VERSION ""

NS_ :

BS_:

BU_: TCM HCM IPMA_ADAS PSCM ABS_ESC TCCM TCM_DSL PCM_HEV PCM ECM_HEVDSL ECM_HEV ECM_Diesel ECM SIMA_DLCS BCMD_IPDB VDM CMR_DSMC SOBDMC_HPCM CHCM GWM _delete AWD_DLCM GENERIC TSTR

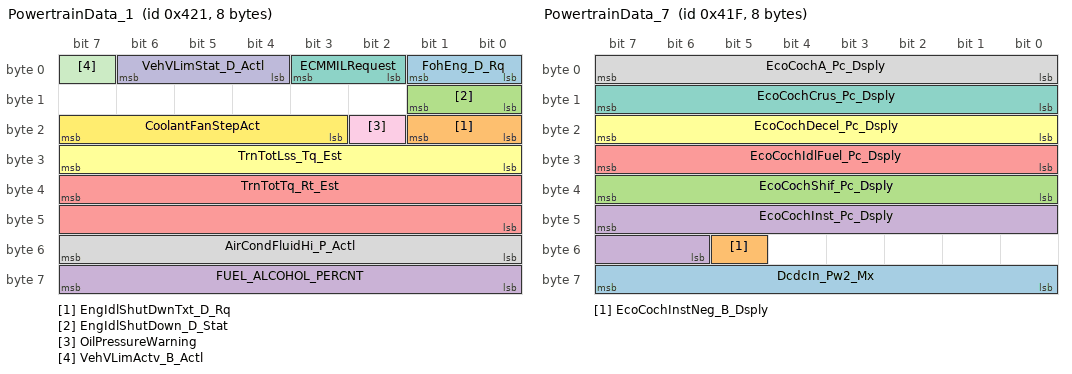
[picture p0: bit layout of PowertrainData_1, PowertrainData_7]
BO_ 1057 PowertrainData_1: 8 PCM_HEV
 SG_ FohEng_D_Rq : 1|2@0+ (1,0) [0|3] "SED"  GWM
 SG_ EngIdlShutDwnTxt_D_Rq : 17|2@0+ (1,0) [0|3] "SED"  GWM
 SG_ EngIdlShutDown_D_Stat : 9|2@0+ (1,0) [0|3] "SED"  GWM
 SG_ FUEL_ALCOHOL_PERCNT : 63|8@0+ (0.393700787,0) [0|99.999899898] "Percent"  GWM
 SG_ TrnTotTq_Rt_Est : 39|16@0+ (0.001,0) [0|65.533] "Unitless"  ABS_ESC,TCM,GWM,TCM_DSL
 SG_ TrnTotLss_Tq_Est : 31|8@0+ (0.5,0) [0|126.5] "Nm"  ABS_ESC,TCM,GWM,TCM_DSL
 SG_ ECMMILRequest : 3|2@0+ (1,0) [0|3] "SED"  GWM
 SG_ AirCondFluidHi_P_Actl : 55|8@0+ (0.125,0) [0|31.625] "bar"  SOBDMC_HPCM,GWM
 SG_ OilPressureWarning : 18|1@0+ (1,0) [0|1] "SED"  GWM
 SG_ VehVLimStat_D_Actl : 6|3@0+ (1,0) [0|7] "SED"  TCM,GWM,TCM_DSL
 SG_ VehVLimActv_B_Actl : 7|1@0+ (1,0) [0|1] "SED"  SOBDMC_HPCM,TCM,GWM,TCM_DSL
 SG_ CoolantFanStepAct : 23|5@0+ (1,0) [0|31] "Steps"  GWM

BO_ 1055 PowertrainData_7: 8 PCM_HEV
 SG_ DcdcIn_Pw2_Mx : 63|8@0+ (20,500) [500|5600] "watts"  GWM
 SG_ EcoCochInstNeg_B_Dsply : 53|1@0+ (1,0) [0|1] "SED"  GWM
 SG_ EcoCochShif_Pc_Dsply : 39|8@0+ (0.392157,0) [0|100.000035] "percent"  GWM
 SG_ EcoCochInst_Pc_Dsply : 47|10@0+ (0.1,0) [0|102.3] "percent"  GWM
 SG_ EcoCochIdlFuel_Pc_Dsply : 31|8@0+ (0.392157,0) [0|100.000035] "percent"  GWM
 SG_ EcoCochDecel_Pc_Dsply : 23|8@0+ (0.392157,0) [0|100.000035] "percent"  GWM
 SG_ EcoCochCrus_Pc_Dsply : 15|8@0+ (0.392157,0) [0|100.000035] "percent"  GWM
 SG_ EcoCochA_Pc_Dsply : 7|8@0+ (0.392157,0) [0|100.000035] "percent"  GWM

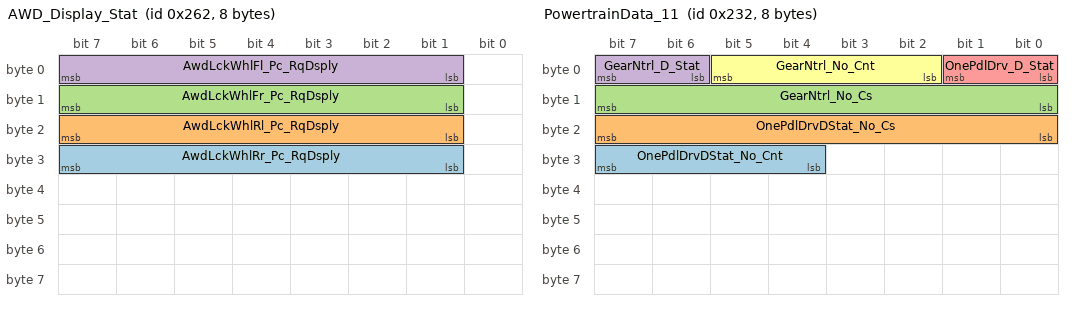
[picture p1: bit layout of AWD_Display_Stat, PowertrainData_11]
BO_ 610 AWD_Display_Stat: 8 AWD_DLCM
 SG_ AwdLckWhlRr_Pc_RqDsply : 31|7@0+ (1,0) [0|127] "percent"  GWM
 SG_ AwdLckWhlRl_Pc_RqDsply : 23|7@0+ (1,0) [0|127] "percent"  GWM
 SG_ AwdLckWhlFr_Pc_RqDsply : 15|7@0+ (1,0) [0|127] "percent"  GWM
 SG_ AwdLckWhlFl_Pc_RqDsply : 7|7@0+ (1,0) [0|127] "percent"  GWM

BO_ 562 PowertrainData_11: 8 ECM
 SG_ OnePdlDrvDStat_No_Cnt : 31|4@0+ (1,0) [0|15] "Unitless"  ABS_ESC,SOBDMC_HPCM
 SG_ OnePdlDrvDStat_No_Cs : 23|8@0+ (1,0) [0|255] "Unitless"  ABS_ESC,SOBDMC_HPCM
 SG_ GearNtrl_No_Cs : 15|8@0+ (1,0) [0|255] "unitless"  ABS_ESC,GWM
 SG_ GearNtrl_D_Stat : 7|2@0+ (1,0) [0|3] "SED"  ABS_ESC,GWM
 SG_ OnePdlDrv_D_Stat : 1|2@0+ (1,0) [0|3] "SED"  ABS_ESC,SOBDMC_HPCM
 SG_ GearNtrl_No_Cnt : 5|4@0+ (1,0) [0|15] "unitless"  ABS_ESC,GWM

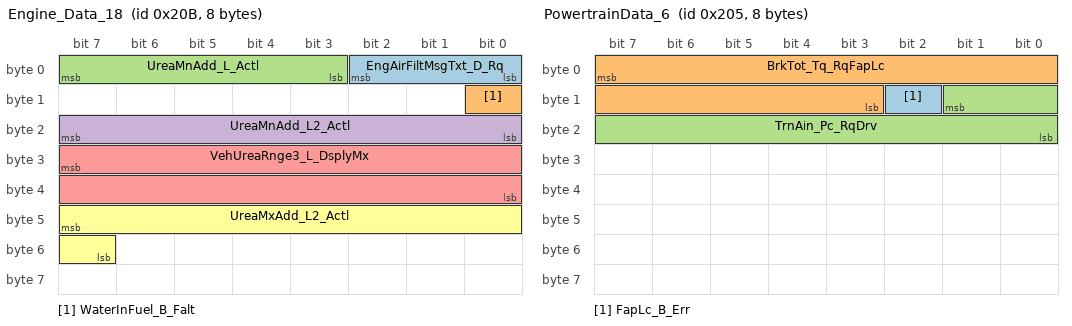
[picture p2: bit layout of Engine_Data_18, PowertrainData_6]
BO_ 523 Engine_Data_18: 8 PCM
 SG_ EngAirFiltMsgTxt_D_Rq : 2|3@0+ (1,0) [0|7] "SED"  GWM
 SG_ WaterInFuel_B_Falt : 8|1@0+ (1,0) [0|1] "SED"  GWM
 SG_ UreaMnAdd_L_Actl : 7|5@0+ (1,0) [0|31] "litre"  GWM
 SG_ UreaMnAdd_L2_Actl : 23|8@0+ (0.1,0) [0|25.4] "litre"  GWM
 SG_ VehUreaRnge3_L_DsplyMx : 31|16@0+ (1,0) [0|65535] "unitless"  GWM
 SG_ UreaMxAdd_L2_Actl : 47|9@0+ (0.1,0) [0|51] "litre"  GWM

BO_ 519 PowertrainData_8: 8 ECM
 SG_ RearDiffLck_Tq_Rq : 7|14@0+ (1,0) [0|16381] "Nm"  GWM

BO_ 517 PowertrainData_6: 8 PCM_HEV
 SG_ FapLc_B_Err : 10|1@0+ (1,0) [0|1] "SED"  IPMA_ADAS,GWM
 SG_ BrkTot_Tq_RqFapLc : 7|13@0+ (4,0) [0|32764] "Nm"  ABS_ESC,GWM
 SG_ TrnAin_Pc_RqDrv : 9|10@0+ (0.1,0) [0|102.3] "percent"  GWM,AWD_DLCM,TCCM

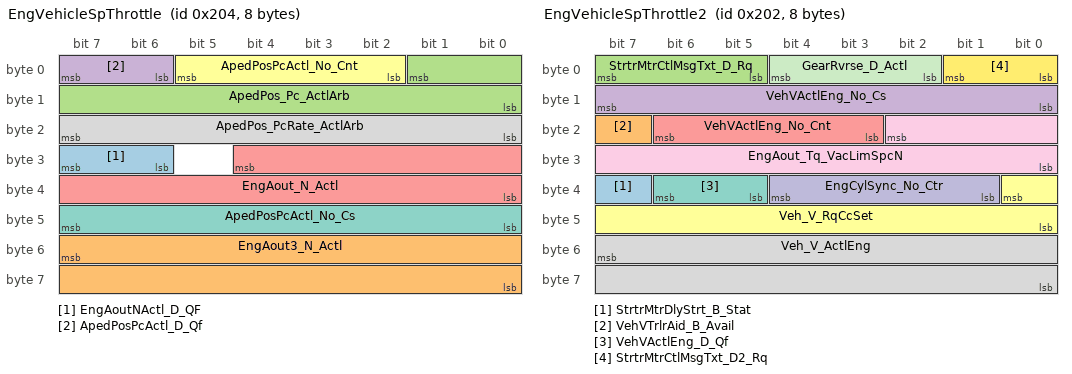
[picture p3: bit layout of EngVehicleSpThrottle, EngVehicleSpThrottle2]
BO_ 516 EngVehicleSpThrottle: 8 PCM_HEV
 SG_ EngAoutNActl_D_QF : 31|2@0+ (1,0) [0|3] "SED"  TCM,TCM_DSL,GWM
 SG_ EngAout3_N_Actl : 55|16@0+ (0.25,0) [0|16383.5] "RPM"  SOBDMC_HPCM,GWM
 SG_ ApedPos_Pc_ActlArb : 1|10@0+ (0.1,0) [0|102.3] "%"  TCM,CMR_DSMC,VDM,SOBDMC_HPCM,HCM,IPMA_ADAS,TCCM,ABS_ESC,PSCM,TCM_DSL,GWM,AWD_DLCM
 SG_ ApedPosPcActl_D_Qf : 7|2@0+ (1,0) [0|3] "SED"  CMR_DSMC,TCM,VDM,SOBDMC_HPCM,HCM,IPMA_ADAS,ABS_ESC,PSCM,TCM_DSL,GWM,AWD_DLCM
 SG_ EngAout_N_Actl : 28|13@0+ (2,0) [0|16382] "rpm"  TCM,VDM,HCM,ABS_ESC,PSCM,TCCM,TCM_DSL,GWM,AWD_DLCM
 SG_ ApedPosPcActl_No_Cnt : 5|4@0+ (1,0) [0|15] "Unitless"  TCM,SOBDMC_HPCM,ABS_ESC,TCM_DSL,GWM
 SG_ ApedPosPcActl_No_Cs : 47|8@0+ (1,0) [0|255] "Unitless"  TCM,SOBDMC_HPCM,ABS_ESC,TCM_DSL,GWM
 SG_ ApedPos_PcRate_ActlArb : 23|8@0+ (0.04,-5) [-5|5.12] "%/ms"  SOBDMC_HPCM,AWD_DLCM,TCM,TCM_DSL,GWM

BO_ 514 EngVehicleSpThrottle2: 8 PCM_HEV
 SG_ StrtrMtrDlyStrt_B_Stat : 39|1@0+ (1,0) [0|1] "SED"  GWM
 SG_ VehVTrlrAid_B_Avail : 23|1@0+ (1,0) [0|1] "SED"  PSCM,GWM
 SG_ StrtrMtrCtlMsgTxt_D_Rq : 7|3@0+ (1,0) [0|7] "SED"  GWM
 SG_ VehVActlEng_No_Cs : 15|8@0+ (1,0) [0|255] "Unitless"  ABS_ESC,PSCM,GWM
 SG_ VehVActlEng_No_Cnt : 22|4@0+ (1,0) [0|15] "Unitless"  ABS_ESC,PSCM,GWM
 SG_ Veh_V_RqCcSet : 32|9@0+ (0.5,0) [0|255.5] "kph"  TCM,IPMA_ADAS,PSCM,ABS_ESC,TCM_DSL,GWM,SOBDMC_HPCM
 SG_ VehVActlEng_D_Qf : 38|2@0+ (1,0) [0|3] "SED"  TCM,HCM,IPMA_ADAS,ABS_ESC,PSCM,TCM_DSL,GWM,VDM,AWD_DLCM
 SG_ Veh_V_ActlEng : 55|16@0+ (0.01,0) [0|655.35] "kph"  TCM,SOBDMC_HPCM,HCM,IPMA_ADAS,ABS_ESC,PSCM,TCM_DSL,VDM,GWM,AWD_DLCM
 SG_ EngAout_Tq_VacLimSpcN : 18|11@0+ (1,-500) [-500|1547] "Nm"  SOBDMC_HPCM,GWM
 SG_ EngCylSync_No_Ctr : 36|4@0+ (1,0) [0|15] "unitless"  SOBDMC_HPCM,GWM
 SG_ GearRvrse_D_Actl : 4|3@0+ (1,0) [0|7] "SED"  AWD_DLCM,IPMA_ADAS,CMR_DSMC,ABS_ESC,PSCM,GWM,VDM,HCM,CHCM
 SG_ StrtrMtrCtlMsgTxt_D2_Rq : 1|2@0+ (1,0) [0|3] "SED"  GWM

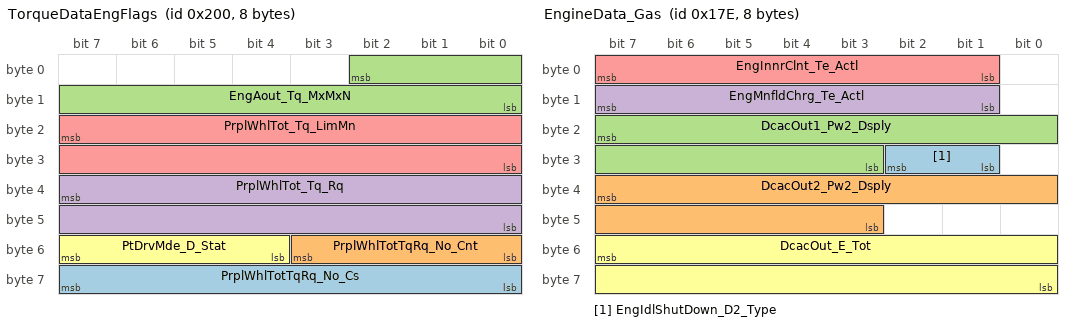
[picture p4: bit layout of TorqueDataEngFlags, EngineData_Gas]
BO_ 512 TorqueDataEngFlags: 8 PCM_HEV
 SG_ PrplWhlTotTqRq_No_Cs : 63|8@0+ (1,0) [0|255] "Unitless"  SOBDMC_HPCM,ABS_ESC,GWM
 SG_ PrplWhlTotTqRq_No_Cnt : 51|4@0+ (1,0) [0|15] "Unitless"  SOBDMC_HPCM,ABS_ESC,GWM
 SG_ EngAout_Tq_MxMxN : 2|11@0+ (1,-500) [-500|1547] "Nm"  SOBDMC_HPCM,GWM
 SG_ PrplWhlTot_Tq_Rq : 39|16@0+ (4,-131072) [-131072|131068] "Nm"  VDM,SOBDMC_HPCM,TCCM,ABS_ESC,GWM,AWD_DLCM
 SG_ PrplWhlTot_Tq_LimMn : 23|16@0+ (4,-131072) [-131072|131068] "Nm"  ABS_ESC,GWM
 SG_ PtDrvMde_D_Stat : 55|4@0+ (1,0) [0|15] "SED"  IPMA_ADAS,ABS_ESC,GWM

BO_ 382 EngineData_Gas: 8 ECM_HEV
 SG_ EngIdlShutDown_D2_Type : 26|2@0+ (1,0) [0|3] "SED"  GWM
 SG_ DcacOut2_Pw2_Dsply : 39|13@0+ (1,0) [0|8189] "watts"  GWM
 SG_ DcacOut1_Pw2_Dsply : 23|13@0+ (1,0) [0|8189] "watts"  GWM
 SG_ EngMnfldChrg_Te_Actl : 15|7@0+ (1,-20) [-20|105] "degC"  GWM
 SG_ EngInnrClnt_Te_Actl : 7|7@0+ (1,50) [50|175] "degC"  GWM
 SG_ DcacOut_E_Tot : 55|16@0+ (20,0) [0|1310700] "watt*hour"  GWM

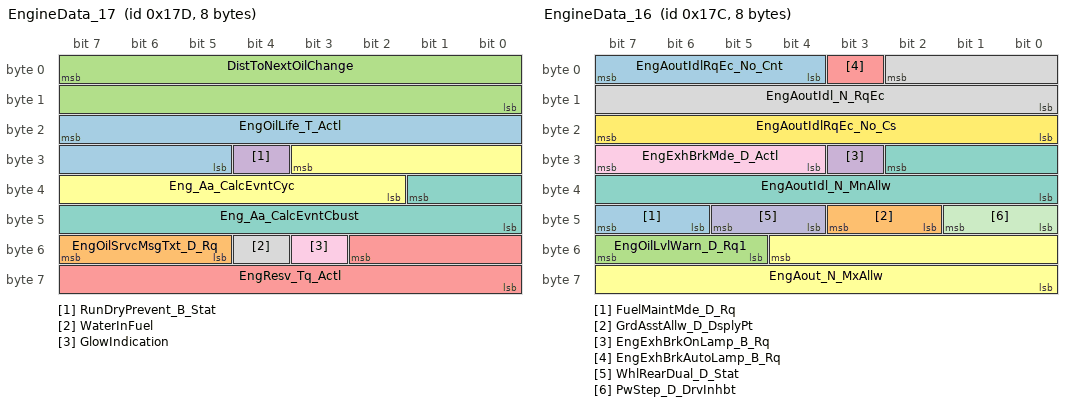
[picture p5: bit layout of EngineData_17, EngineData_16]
BO_ 381 EngineData_17: 8 ECM_HEVDSL
 SG_ EngOilLife_T_Actl : 23|11@0+ (1,0) [0|2047] "days"  GWM
 SG_ EngOilSrvcMsgTxt_D_Rq : 55|3@0+ (1,0) [0|7] "SED"  GWM
 SG_ DistToNextOilChange : 7|16@0+ (1,0) [0|65535] "unitless"  GWM
 SG_ RunDryPrevent_B_Stat : 28|1@0+ (1,0) [0|1] "SED"  GWM
 SG_ EngResv_Tq_Actl : 50|11@0+ (1,-500) [-500|1547] "Nm"  GWM
 SG_ Eng_Aa_CalcEvntCyc : 27|10@0+ (0.05,-25.6) [-25.6|25.55] "rpm/ms"  GWM
 SG_ Eng_Aa_CalcEvntCbust : 33|10@0+ (0.05,-25.6) [-25.6|25.55] "rpm/ms"  GWM
 SG_ WaterInFuel : 52|1@0+ (1,0) [0|1] "SED"  GWM
 SG_ GlowIndication : 51|1@0+ (1,0) [0|1] "SED"  GWM

BO_ 380 EngineData_16: 8 PCM
 SG_ FuelMaintMde_D_Rq : 47|2@0+ (1,0) [0|3] "SED"  SOBDMC_HPCM,GWM
 SG_ GrdAsstAllw_D_DsplyPt : 43|2@0+ (1,0) [0|3] "SED"  SOBDMC_HPCM,GWM
 SG_ EngOilLvlWarn_D_Rq1 : 55|3@0+ (1,0) [0|7] "SED"  PCM,GWM,PCM_HEV
 SG_ EngExhBrkOnLamp_B_Rq : 27|1@0+ (1,0) [0|1] "SED"  GWM
 SG_ EngExhBrkAutoLamp_B_Rq : 3|1@0+ (1,0) [0|1] "SED"  GWM
 SG_ EngAout_N_MxAllw : 52|13@0+ (2,0) [0|16382] "rpm"  TCM,SOBDMC_HPCM,TCM_DSL,GWM
 SG_ EngAoutIdl_N_MnAllw : 26|11@0+ (2,0) [0|4094] "rpm"  GWM
 SG_ EngAoutIdl_N_RqEc : 2|11@0+ (2,0) [0|4094] "rpm"  GWM
 SG_ EngExhBrkMde_D_Actl : 31|4@0+ (1,0) [0|15] "SED"  TCM,TCM_DSL,GWM
 SG_ WhlRearDual_D_Stat : 45|2@0+ (1,0) [0|3] "SED"  TCM,TCM_DSL,GWM
 SG_ PwStep_D_DrvInhbt : 41|2@0+ (1,0) [0|3] "SED"  GWM
 SG_ EngAoutIdlRqEc_No_Cs : 23|8@0+ (1,0) [0|255] "unitless"  GWM
 SG_ EngAoutIdlRqEc_No_Cnt : 7|4@0+ (1,0) [0|15] "unitless"  GWM

BO_ 377 EngineData_7: 8 PCM_HEV
 SG_ HvacAirFullOut_B_Rq : 23|1@0+ (1,0) [0|1] "SED"  GWM
 SG_ TrnManShif_D_IndDrv : 7|3@0+ (1,0) [0|7] "Unitless"  GWM
 SG_ EngAout_Tq_Actl : 2|11@0+ (1,-500) [-500|1547] "Nm"  SOBDMC_HPCM,GWM
 SG_ TrnManShifGear_D_IndDrv : 54|3@0+ (1,0) [0|7] "SED"  GWM
 SG_ EngFuelCutFull_B_Inhbt : 22|1@0+ (1,0) [0|1] "SED"  SOBDMC_HPCM,GWM
 SG_ EngDecelFuelCut_B_Allw : 21|1@0+ (1,0) [0|1] "SED"  TCM,TCM_DSL,GWM
 SG_ FuelFlw_Vl_Dsply : 49|10@0+ (25,0) [0|25575] "Micro_Liter"  SOBDMC_HPCM,GWM
 SG_ FuelFillInlet_B_Dsply : 32|1@0+ (1,0) [0|1] "SED"  GWM
 SG_ EngSrvcRqd_B_Rq : 19|1@0+ (1,0) [0|1] "SED"  GWM
 SG_ OdoCount : 47|8@0+ (0.2,0) [0|50.8] "Meters"  GWM
 SG_ EngOilLife_Pc_Actl : 39|7@0+ (1,0) [0|100] "Percent"  GWM
 SG_ EngTqSlwDly_T_Est : 18|11@0+ (1,0) [0|2047] "ms"  TCM,TCM_DSL,GWM
 SG_ TrnKickDown_B_RqDrv : 20|1@0+ (1,0) [0|1] "SED"  TCM,TCM_DSL,GWM
 SG_ FuelFilterLamp_B_Dsply : 50|1@0+ (1,0) [0|1] "SED"  GWM
 SG_ AirCondRec_B_Rq : 55|1@0+ (1,0) [0|1] "SED"  GWM
 SG_ AirCondClutch_B_Stats : 51|1@0+ (1,0) [0|1] "SED"  TCM,TCM_DSL,GWM
 SG_ EngAoutTqActl_D_Qf : 4|2@0+ (1,0) [0|3] "SED"  SOBDMC_HPCM,GWM

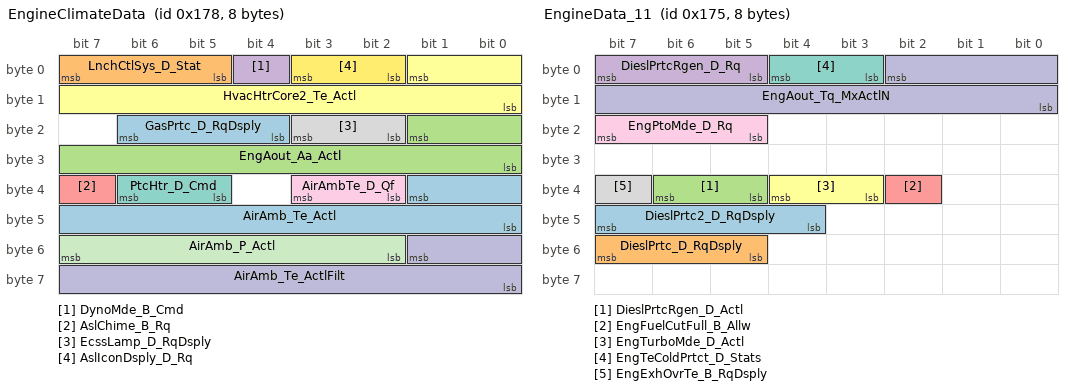
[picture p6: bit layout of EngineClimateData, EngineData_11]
BO_ 376 EngineClimateData: 8 PCM_HEV
 SG_ GasPrtc_D_RqDsply : 22|3@0+ (1,0) [0|7] "SED"  GWM
 SG_ LnchCtlSys_D_Stat : 7|3@0+ (1,0) [0|7] "SED"  ABS_ESC,GWM
 SG_ EngAout_Aa_Actl : 17|10@0+ (0.05,-25.6) [-25.6|25.55] "rpm/ms"  TCM,TCM_DSL,ABS_ESC,GWM
 SG_ DynoMde_B_Cmd : 4|1@0+ (1,0) [0|1] "SED"  SOBDMC_HPCM,TCM,TCM_DSL,ABS_ESC,GWM
 SG_ AslChime_B_Rq : 39|1@0+ (1,0) [0|1] "SED"  GWM
 SG_ HvacHtrCore2_Te_Actl : 1|10@0+ (0.25,-50) [-50|205.5] "degC"  SOBDMC_HPCM,GWM
 SG_ PtcHtr_D_Cmd : 38|2@0+ (1,0) [0|3] "SED"  SOBDMC_HPCM,GWM
 SG_ EcssLamp_D_RqDsply : 19|2@0+ (1,0) [0|3] "SED"  GWM
 SG_ AirAmbTe_D_Qf : 35|2@0+ (1,0) [0|3] "SED"  TCM,SOBDMC_HPCM,IPMA_ADAS,TCM_DSL,ABS_ESC,TCCM,GWM,VDM,AWD_DLCM,CHCM
 SG_ AirAmb_Te_ActlFilt : 49|10@0+ (0.25,-128) [-128|127.75] "deg C"  TCM,SOBDMC_HPCM,IPMA_ADAS,TCM_DSL,VDM,GWM,CHCM
 SG_ AirAmb_P_Actl : 55|6@0+ (10,500) [500|1110] "mbar"  TCM,TCM_DSL,ABS_ESC,GWM,VDM
 SG_ AslIconDsply_D_Rq : 3|2@0+ (1,0) [0|3] "SED"  IPMA_ADAS,GWM
 SG_ AirAmb_Te_Actl : 33|10@0+ (0.25,-128) [-128|127.75] "degC"  VDM,TCM_DSL,TCM,TCCM,HCM,AWD_DLCM,ABS_ESC,GWM,CHCM

BO_ 373 EngineData_11: 8 ECM_HEVDSL
 SG_ DieslPrtc2_D_RqDsply : 47|4@0+ (1,0) [0|15] "SED"  GWM
 SG_ DieslPrtc_D_RqDsply : 55|3@0+ (1,0) [0|7] "SED"  GWM
 SG_ DieslPrtcRgen_D_Actl : 38|2@0+ (1,0) [0|3] "SED"  TCM,TCM_DSL,GWM
 SG_ DieslPrtcRgen_D_Rq : 7|3@0+ (1,0) [0|7] "SED"  GWM
 SG_ EngFuelCutFull_B_Allw : 34|1@0+ (1,0) [0|1] "SED"  SOBDMC_HPCM,GWM
 SG_ EngTurboMde_D_Actl : 36|2@0+ (1,0) [0|3] "SED"  TCM,TCM_DSL,GWM
 SG_ EngTeColdPrtct_D_Stats : 4|2@0+ (1,0) [0|3] "SED"  GWM
 SG_ EngExhOvrTe_B_RqDsply : 39|1@0+ (1,0) [0|1] "SED"  GWM
 SG_ EngPtoMde_D_Rq : 23|3@0+ (1,0) [0|7] "SED"  TCM,TCM_DSL,GWM
 SG_ EngAout_Tq_MxActlN : 2|11@0+ (1,-500) [-500|1547] "Nm"  GWM,GENERIC

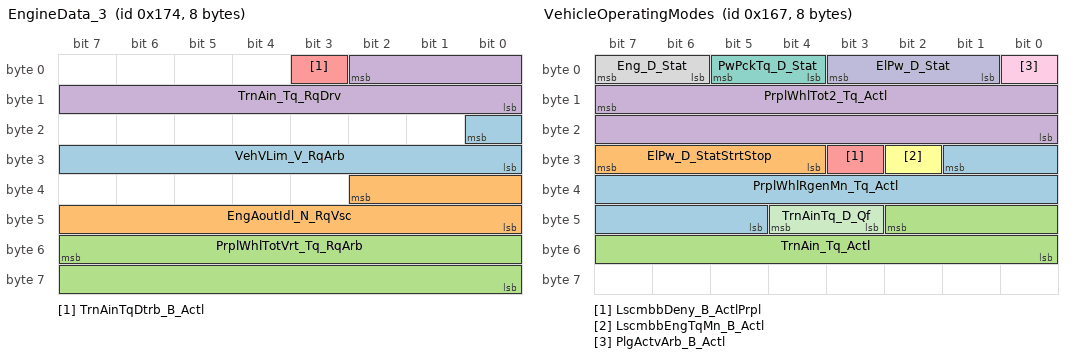
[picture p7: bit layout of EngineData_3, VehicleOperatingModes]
BO_ 372 EngineData_3: 8 ECM
 SG_ VehVLim_V_RqArb : 16|9@0+ (0.5,0) [0|255.5] "kph"  TCM,TCM_DSL,GWM
 SG_ EngAoutIdl_N_RqVsc : 34|11@0+ (2,0) [0|4094] "rpm"  TCM,TCM_DSL,ABS_ESC,GWM
 SG_ PrplWhlTotVrt_Tq_RqArb : 55|16@0+ (4,-131072) [-131072|131068] "Nm"  TCM,TCM_DSL,GWM
 SG_ TrnAin_Tq_RqDrv : 2|11@0+ (1,-500) [-500|1547] "Nm"  TCM,TCM_DSL,GWM
 SG_ TrnAinTqDtrb_B_Actl : 3|1@0+ (1,0) [0|1] "SED"  TCM,TCM_DSL,GWM

BO_ 359 VehicleOperatingModes: 8 PCM_HEV
 SG_ PrplWhlRgenMn_Tq_Actl : 25|13@0+ (4,-16380) [-16380|16380] "Nm"  ABS_ESC,GWM,AWD_DLCM
 SG_ ElPw_D_StatStrtStop : 31|4@0+ (1,0) [0|15] "SED"  PSCM,GWM,ABS_ESC
 SG_ TrnAin_Tq_Actl : 42|11@0+ (1,-500) [-500|1547] "Nm"  TCM,ABS_ESC,TCM_DSL,GWM,AWD_DLCM
 SG_ PrplWhlTot2_Tq_Actl : 15|16@0+ (4,-131072) [-131072|131060] "Nm"  VDM,ABS_ESC,ECM_HEV,PSCM,TCCM,GWM,AWD_DLCM
 SG_ LscmbbDeny_B_ActlPrpl : 27|1@0+ (1,0) [0|1] "SED"  ABS_ESC,GWM
 SG_ LscmbbEngTqMn_B_Actl : 26|1@0+ (1,0) [0|1] "SED"  ABS_ESC,GWM
 SG_ PwPckTq_D_Stat : 5|2@0+ (1,0) [0|3] "SED"  TCM,SOBDMC_HPCM,VDM,HCM,IPMA_ADAS,ABS_ESC,ECM_HEV,PSCM,TCCM,TCM_DSL,CMR_DSMC,GWM,AWD_DLCM,CHCM
 SG_ Eng_D_Stat : 7|2@0+ (1,0) [0|3] "SED"  TCM,VDM,ABS_ESC,TCM_DSL,GWM,AWD_DLCM
 SG_ PlgActvArb_B_Actl : 0|1@0+ (1,0) [0|1] "SED"  SOBDMC_HPCM,GWM,ECM_HEV
 SG_ ElPw_D_Stat : 3|3@0+ (1,0) [0|7] "SED"  TCM,VDM,HCM,IPMA_ADAS,ABS_ESC,ECM_HEV,PSCM,TCCM,TCM_DSL,GWM,CMR_DSMC,AWD_DLCM,CHCM
 SG_ TrnAinTq_D_Qf : 44|2@0+ (1,0) [0|3] "SED"  TCM,ABS_ESC,TCM_DSL,GWM,AWD_DLCM

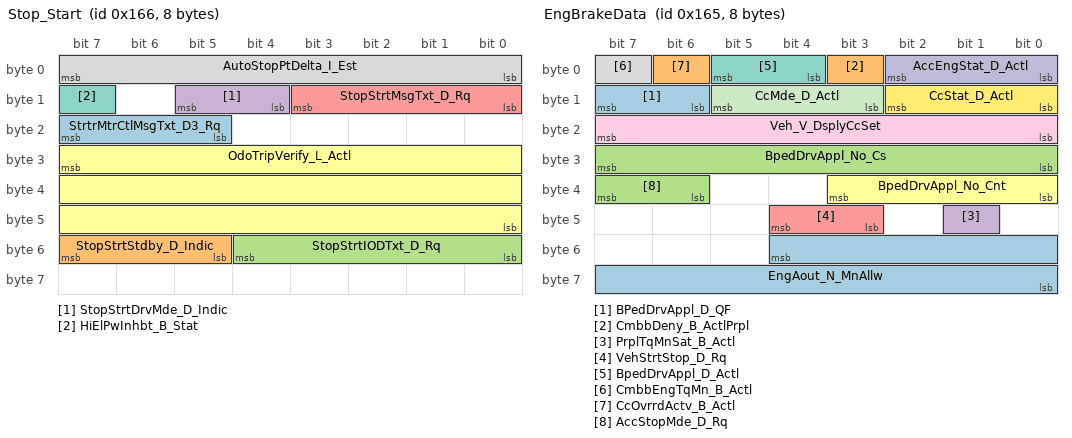
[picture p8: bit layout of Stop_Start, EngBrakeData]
BO_ 358 Stop_Start: 8 PCM_HEV
 SG_ StrtrMtrCtlMsgTxt_D3_Rq : 23|3@0+ (1,0) [0|7] "SED"  GWM
 SG_ StopStrtStdby_D_Indic : 55|3@0+ (1,0) [0|7] "SED"  GWM
 SG_ StopStrtIODTxt_D_Rq : 52|5@0+ (1,0) [0|31] "SED"  GWM
 SG_ StopStrtDrvMde_D_Indic : 13|2@0+ (1,0) [0|3] "SED"  GWM
 SG_ StopStrtMsgTxt_D_Rq : 11|4@0+ (1,0) [0|15] "SED"  GWM
 SG_ OdoTripVerify_L_Actl : 31|24@0+ (0.1,0) [0|1677721.4] "km"  GWM
 SG_ HiElPwInhbt_B_Stat : 15|1@0+ (1,0) [0|1] "SED"  GWM
 SG_ AutoStopPtDelta_I_Est : 7|8@0+ (1,-127) [-127|127] "Amps"  GWM

BO_ 357 EngBrakeData: 8 PCM_HEV
 SG_ BPedDrvAppl_D_QF : 15|2@0+ (1,0) [0|3] "SED"  TCM,SOBDMC_HPCM,IPMA_ADAS,ABS_ESC,PSCM,TCM_DSL,GWM,VDM,CMR_DSMC,AWD_DLCM
 SG_ CmbbDeny_B_ActlPrpl : 3|1@0+ (1,0) [0|1] "SED"  IPMA_ADAS,GWM
 SG_ BpedDrvAppl_No_Cs : 31|8@0+ (1,0) [0|255] "Unitless"  SOBDMC_HPCM,GWM
 SG_ PrplTqMnSat_B_Actl : 41|1@0+ (1,0) [0|1] "SED"  IPMA_ADAS,GWM
 SG_ VehStrtStop_D_Rq : 44|2@0+ (1,0) [0|3] "SED"  SOBDMC_HPCM,GWM
 SG_ BpedDrvAppl_No_Cnt : 35|4@0+ (1,0) [0|15] "Unitless"  SOBDMC_HPCM,GWM
 SG_ BpedDrvAppl_D_Actl : 5|2@0+ (1,0) [0|3] "SED"  TCM,SOBDMC_HPCM,IPMA_ADAS,ABS_ESC,PSCM,TCCM,TCM_DSL,VDM,GWM,CMR_DSMC,AWD_DLCM
 SG_ CmbbEngTqMn_B_Actl : 7|1@0+ (1,0) [0|1] "SED"  IPMA_ADAS,GWM
 SG_ Veh_V_DsplyCcSet : 23|8@0+ (1,0) [0|253] "Unitless"  GWM,IPMA_ADAS
 SG_ AccEngStat_D_Actl : 2|3@0+ (1,0) [0|7] "SED"  IPMA_ADAS,GWM
 SG_ CcMde_D_Actl : 13|3@0+ (1,0) [0|7] "SED"  TCM,TCM_DSL,ABS_ESC,GWM,VDM
 SG_ CcStat_D_Actl : 10|3@0+ (1,0) [0|7] "SED"  TCM,SOBDMC_HPCM,IPMA_ADAS,ABS_ESC,TCCM,TCM_DSL,GWM,CMR_DSMC,AWD_DLCM
 SG_ EngAout_N_MnAllw : 52|13@0+ (2,0) [0|16382] "rpm"  TCM,SOBDMC_HPCM,TCM_DSL,GWM
 SG_ CcOvrrdActv_B_Actl : 6|1@0+ (1,0) [0|1] "SED"  TCM,IPMA_ADAS,ABS_ESC,TCCM,TCM_DSL,GWM,VDM,AWD_DLCM
 SG_ AccStopMde_D_Rq : 39|2@0+ (1,0) [0|3] "SED"  IPMA_ADAS,ABS_ESC,GWM

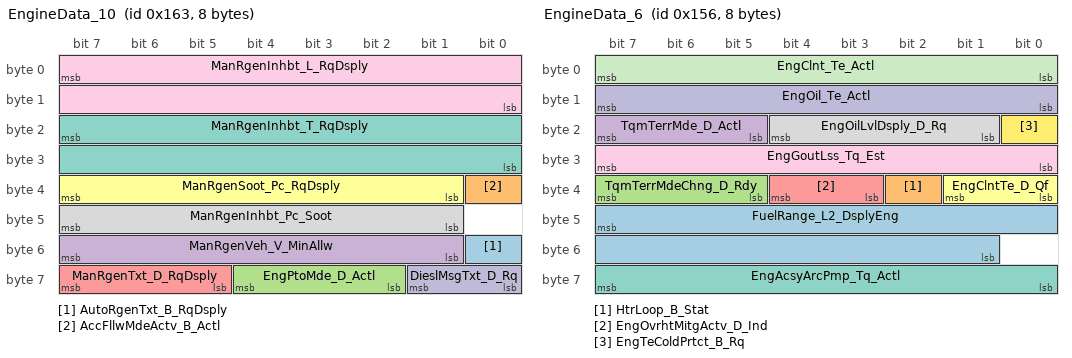
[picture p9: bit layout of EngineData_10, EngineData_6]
BO_ 355 EngineData_10: 8 ECM_HEVDSL
 SG_ AutoRgenTxt_B_RqDsply : 48|1@0+ (1,0) [0|1] "SED"  GWM
 SG_ AccFllwMdeActv_B_Actl : 32|1@0+ (1,0) [0|1] "SED"  TCM,TCM_DSL,GWM
 SG_ EngPtoMde_D_Actl : 60|3@0+ (1,0) [0|7] "SED"  TCM,TCM_DSL,GWM
 SG_ ManRgenVeh_V_MinAllw : 55|7@0+ (1,0) [0|126] "kilometer/hour"  GWM
 SG_ ManRgenTxt_D_RqDsply : 63|3@0+ (1,0) [0|7] "SED"  GWM
 SG_ ManRgenSoot_Pc_RqDsply : 39|7@0+ (1,0) [0|126] "%"  GWM
 SG_ ManRgenInhbt_T_RqDsply : 23|16@0+ (1,0) [0|65534] "Minutes"  GWM
 SG_ ManRgenInhbt_Pc_Soot : 47|7@0+ (1,0) [0|126] "%"  GWM
 SG_ ManRgenInhbt_L_RqDsply : 7|16@0+ (1,0) [0|65534] "kilometer"  GWM
 SG_ DieslMsgTxt_D_Rq : 57|2@0+ (1,0) [0|3] "SED"  GWM

BO_ 342 EngineData_6: 8 PCM_HEV
 SG_ FuelRange_L2_DsplyEng : 47|15@0+ (0.1,0) [0|3276.7] "kilometer"  GWM
 SG_ HtrLoop_B_Stat : 34|1@0+ (1,0) [0|1] "SED"  SOBDMC_HPCM,GWM
 SG_ TqmTerrMdeChng_D_Rdy : 39|3@0+ (1,0) [0|7] "SED"  GWM
 SG_ TqmTerrMde_D_Actl : 23|3@0+ (1,0) [0|7] "SED"  GWM
 SG_ EngOvrhtMitgActv_D_Ind : 36|2@0+ (1,0) [0|3] "SED"  GWM
 SG_ EngClntTe_D_Qf : 33|2@0+ (1,0) [0|3] "SED"  VDM,SOBDMC_HPCM,ABS_ESC,TCM,TCM_DSL,GWM,AWD_DLCM,CHCM
 SG_ EngAcsyArcPmp_Tq_Actl : 63|8@0+ (0.5,0) [0|126.5] "Nm"  TCM,TCM_DSL,GWM
 SG_ EngOilLvlDsply_D_Rq : 20|4@0+ (1,0) [0|15] "SED"  GWM
 SG_ EngGoutLss_Tq_Est : 31|8@0+ (1,0) [0|255] "Nm"  SOBDMC_HPCM,GWM
 SG_ EngOil_Te_Actl : 15|8@0+ (1,-60) [-60|193] "degC"  TCM,TCM_DSL,GWM,AWD_DLCM
 SG_ EngClnt_Te_Actl : 7|8@0+ (1,-60) [-60|195] "degC"  VDM,SOBDMC_HPCM,ABS_ESC,TCM,TCM_DSL,GWM,AWD_DLCM,CHCM
 SG_ EngTeColdPrtct_B_Rq : 16|1@0+ (1,0) [0|1] "SED"  GWM

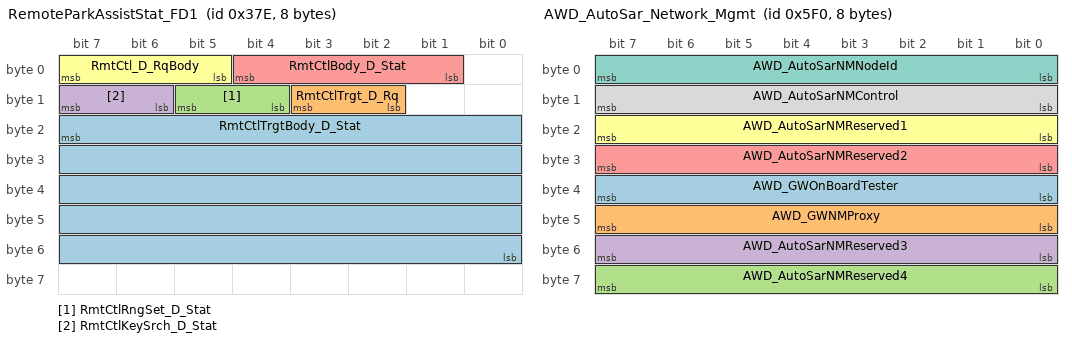
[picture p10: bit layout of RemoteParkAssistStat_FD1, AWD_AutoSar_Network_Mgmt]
BO_ 894 RemoteParkAssistStat_FD1: 8 BCM
 SG_ RmtCtlTrgtBody_D_Stat : 23|40@0+ (1,0) [0|1099511627775] "unitless"  GENERIC
 SG_ RmtCtlTrgt_D_Rq : 11|2@0+ (1,0) [0|3] "SED"  GENERIC
 SG_ RmtCtlRngSet_D_Stat : 13|2@0+ (1,0) [0|3] "SED"  GENERIC
 SG_ RmtCtlKeySrch_D_Stat : 15|2@0+ (1,0) [0|3] "SED"  IPMA_ADAS
 SG_ RmtCtlBody_D_Stat : 4|4@0+ (1,0) [0|15] "SED"  IPMA_ADAS
 SG_ RmtCtl_D_RqBody : 7|3@0+ (1,0) [0|7] "SED"  GENERIC

BO_ 1520 AWD_AutoSar_Network_Mgmt: 8 AWD_DLCM
 SG_ AWD_GWOnBoardTester : 39|8@0+ (1,0) [0|255] "unitless"  GENERIC
 SG_ AWD_GWNMProxy : 47|8@0+ (1,0) [0|255] "unitless"  GENERIC
 SG_ AWD_AutoSarNMReserved4 : 63|8@0+ (1,0) [0|255] "unitless"  GENERIC
 SG_ AWD_AutoSarNMReserved3 : 55|8@0+ (1,0) [0|255] "unitless"  GENERIC
 SG_ AWD_AutoSarNMReserved2 : 31|8@0+ (1,0) [0|255] "unitless"  GENERIC
 SG_ AWD_AutoSarNMReserved1 : 23|8@0+ (1,0) [0|255] "unitless"  GENERIC
 SG_ AWD_AutoSarNMNodeId : 7|8@0+ (1,0) [0|255] "unitless"  GENERIC
 SG_ AWD_AutoSarNMControl : 15|8@0+ (1,0) [0|255] "unitless"  GENERIC

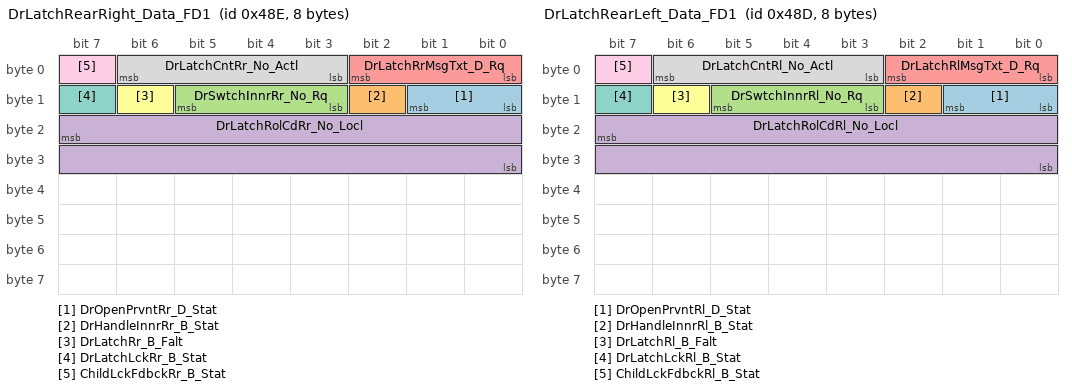
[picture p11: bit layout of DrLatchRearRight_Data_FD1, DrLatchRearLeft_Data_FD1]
BO_ 1166 DrLatchRearRight_Data_FD1: 8 DCMH
 SG_ DrOpenPrvntRr_D_Stat : 9|2@0+ (1,0) [0|3] "SED"  IPMA_ADAS
 SG_ DrHandleInnrRr_B_Stat : 10|1@0+ (1,0) [0|1] "SED"  IPMA_ADAS
 SG_ DrSwtchInnrRr_No_Rq : 13|3@0+ (1,0) [0|7] "unitless" Vector__XXX
 SG_ DrLatchRolCdRr_No_Locl : 23|16@0+ (1,0) [0|65535] "unitless" Vector__XXX
 SG_ DrLatchRrMsgTxt_D_Rq : 2|3@0+ (1,0) [0|7] "SED" Vector__XXX
 SG_ DrLatchRr_B_Falt : 14|1@0+ (1,0) [0|1] "SED" Vector__XXX
 SG_ DrLatchLckRr_B_Stat : 15|1@0+ (1,0) [0|1] "SED" Vector__XXX
 SG_ DrLatchCntRr_No_Actl : 6|4@0+ (1,0) [0|15] "unitless" Vector__XXX
 SG_ ChildLckFdbckRr_B_Stat : 7|1@0+ (1,0) [0|1] "SED" Vector__XXX

BO_ 1165 DrLatchRearLeft_Data_FD1: 8 DCMG
 SG_ DrOpenPrvntRl_D_Stat : 9|2@0+ (1,0) [0|3] "SED"  IPMA_ADAS
 SG_ DrHandleInnrRl_B_Stat : 10|1@0+ (1,0) [0|1] "SED"  IPMA_ADAS
 SG_ DrSwtchInnrRl_No_Rq : 13|3@0+ (1,0) [0|7] "unitless" Vector__XXX
 SG_ DrLatchRolCdRl_No_Locl : 23|16@0+ (1,0) [0|65535] "unitless" Vector__XXX
 SG_ DrLatchRlMsgTxt_D_Rq : 2|3@0+ (1,0) [0|7] "SED" Vector__XXX
 SG_ DrLatchRl_B_Falt : 14|1@0+ (1,0) [0|1] "SED" Vector__XXX
 SG_ DrLatchLckRl_B_Stat : 15|1@0+ (1,0) [0|1] "SED" Vector__XXX
 SG_ DrLatchCntRl_No_Actl : 6|4@0+ (1,0) [0|15] "unitless" Vector__XXX
 SG_ ChildLckFdbckRl_B_Stat : 7|1@0+ (1,0) [0|1] "SED" Vector__XXX

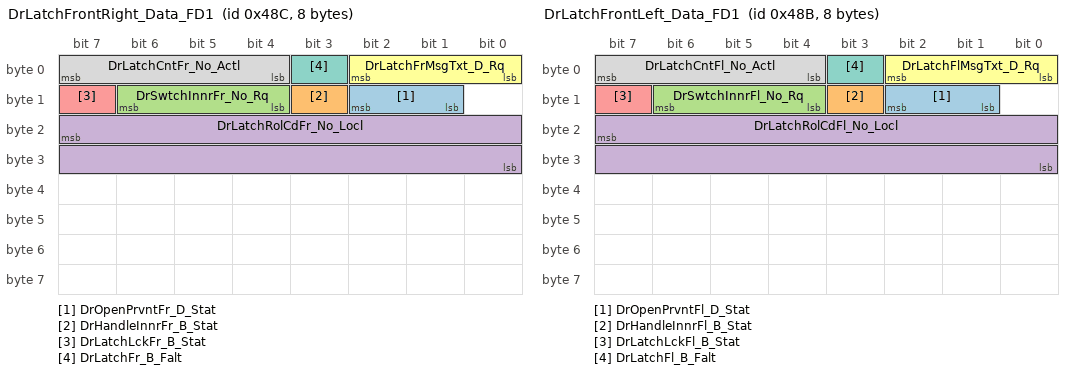
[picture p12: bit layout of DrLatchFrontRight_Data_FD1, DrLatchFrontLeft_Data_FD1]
BO_ 1164 DrLatchFrontRight_Data_FD1: 8 DCMF
 SG_ DrOpenPrvntFr_D_Stat : 10|2@0+ (1,0) [0|3] "SED"  IPMA_ADAS
 SG_ DrHandleInnrFr_B_Stat : 11|1@0+ (1,0) [0|1] "SED"  IPMA_ADAS
 SG_ DrSwtchInnrFr_No_Rq : 14|3@0+ (1,0) [0|7] "unitless" Vector__XXX
 SG_ DrLatchRolCdFr_No_Locl : 23|16@0+ (1,0) [0|65535] "unitless" Vector__XXX
 SG_ DrLatchLckFr_B_Stat : 15|1@0+ (1,0) [0|1] "SED" Vector__XXX
 SG_ DrLatchFrMsgTxt_D_Rq : 2|3@0+ (1,0) [0|7] "SED" Vector__XXX
 SG_ DrLatchFr_B_Falt : 3|1@0+ (1,0) [0|1] "SED" Vector__XXX
 SG_ DrLatchCntFr_No_Actl : 7|4@0+ (1,0) [0|15] "unitless" Vector__XXX

BO_ 1163 DrLatchFrontLeft_Data_FD1: 8 DCME
 SG_ DrOpenPrvntFl_D_Stat : 10|2@0+ (1,0) [0|3] "SED"  IPMA_ADAS
 SG_ DrHandleInnrFl_B_Stat : 11|1@0+ (1,0) [0|1] "SED"  IPMA_ADAS
 SG_ DrSwtchInnrFl_No_Rq : 14|3@0+ (1,0) [0|7] "unitless" Vector__XXX
 SG_ DrLatchRolCdFl_No_Locl : 23|16@0+ (1,0) [0|65535] "unitless" Vector__XXX
 SG_ DrLatchLckFl_B_Stat : 15|1@0+ (1,0) [0|1] "SED" Vector__XXX
 SG_ DrLatchFlMsgTxt_D_Rq : 2|3@0+ (1,0) [0|7] "SED" Vector__XXX
 SG_ DrLatchFl_B_Falt : 3|1@0+ (1,0) [0|1] "SED" Vector__XXX
 SG_ DrLatchCntFl_No_Actl : 7|4@0+ (1,0) [0|15] "unitless" Vector__XXX

BO_ 71 Global_PATS_TargetInfo: 8 SOBDMC_HPCM
 SG_ immoTarget1Status : 7|3@0+ (1,0) [0|7] "SED"  ECM_HEV,TCM,ABS_ESC,TCM_DSL,GWM
 SG_ immoTarget1Data : 15|40@0+ (1,0) [0|1099511627775] "Encrypted"  ABS_ESC,GWM
 SG_ immoTarget1Cmd : 4|3@0+ (1,0) [0|7] "SED"  ABS_ESC,GWM

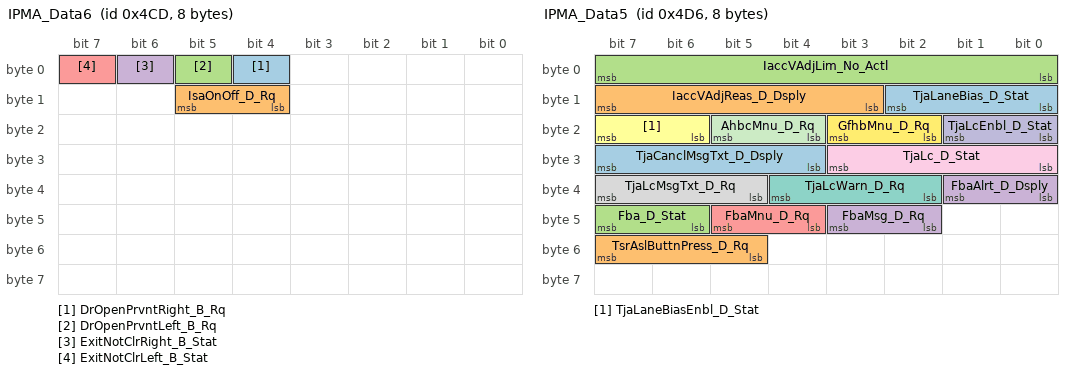
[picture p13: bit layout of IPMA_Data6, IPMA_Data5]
BO_ 1229 IPMA_Data6: 8 IPMA_ADAS
 SG_ DrOpenPrvntRight_B_Rq : 4|1@0+ (1,0) [0|1] "SED"  GWM
 SG_ IsaOnOff_D_Rq : 13|2@0+ (1,0) [0|3] "SED"  ECM,ECM_Diesel,ECM_HEV,PCM,PCM_HEV,GWM
 SG_ DrOpenPrvntLeft_B_Rq : 5|1@0+ (1,0) [0|1] "SED"  GWM
 SG_ ExitNotClrRight_B_Stat : 6|1@0+ (1,0) [0|1] "SED"  GWM
 SG_ ExitNotClrLeft_B_Stat : 7|1@0+ (1,0) [0|1] "SED"  GWM

BO_ 1238 IPMA_Data5: 8 IPMA_ADAS
 SG_ TjaCanclMsgTxt_D_Dsply : 31|4@0+ (1,0) [0|15] "SED"  GWM
 SG_ TsrAslButtnPress_D_Rq : 55|3@0+ (1,0) [0|7] "SED"  GWM
 SG_ Fba_D_Stat : 47|2@0+ (1,0) [0|3] "SED"  GWM
 SG_ FbaAlrt_D_Dsply : 33|2@0+ (1,0) [0|3] "SED"  GWM
 SG_ FbaMnu_D_Rq : 45|2@0+ (1,0) [0|3] "SED"  GWM
 SG_ TjaLaneBiasEnbl_D_Stat : 23|2@0+ (1,0) [0|3] "SED"  GWM
 SG_ TjaLcWarn_D_Rq : 36|3@0+ (1,0) [0|7] "SED"  GWM
 SG_ TjaLcMsgTxt_D_Rq : 39|3@0+ (1,0) [0|7] "SED"  GWM
 SG_ TjaLc_D_Stat : 27|4@0+ (1,0) [0|15] "SED"  GWM
 SG_ TjaLcEnbl_D_Stat : 17|2@0+ (1,0) [0|3] "SED"  GWM
 SG_ AhbcMnu_D_Rq : 21|2@0+ (1,0) [0|3] "SED"  GWM
 SG_ GfhbMnu_D_Rq : 19|2@0+ (1,0) [0|3] "SED"  GWM
 SG_ TjaLaneBias_D_Stat : 10|3@0+ (1,0) [0|7] "SED"  GWM
 SG_ IaccVAdjReas_D_Dsply : 15|5@0+ (1,0) [0|31] "SED"  GWM
 SG_ IaccVAdjLim_No_Actl : 7|8@0+ (1,0) [0|255] "unitless"  GWM
 SG_ FbaMsg_D_Rq : 43|2@0+ (1,0) [0|3] "SED"  GWM

BO_ 2610126880 OTAPhysVDMtoGWM_ECG: 64 VDM
 SG_ OTAPhysVDMtoGWM_ECG : 7|29@0+ (1,0) [0|536870911] "unitless"  GWM

BO_ 2609938648 OTAPhysGWM_ECGtoVDM: 64 GWM
 SG_ OTAPhysGWM_ECGtoVDM : 7|29@0+ (1,0) [0|536870911] "unitless"  VDM

BO_ 2610987224 PARSEDPhysGWM_ECGtoVDM: 64 GWM
 SG_ PARSEDPhysGWM_ECGtoVDM : 7|29@0+ (1,0) [0|536870911] "unitless"  VDM

BO_ 2611175456 PARSEDPhysVDMtoGWM_ECG: 64 VDM
 SG_ PARSEDPhysVDMtoGWM_ECG : 7|29@0+ (1,0) [0|536870911] "unitless"  GWM

BO_ 2612035800 PARSEDPushFcGWM_ECGtoVDM: 8 GWM
 SG_ PARSEDPushFcGWM_ECGtoVDM : 7|29@0+ (1,0) [0|536870911] "unitless"  VDM

BO_ 2612224032 PARSEDPushVDMtoGWM_ECG: 8 VDM
 SG_ PARSEDPushVDMtoGWM_ECG : 7|29@0+ (1,0) [0|536870911] "unitless"  GWM

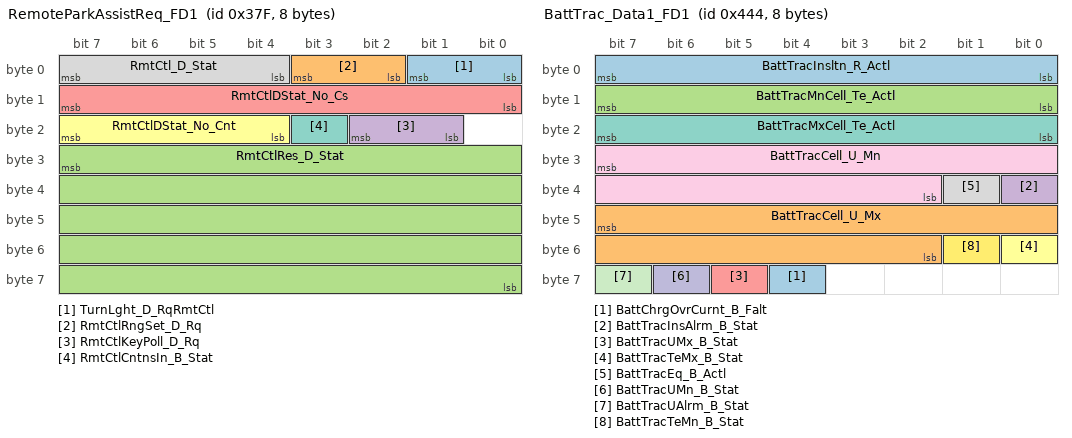
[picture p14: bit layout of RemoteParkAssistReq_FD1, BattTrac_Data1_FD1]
BO_ 895 RemoteParkAssistReq_FD1: 8 RFA_BLEM
 SG_ TurnLght_D_RqRmtCtl : 1|2@0+ (1,0) [0|3] "SED"  GENERIC
 SG_ RmtCtlRngSet_D_Rq : 3|2@0+ (1,0) [0|3] "SED"  GENERIC
 SG_ RmtCtlRes_D_Stat : 31|40@0+ (1,0) [0|1099511627775] "unitless"  GENERIC
 SG_ RmtCtlKeyPoll_D_Rq : 18|2@0+ (1,0) [0|3] "SED"  GENERIC
 SG_ RmtCtlDStat_No_Cs : 15|8@0+ (1,0) [0|255] "Unitless"  ECM_HEV,SOBDMC_HPCM,ABS_ESC,ECM,IPMA_ADAS,PCM,TCM
 SG_ RmtCtlDStat_No_Cnt : 23|4@0+ (1,0) [0|15] "Unitless"  ECM_HEV,SOBDMC_HPCM,ABS_ESC,ECM,IPMA_ADAS,PCM,TCM
 SG_ RmtCtlCntnsIn_B_Stat : 19|1@0+ (1,0) [0|1] "SED"  GENERIC
 SG_ RmtCtl_D_Stat : 7|4@0+ (1,0) [0|15] "SED"  ECM_HEV,SOBDMC_HPCM,ABS_ESC,ECM,IPMA_ADAS,PCM,TCM

BO_ 1092 BattTrac_Data1_FD1: 8 BECM
 SG_ BattChrgOvrCurnt_B_Falt : 60|1@0+ (1,0) [0|1] "SED"  GENERIC
 SG_ BattTracCell_U_Mx : 47|14@0+ (0.001,0) [0|16.382] "volt"  SOBDMC_HPCM
 SG_ BattTracMnCell_Te_Actl : 15|8@0+ (1,-40) [-40|213] "degC"  GENERIC
 SG_ BattTracInsAlrm_B_Stat : 32|1@0+ (1,0) [0|1] "SED"  GENERIC
 SG_ BattTracUMx_B_Stat : 61|1@0+ (1,0) [0|1] "SED"  GENERIC
 SG_ BattTracTeMx_B_Stat : 48|1@0+ (1,0) [0|1] "SED"  GENERIC
 SG_ BattTracMxCell_Te_Actl : 23|8@0+ (1,-40) [-40|213] "degC"  GENERIC
 SG_ BattTracEq_B_Actl : 33|1@0+ (1,0) [0|1] "SED"  GENERIC
 SG_ BattTracCell_U_Mn : 31|14@0+ (0.001,0) [0|16.382] "volt"  GENERIC
 SG_ BattTracUMn_B_Stat : 62|1@0+ (1,0) [0|1] "SED"  GENERIC
 SG_ BattTracUAlrm_B_Stat : 63|1@0+ (1,0) [0|1] "SED"  GENERIC
 SG_ BattTracTeMn_B_Stat : 49|1@0+ (1,0) [0|1] "SED"  GENERIC
 SG_ BattTracInsltn_R_Actl : 7|8@0+ (6000,0) [0|1524000] "ohm"  SOBDMC_HPCM

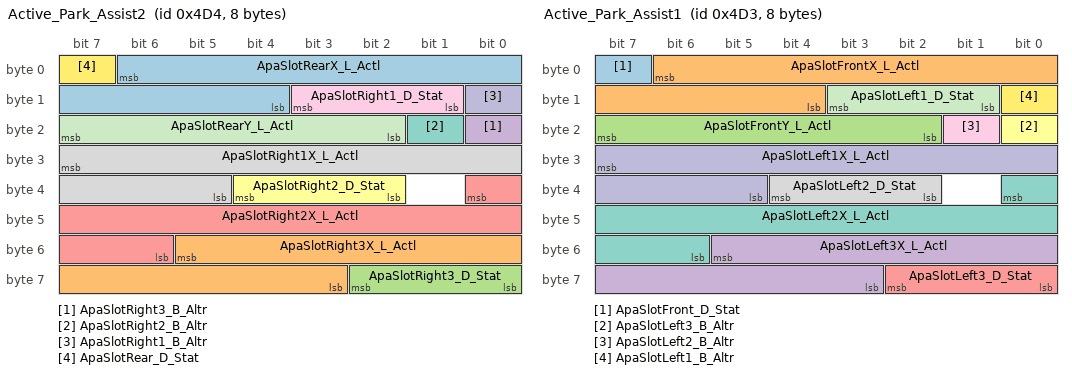
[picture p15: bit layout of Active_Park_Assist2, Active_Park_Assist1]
BO_ 1236 Active_Park_Assist2: 8 IPMA_ADAS
 SG_ ApaSlotRearX_L_Actl : 6|11@0+ (0.02,-20.96) [-20.96|19.98] "meter"  GWM
 SG_ ApaSlotRight3X_L_Actl : 53|11@0+ (0.02,-20.96) [-20.96|19.98] "meter"  GWM
 SG_ ApaSlotRight3_D_Stat : 58|3@0+ (1,0) [0|7] "SED"  GWM
 SG_ ApaSlotRight3_B_Altr : 16|1@0+ (1,0) [0|1] "SED"  GWM
 SG_ ApaSlotRight2X_L_Actl : 32|11@0+ (0.02,-20.96) [-20.96|19.98] "meter"  GWM
 SG_ ApaSlotRight2_D_Stat : 36|3@0+ (1,0) [0|7] "SED"  GWM
 SG_ ApaSlotRight2_B_Altr : 17|1@0+ (1,0) [0|1] "SED"  GWM
 SG_ ApaSlotRight1X_L_Actl : 31|11@0+ (0.02,-20.96) [-20.96|19.98] "meter"  GWM
 SG_ ApaSlotRight1_D_Stat : 11|3@0+ (1,0) [0|7] "SED"  GWM
 SG_ ApaSlotRight1_B_Altr : 8|1@0+ (1,0) [0|1] "SED"  GWM
 SG_ ApaSlotRearY_L_Actl : 23|6@0+ (0.2,-6.4) [-6.4|6.2] "meter"  GWM
 SG_ ApaSlotRear_D_Stat : 7|1@0+ (1,0) [0|1] "SED"  GWM

BO_ 1235 Active_Park_Assist1: 8 IPMA_ADAS
 SG_ ApaSlotFront_D_Stat : 7|1@0+ (1,0) [0|1] "SED"  GWM
 SG_ ApaSlotFrontX_L_Actl : 6|11@0+ (0.02,-20.96) [-20.96|19.98] "meter"  GWM
 SG_ ApaSlotFrontY_L_Actl : 23|6@0+ (0.2,-6.4) [-6.4|6.2] "meter"  GWM
 SG_ ApaSlotLeft3X_L_Actl : 53|11@0+ (0.02,-20.96) [-20.96|19.98] "meter"  GWM
 SG_ ApaSlotLeft3_D_Stat : 58|3@0+ (1,0) [0|7] "SED"  GWM
 SG_ ApaSlotLeft3_B_Altr : 16|1@0+ (1,0) [0|1] "SED"  GWM
 SG_ ApaSlotLeft2X_L_Actl : 32|11@0+ (0.02,-20.96) [-20.96|19.98] "meter"  GWM
 SG_ ApaSlotLeft2_D_Stat : 36|3@0+ (1,0) [0|7] "SED"  GWM
 SG_ ApaSlotLeft2_B_Altr : 17|1@0+ (1,0) [0|1] "SED"  GWM
 SG_ ApaSlotLeft1X_L_Actl : 31|11@0+ (0.02,-20.96) [-20.96|19.98] "meter"  GWM
 SG_ ApaSlotLeft1_D_Stat : 11|3@0+ (1,0) [0|7] "SED"  GWM
 SG_ ApaSlotLeft1_B_Altr : 8|1@0+ (1,0) [0|1] "SED"  GWM

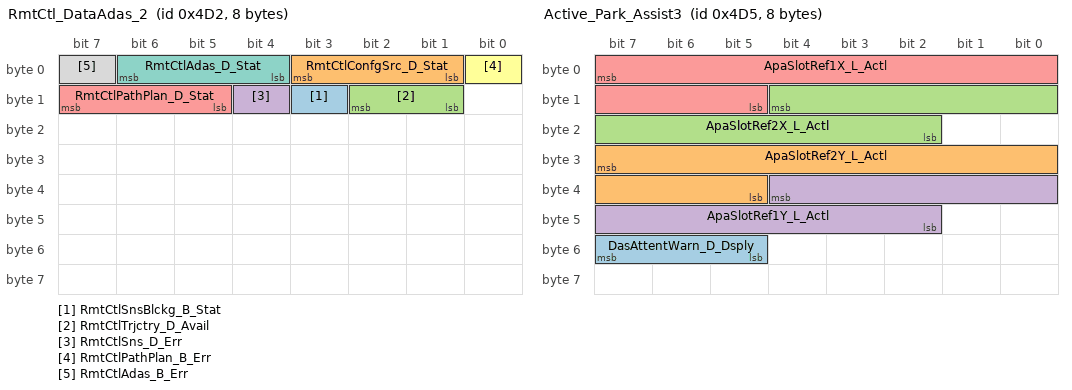
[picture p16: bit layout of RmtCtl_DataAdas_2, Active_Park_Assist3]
BO_ 1234 RmtCtl_DataAdas_2: 8 IPMA_ADAS
 SG_ RmtCtlSnsBlckg_B_Stat : 11|1@0+ (1,0) [0|1] "SED"  GWM
 SG_ RmtCtlConfgSrc_D_Stat : 3|3@0+ (1,0) [0|7] "SED"  GWM
 SG_ RmtCtlTrjctry_D_Avail : 10|2@0+ (1,0) [0|3] "SED"  GWM
 SG_ RmtCtlSns_D_Err : 12|1@0+ (1,0) [0|1] "SED"  GWM
 SG_ RmtCtlPathPlan_D_Stat : 15|3@0+ (1,0) [0|7] "SED"  GWM
 SG_ RmtCtlPathPlan_B_Err : 0|1@0+ (1,0) [0|1] "SED"  GWM
 SG_ RmtCtlAdas_D_Stat : 6|3@0+ (1,0) [0|7] "SED"  GWM
 SG_ RmtCtlAdas_B_Err : 7|1@0+ (1,0) [0|1] "SED"  GWM

BO_ 1233 RmtCtl_DataAdas_1: 8 IPMA_ADAS
 SG_ FreeDrvRear_D_Avail : 27|2@0+ (1,0) [0|3] "SED"  GWM
 SG_ FreeDrvFwd_D_Avail : 7|2@0+ (1,0) [0|3] "SED"  GWM
 SG_ RmtCtlTrgDist_D_Stat : 63|8@0+ (0.1,0) [0|25.5] "meter"  GWM
 SG_ RmtCtlSnsRrCrnr_D_Stat : 55|2@0+ (1,0) [0|3] "SED"  GWM
 SG_ RmtCtlSnsRlCrnr_D_Stat : 49|2@0+ (1,0) [0|3] "SED"  GWM
 SG_ RmtCtlSnsRear_D_Stat : 51|2@0+ (1,0) [0|3] "SED"  GWM
 SG_ RmtCtlSnsFront_D_Stat : 53|2@0+ (1,0) [0|3] "SED"  GWM
 SG_ RmtCtlSnsFrCrnr_D_Stat : 41|2@0+ (1,0) [0|3] "SED"  GWM
 SG_ RmtCtlSnsFlCrnr_D_Stat : 43|2@0+ (1,0) [0|3] "SED"  GWM
 SG_ RmtCtlSideSnsR4_D_Stat : 45|2@0+ (1,0) [0|3] "SED"  GWM
 SG_ RmtCtlSideSnsR3_D_Stat : 47|2@0+ (1,0) [0|3] "SED"  GWM
 SG_ RmtCtlSideSnsR2_D_Stat : 33|2@0+ (1,0) [0|3] "SED"  GWM
 SG_ RmtCtlSideSnsR1_D_Stat : 35|2@0+ (1,0) [0|3] "SED"  GWM
 SG_ RmtCtlSideSnsL4_D_Stat : 37|2@0+ (1,0) [0|3] "SED"  GWM
 SG_ RmtCtlSideSnsL3_D_Stat : 39|2@0+ (1,0) [0|3] "SED"  GWM
 SG_ RmtCtlSideSnsL2_D_Stat : 25|2@0+ (1,0) [0|3] "SED"  GWM
 SG_ RmtCtlSideSnsL1_D_Stat : 17|2@0+ (1,0) [0|3] "SED"  GWM
 SG_ RmtCtlRightOrnt_D_Avail : 20|3@0+ (1,0) [0|7] "SED"  GWM
 SG_ RmtCtlRight_D_Avail : 31|2@0+ (1,0) [0|3] "SED"  GWM
 SG_ RmtCtlRear_D_Avail : 29|2@0+ (1,0) [0|3] "SED"  GWM
 SG_ RmtCtlPrkMde_D_Stat : 9|2@0+ (1,0) [0|3] "SED"  GWM
 SG_ RmtCtlPrkInSlot_D_Stat : 23|3@0+ (1,0) [0|7] "SED"  GWM
 SG_ RmtCtlObstcl_B_Stat : 10|1@0+ (1,0) [0|1] "SED"  GWM
 SG_ RmtCtlNxtMoveDir_D_Stat : 12|2@0+ (1,0) [0|3] "SED"  GWM
 SG_ RmtCtlMoveDir_D_Stat : 1|2@0+ (1,0) [0|3] "SED"  GWM
 SG_ RmtCtlLeftOrnt_D_Avail : 15|3@0+ (1,0) [0|7] "SED"  GWM
 SG_ RmtCtlLeft_D_Avail : 3|2@0+ (1,0) [0|3] "SED"  GWM
 SG_ RmtCtlFront_D_Avail : 5|2@0+ (1,0) [0|3] "SED"  GWM

BO_ 1237 Active_Park_Assist3: 8 IPMA_ADAS
 SG_ DasAttentWarn_D_Dsply : 55|3@0+ (1,0) [0|7] "SED"  GWM
 SG_ ApaSlotRef2Y_L_Actl : 31|11@0+ (0.02,-20.96) [-20.96|19.98] "meter"  GWM
 SG_ ApaSlotRef2X_L_Actl : 12|11@0+ (0.02,-20.96) [-20.96|19.98] "meter"  GWM
 SG_ ApaSlotRef1Y_L_Actl : 36|11@0+ (0.02,-20.96) [-20.96|19.98] "meter"  GWM
 SG_ ApaSlotRef1X_L_Actl : 7|11@0+ (0.02,-20.96) [-20.96|19.98] "meter"  GWM

BO_ 1149 Battery_Traction_10_FD1: 8 BECM
 SG_ BattTracPerf_Pc_Dsply : 15|8@0+ (1,0) [0|253] "percent"  SOBDMC_HPCM
 SG_ BattTracPerf_Pc_Actl : 7|8@0+ (1,0) [0|253] "percent"  PCM,SOBDMC_HPCM,PCM_HEV

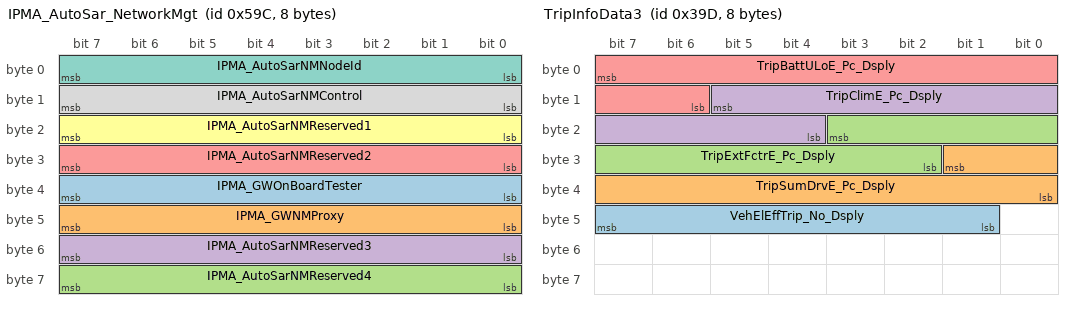
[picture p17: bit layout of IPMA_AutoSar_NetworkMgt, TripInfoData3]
BO_ 1436 IPMA_AutoSar_NetworkMgt: 8 IPMA_ADAS
 SG_ IPMA_GWOnBoardTester : 39|8@0+ (1,0) [0|255] "unitless"  HCM,GWM,GENERIC
 SG_ IPMA_GWNMProxy : 47|8@0+ (1,0) [0|255] "unitless"  HCM,GWM,GENERIC
 SG_ IPMA_AutoSarNMReserved4 : 63|8@0+ (1,0) [0|255] "unitless"  HCM,GWM,GENERIC
 SG_ IPMA_AutoSarNMReserved3 : 55|8@0+ (1,0) [0|255] "unitless"  HCM,GWM,GENERIC
 SG_ IPMA_AutoSarNMReserved2 : 31|8@0+ (1,0) [0|255] "unitless"  HCM,GWM,GENERIC
 SG_ IPMA_AutoSarNMReserved1 : 23|8@0+ (1,0) [0|255] "unitless"  HCM,GWM,GENERIC
 SG_ IPMA_AutoSarNMNodeId : 7|8@0+ (1,0) [0|255] "unitless"  HCM,GWM,GENERIC
 SG_ IPMA_AutoSarNMControl : 15|8@0+ (1,0) [0|255] "unitless"  HCM,GWM,GENERIC

BO_ 925 TripInfoData3: 8 SOBDMC_HPCM
 SG_ VehElEffTrip_No_Dsply : 47|7@0+ (10,-100) [-100|1150] "wattHr/km"  GWM
 SG_ TripSumDrvE_Pc_Dsply : 25|10@0+ (0.1,0) [0|102.1] "percent"  GWM
 SG_ TripExtFctrE_Pc_Dsply : 19|10@0+ (0.1,0) [0|102.1] "percent"  GWM
 SG_ TripClimE_Pc_Dsply : 13|10@0+ (0.1,0) [0|102.1] "percent"  GWM
 SG_ TripBattULoE_Pc_Dsply : 7|10@0+ (0.1,0) [0|102.1] "percent"  GWM

BO_ 2611001560 PARSEDPhysGWM_ECGtoCHCM: 64 GWM
 SG_ PARSEDPhysGWM_ECGtoCHCM : 7|29@0+ (1,0) [0|536870911] "Unitless"  CHCM

BO_ 2611175470 PARSEDPhysCHCMtoGWM_ECG: 64 CHCM
 SG_ PARSEDPhysCHCMtoGWM_ECG : 7|29@0+ (1,0) [0|536870911] "Unitless"  GWM

BO_ 2612224046 PARSEDPushCHCMtoGWM_ECG: 8 CHCM
 SG_ PARSEDPushCHCMtoGWM_ECG : 7|29@0+ (1,0) [0|536870911] "unitless"  GWM

BO_ 2609952984 OTAPhysGWM_ECGtoCHCM: 64 GWM
 SG_ OTAPhysGWM_ECGtoCHCM : 7|29@0+ (1,0) [0|536870911] "unitless"  CHCM

BO_ 2610126894 OTAPhysCHCMtoGWM_ECG: 64 CHCM
 SG_ OTAPhysCHCMtoGWM_ECG : 7|29@0+ (1,0) [0|536870911] "unitless"  GWM

BO_ 2612050136 PARSEDPushFcGWM_ECGtoCHCM: 8 GWM
 SG_ PARSEDPushGWM_ECGtoCHCM : 7|29@0+ (1,0) [0|536870911] "unitless"  CHCM

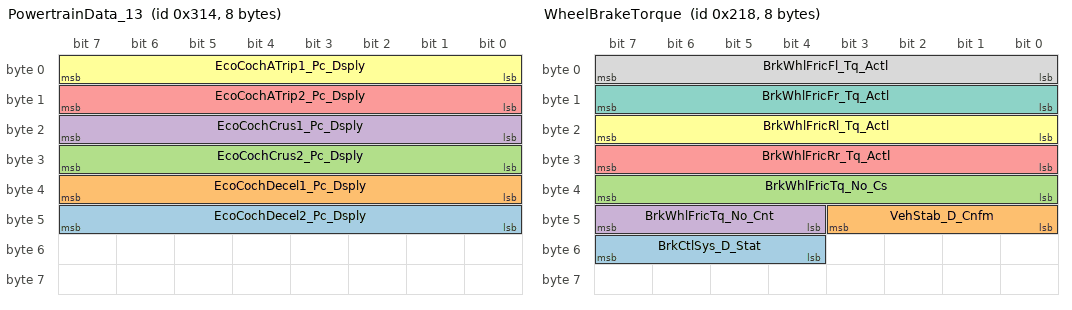
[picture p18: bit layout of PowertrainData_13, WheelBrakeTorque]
BO_ 788 PowertrainData_13: 8 PCM
 SG_ EcoCochDecel2_Pc_Dsply : 47|8@0+ (0.392157,0) [0|100.000035] "percent"  GWM
 SG_ EcoCochDecel1_Pc_Dsply : 39|8@0+ (0.392157,0) [0|100.000035] "percent"  GWM
 SG_ EcoCochCrus2_Pc_Dsply : 31|8@0+ (0.392157,0) [0|100.000035] "percent"  GWM
 SG_ EcoCochCrus1_Pc_Dsply : 23|8@0+ (0.392157,0) [0|100.000035] "percent"  GWM
 SG_ EcoCochATrip2_Pc_Dsply : 15|8@0+ (0.392157,0) [0|100.000035] "percent"  GWM
 SG_ EcoCochATrip1_Pc_Dsply : 7|8@0+ (0.392157,0) [0|100.000035] "percent"  GWM

BO_ 536 WheelBrakeTorque: 8 ABS_ESC
 SG_ BrkCtlSys_D_Stat : 55|4@0+ (1,0) [0|15] "SED"  ECM_HEV,SOBDMC_HPCM
 SG_ VehStab_D_Cnfm : 43|4@0+ (1,0) [0|15] "SED"  ECM_HEV,SOBDMC_HPCM
 SG_ BrkWhlFricTq_No_Cs : 39|8@0+ (1,0) [0|255] "Unitless"  ECM_HEV,SOBDMC_HPCM
 SG_ BrkWhlFricTq_No_Cnt : 47|4@0+ (1,0) [0|15] "Unitless"  ECM_HEV,SOBDMC_HPCM
 SG_ BrkWhlFricRr_Tq_Actl : 31|8@0+ (20,0) [0|5060] "Nm"  ECM_HEV,SOBDMC_HPCM
 SG_ BrkWhlFricRl_Tq_Actl : 23|8@0+ (20,0) [0|5060] "Nm"  ECM_HEV,SOBDMC_HPCM
 SG_ BrkWhlFricFr_Tq_Actl : 15|8@0+ (20,0) [0|5060] "Nm"  ECM_HEV,SOBDMC_HPCM
 SG_ BrkWhlFricFl_Tq_Actl : 7|8@0+ (20,0) [0|5060] "Nm"  ECM_HEV,SOBDMC_HPCM

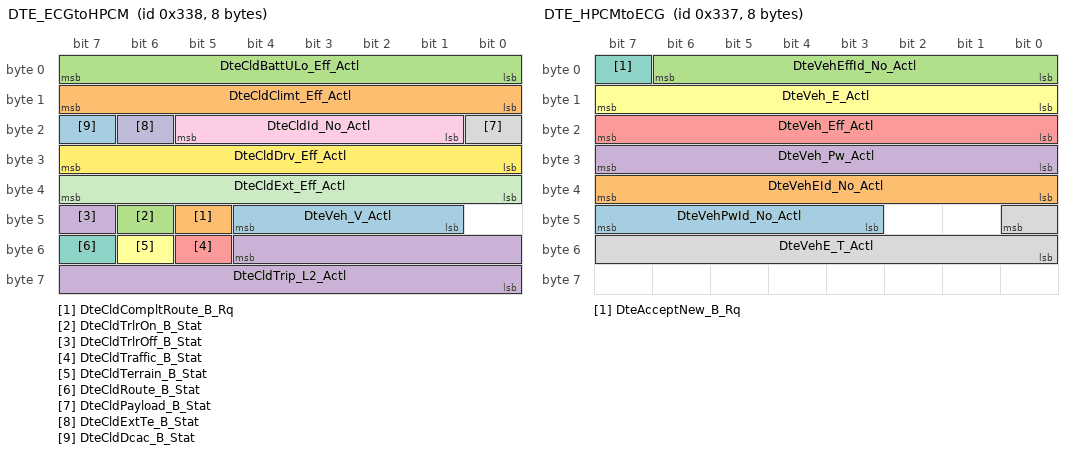
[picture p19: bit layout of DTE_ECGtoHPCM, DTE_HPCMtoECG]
BO_ 824 DTE_ECGtoHPCM: 8 GWM
 SG_ DteVeh_V_Actl : 44|4@0+ (5,5) [5|80] "miles/hour"  SOBDMC_HPCM
 SG_ DteCldCompltRoute_B_Rq : 45|1@0+ (1,0) [0|1] "SED"  SOBDMC_HPCM
 SG_ DteCldTrlrOn_B_Stat : 46|1@0+ (1,0) [0|1] "SED"  SOBDMC_HPCM
 SG_ DteCldTrlrOff_B_Stat : 47|1@0+ (1,0) [0|1] "SED"  SOBDMC_HPCM
 SG_ DteCldTraffic_B_Stat : 53|1@0+ (1,0) [0|1] "SED"  SOBDMC_HPCM
 SG_ DteCldTerrain_B_Stat : 54|1@0+ (1,0) [0|1] "SED"  SOBDMC_HPCM
 SG_ DteCldRoute_B_Stat : 55|1@0+ (1,0) [0|1] "SED"  SOBDMC_HPCM
 SG_ DteCldPayload_B_Stat : 16|1@0+ (1,0) [0|1] "SED"  SOBDMC_HPCM
 SG_ DteCldId_No_Actl : 21|5@0+ (1,0) [0|31] "unitless"  SOBDMC_HPCM
 SG_ DteCldExtTe_B_Stat : 22|1@0+ (1,0) [0|1] "SED"  SOBDMC_HPCM
 SG_ DteCldExt_Eff_Actl : 39|8@0+ (10,-1000) [-1000|1550] "watt*hour/km"  SOBDMC_HPCM
 SG_ DteCldDrv_Eff_Actl : 31|8@0+ (10,-1000) [-1000|1550] "watt*hour/km"  SOBDMC_HPCM
 SG_ DteCldDcac_B_Stat : 23|1@0+ (1,0) [0|1] "SED"  SOBDMC_HPCM
 SG_ DteCldClimt_Eff_Actl : 15|8@0+ (10,-1000) [-1000|1550] "watt*hour/km"  SOBDMC_HPCM
 SG_ DteCldBattULo_Eff_Actl : 7|8@0+ (10,-1000) [-1000|1550] "watt*hour/km"  SOBDMC_HPCM
 SG_ DteCldTrip_L2_Actl : 52|13@0+ (0.1,0) [0|818.9] "kilometer"  SOBDMC_HPCM

BO_ 823 DTE_HPCMtoECG: 8 SOBDMC_HPCM
 SG_ DteVehPwId_No_Actl : 47|5@0+ (1,0) [0|31] "unitless"  GWM
 SG_ DteVehEId_No_Actl : 39|8@0+ (1,0) [0|255] "unitless"  GWM
 SG_ DteVehEffId_No_Actl : 6|7@0+ (1,0) [0|127] "unitless"  GWM
 SG_ DteVeh_Pw_Actl : 31|8@0+ (50,0) [0|12750] "watts"  GWM
 SG_ DteVeh_Eff_Actl : 23|8@0+ (10,-1000) [-1000|1550] "watt*hour/km"  GWM
 SG_ DteVeh_E_Actl : 15|8@0+ (100,0) [0|25500] "watt*hour"  GWM
 SG_ DteAcceptNew_B_Rq : 7|1@0+ (1,0) [0|1] "SED"  GWM
 SG_ DteVehE_T_Actl : 40|9@0+ (10,0) [0|5110] "second"  GWM

BO_ 1920 TesterPhysicalReqSGM_FD1: 64 TSTR
 SG_ TesterPhysicalReqSGM : 7|64@0+ (1,0) [0|1.84467E+019] "unitless"  ECM_HEVDSL,PCM_HEV

BO_ 811 APIM_Data_FD1: 8 APIM
 SG_ SpeedoMajorUnit_D_Confg : 59|2@0+ (1,0) [0|3] "SED"  SOBDMC_HPCM
 SG_ ScMnSoc_Pc_RqMnu : 55|7@0+ (1,0) [0|125] "percent"  SOBDMC_HPCM
 SG_ ScEnbl_D_RqMnu : 57|2@0+ (1,0) [0|3] "SED"  SOBDMC_HPCM
 SG_ OnePdlDrvButtn_B_Falt : 16|1@0+ (1,0) [0|1] "SED"  ECM_HEV,PCM
 SG_ OnePdlDrvButtn_B_Stat : 48|1@0+ (1,0) [0|1] "SED"  ECM_HEV,PCM
 SG_ DistToStopover_L_Actl : 31|16@0+ (0.1,0) [0|6553.4] "kilometer"  SOBDMC_HPCM
 SG_ StopoverType_D_Stat : 47|3@0+ (1,0) [0|0] "SED"  SOBDMC_HPCM
 SG_ ExtLghtDsply_D_Stat : 7|3@0+ (1,0) [0|7] "SED"  GENERIC
 SG_ ExtLghtRight_D_RqMnu : 11|3@0+ (1,0) [0|7] "SED"  GENERIC
 SG_ AutoLghtOvrrd_B_RqDrv : 8|1@0+ (1,0) [0|1] "SED"  GENERIC
 SG_ ExtLghtRear_D_RqMnu : 14|3@0+ (1,0) [0|7] "SED"  GENERIC
 SG_ LongTermReset_B_RqMnu : 17|1@0+ (1,0) [0|1] "SED"  SOBDMC_HPCM
 SG_ ExtLghtLeft_D_RqMnu : 1|3@0+ (1,0) [0|7] "SED"  GENERIC
 SG_ ExtLghtFront_D_RqMnu : 4|3@0+ (1,0) [0|7] "SED"  GENERIC
 SG_ GoTEditMnte_T_RqMnu : 63|4@0+ (1,0) [0|15] "SED"  SOBDMC_HPCM
 SG_ GoTEditHr_T_RqMnu : 44|5@0+ (1,0) [0|29] "SED"  SOBDMC_HPCM
 SG_ BecRleas_No_RqMnu : 23|3@0+ (1,0) [0|7] "unitless"  GENERIC
 SG_ TrnkFrontRleas_No_RqMnu : 20|3@0+ (1,0) [0|7] "unitless"  GENERIC

BO_TX_BU_ 1057 : PCM,ECM_HEVDSL,ECM_HEV,ECM_Diesel,ECM,PCM_HEV;
BO_TX_BU_ 1055 : SOBDMC_HPCM,PCM,ECM_HEVDSL,ECM_HEV,ECM_Diesel,ECM,PCM_HEV;
BO_TX_BU_ 610 : SOBDMC_HPCM,PCM_HEV,PCM,ECM_HEVDSL,ECM_HEV,ECM_Diesel,ECM,AWD_DLCM;
BO_TX_BU_ 562 : PCM_HEV,PCM,ECM_HEVDSL,ECM_HEV,ECM_Diesel,ECM;
BO_TX_BU_ 523 : ECM_HEVDSL,ECM_HEV,ECM_Diesel,ECM,PCM;
BO_TX_BU_ 519 : PCM,ECM_HEVDSL,ECM_Diesel,ECM;
BO_TX_BU_ 517 : PCM,ECM_HEVDSL,ECM_HEV,ECM_Diesel,ECM,PCM_HEV;
BO_TX_BU_ 516 : PCM,ECM_HEVDSL,ECM_HEV,ECM_Diesel,ECM,PCM_HEV;
BO_TX_BU_ 514 : PCM,ECM_HEVDSL,ECM_HEV,ECM_Diesel,ECM,PCM_HEV;
BO_TX_BU_ 512 : PCM,ECM_HEVDSL,ECM_HEV,ECM_Diesel,ECM,PCM_HEV;
BO_TX_BU_ 382 : PCM_HEV,PCM,ECM_Diesel,ECM,ECM_HEV;
BO_TX_BU_ 381 : ECM,ECM_Diesel,PCM,PCM_HEV,ECM_HEVDSL;
BO_TX_BU_ 380 : PCM_HEV,ECM_HEVDSL,ECM_HEV,ECM_Diesel,ECM,PCM;
BO_TX_BU_ 377 : PCM,ECM_HEVDSL,ECM_HEV,ECM_Diesel,ECM,PCM_HEV;
BO_TX_BU_ 376 : PCM,ECM_HEVDSL,ECM_HEV,ECM_Diesel,ECM,PCM_HEV;
BO_TX_BU_ 373 : ECM_HEV,ECM_Diesel,ECM,ECM_HEVDSL;
BO_TX_BU_ 372 : ECM_Diesel,ECM_HEVDSL,ECM;
BO_TX_BU_ 359 : ECM,ECM_Diesel,ECM_HEVDSL,PCM,SOBDMC_HPCM,PCM_HEV;
BO_TX_BU_ 358 : PCM,ECM_HEVDSL,ECM_HEV,ECM_Diesel,ECM,PCM_HEV;
BO_TX_BU_ 357 : PCM,ECM_HEVDSL,ECM_HEV,ECM_Diesel,ECM,PCM_HEV;
BO_TX_BU_ 355 : ECM,ECM_Diesel,ECM_HEVDSL;
BO_TX_BU_ 342 : PCM,ECM_HEVDSL,ECM_HEV,ECM_Diesel,ECM,PCM_HEV;
BO_TX_BU_ 71 : ECM,ECM_Diesel,ECM_HEVDSL,PCM,PCM_HEV,SOBDMC_HPCM;
BO_TX_BU_ 788 : ECM_HEV,PCM;
CM_ SG_ 1057 FohEng_D_Rq "Signal not transmitted on vehicles that do not have the fuel operated heater feature.";
CM_ SG_ 1057 EngIdlShutDown_D_Stat "Signal not transmitted on diesel variants.";
CM_ SG_ 1057 FUEL_ALCOHOL_PERCNT "signal not transmitted on diesel and HEV variants.";
CM_ SG_ 1057 TrnTotTq_Rt_Est "Signal not transmitted on gas and HEV variants.";
CM_ SG_ 1057 TrnTotLss_Tq_Est "Signal not transmitted on gas and HEV variants.";
CM_ SG_ 1057 VehVLimStat_D_Actl "Signal not transmitted on gas and HEV variants.";
CM_ SG_ 1057 VehVLimActv_B_Actl "Signal not transmitted on gas and HEV variants.";
CM_ SG_ 562 OnePdlDrvDStat_No_Cnt "Signal not transmitted on gas variants.";
CM_ SG_ 562 OnePdlDrvDStat_No_Cs "Signal not transmitted on gas variants.";
CM_ SG_ 562 GearNtrl_No_Cs "Powersplit HEVs with HF45, HPCM will Tx  this message.  For all other programs it will be Tx by PCM or TCM. ";
CM_ SG_ 562 GearNtrl_No_Cnt "Powersplit HEVs with HF45, HPCM will Tx  this message.  For all other programs it will be Tx by PCM or TCM. ";
CM_ SG_ 516 EngAout3_N_Actl "Signal not transmitted on gas and diesel variants.";
CM_ SG_ 516 ApedPosPcActl_No_Cnt "Signal not transmitted on gas and diesel variants.";
CM_ SG_ 516 ApedPosPcActl_No_Cs "Signal not transmitted on gas and diesel variants.";
CM_ SG_ 514 EngAout_Tq_VacLimSpcN "Signal not transmitted on gas and diesel variances.";
CM_ SG_ 514 EngCylSync_No_Ctr "Signal not transmitted on gas and diesel variances.";
CM_ SG_ 514 GearRvrse_D_Actl "Do not implement GearRvrse_D_Actl  until eTracker 8804151 is approved, 11/24/09";
CM_ SG_ 512 PrplWhlTotTqRq_No_Cs "Signal not transmitted on gas variants.";
CM_ SG_ 512 PrplWhlTotTqRq_No_Cnt "Signal not transmitted on gas variants.";
CM_ SG_ 512 EngAout_Tq_MxMxN "Signal not transmitted on gas variants.";
CM_ BO_ 382 "ECM, PCM Gas Only msg";
CM_ SG_ 377 EngFuelCutFull_B_Inhbt "Signal not transmitted on diesel variants.";
CM_ SG_ 377 FuelFlw_Vl_Dsply "Signal not transmitted on diesel variants.";
CM_ SG_ 377 FuelFillInlet_B_Dsply "Signal not transmitted on diesel variants.";
CM_ SG_ 377 OdoCount "Signal not transmitted on diesel variants.";
CM_ SG_ 377 EngOilLife_Pc_Actl "Signal not transmitted on diesel variants.";
CM_ SG_ 377 TrnKickDown_B_RqDrv "Signal not transmitted on diesel variants.";
CM_ SG_ 377 AirCondRec_B_Rq "Signal not transmitted on diesel variants.";
CM_ SG_ 377 AirCondClutch_B_Stats "Signal not transmitted on diesel variants.";
CM_ SG_ 376 EngAout_Aa_Actl "Signal not transmitted on HEV variants.";
CM_ SG_ 373 EngFuelCutFull_B_Allw "Signal not transmitted on diesel variances.";
CM_ SG_ 373 EngAout_Tq_MxActlN "Signal not transmitted on diesel variances.";
CM_ SG_ 359 TrnAin_Tq_Actl "Signal not transmitted on HEV variances.";
CM_ SG_ 359 PlgActvArb_B_Actl "Only supported on PHEV programs.  PlgActvArb_B_Actl HPCM will Tx on Powersplit PHEV’s,  On MHT PHEVs the PCM_HEV will Tx and HPCM will Rx. 
";
CM_ SG_ 359 TrnAinTq_D_Qf "Signal not transmitted on HEV variances.";
CM_ SG_ 358 HiElPwInhbt_B_Stat "Signal not transmitted on HEV programs";
CM_ SG_ 358 AutoStopPtDelta_I_Est "Signal not transmitted on vehicles that do not have autostop/stop-start feature.";
CM_ SG_ 342 EngOvrhtMitgActv_D_Ind "Signal not transmitted on diesel.";
CM_ SG_ 342 EngGoutLss_Tq_Est "Signal not transmitted on gas and diesel variants.";
CM_ SG_ 1166 DrLatchCntRr_No_Actl "Rolling counts indicate fresh data (DrLatchCntxx) are updated each time new data is sent from a latch to BCM thru the GW. UBs not required.";
CM_ SG_ 1165 DrLatchCntRl_No_Actl "Rolling counts indicate fresh data (DrLatchCntxx) are updated each time new data is sent from a latch to BCM thru the GW. UBs not required.";
CM_ SG_ 1164 DrLatchCntFr_No_Actl "Rolling counts indicate fresh data (DrLatchCntxx) are updated each time new data is sent from a latch to BCM thru the GW. UBs not required.";
CM_ SG_ 1163 DrLatchCntFl_No_Actl "Rolling counts indicate fresh data (DrLatchCntxx) are updated each time new data is sent from a latch to BCM thru the GW. UBs not required.";
CM_ BO_ 71 "Provide target function info. to control function of PATS";
BA_DEF_ BO_  "VFrameFormat" ENUM  "StandardCAN","ExtendedCAN","reserved","reserved","reserved","reserved","reserved","reserved","reserved","reserved","reserved","reserved","reserved","reserved","StandardCAN_FD","ExtendedCAN_FD";
BA_DEF_ SG_  "GenSigSendType" ENUM  "Cyclic","OnWrite","vector_leerstring","OnChange","vector_leerstring","IfActive","vector_leerstring","NoSigSendType";
BA_DEF_ SG_  "GenSigInactiveValue" INT 0 100000;
BA_DEF_ SG_  "WakeupSignal" ENUM  "No","Yes";
BA_DEF_ SG_  "UsedOnPgmDBC" ENUM  "No","Yes";
BA_DEF_ SG_  "GenSigStartValueInteger" INT 0 1000000000;
BA_DEF_ SG_  "ContentDependant" ENUM  "No","Yes";
BA_DEF_ SG_  "MetaData" ENUM  "No","Yes";
BA_DEF_ SG_  "GenSigStartValue" HEX 0 268435455;
BA_DEF_ SG_  "U_CX727_MY2021_Rx" ENUM  "No","Yes";
BA_DEF_ SG_  "U_P702_MY2021_Rx" ENUM  "No","Yes";
BA_DEF_ SG_  "U_T6_MCA_MY2020_Rx" ENUM  "No","Yes";
BA_DEF_ SG_  "ECGUsedRxSignal" ENUM  "No","Yes";
BA_DEF_ SG_  "U_CD542_MY2021_Rx" ENUM  "No","Yes";
BA_DEF_ SG_  "U_U55X_MY2022_Rx" ENUM  "No","Yes";
BA_DEF_ SG_  "U_CD764_MY2022_Rx" ENUM  "No","Yes";
BA_DEF_ SG_  "U_CDX706_MY2023_Rx" ENUM  "No","Yes";
BA_DEF_ SG_  "U_CX727_MY2021_Tx" ENUM  "No","Yes";
BA_DEF_ SG_  "U_P702_MY2021_Tx" ENUM  "No","Yes";
BA_DEF_ SG_  "U_T6_MCA_MY2020_Tx" ENUM  "No","Yes";
BA_DEF_ SG_  "ECGUsedTxSignal" ENUM  "No","Yes";
BA_DEF_ SG_  "U_CD542_MY2021_Tx" ENUM  "No","Yes";
BA_DEF_ SG_  "U_U55X_MY2022_Tx" ENUM  "No","Yes";
BA_DEF_ SG_  "U_CD764_MY2022_Tx" ENUM  "No","Yes";
BA_DEF_ SG_  "U_CDX706_MY2023_Tx" ENUM  "No","Yes";
BA_DEF_ BO_  "GenMsgILSupport" ENUM  "No","Yes";
BA_DEF_ BO_  "DiagResponse" ENUM  "No","Yes";
BA_DEF_ BO_  "DiagRequest" ENUM  "No","Yes";
BA_DEF_ BO_  "TpTxIndex" INT 0 536870911;
BA_DEF_ BO_  "DiagState" ENUM  "No","Yes";
BA_DEF_ BO_  "TpApplType" STRING ;
BA_DEF_ BO_  "NmAsrMessage" ENUM  "No","Yes";
BA_DEF_ BO_  "ProgBWConditional" STRING ;
BA_DEF_ BO_  "SCP_AuthInfoTxLength" INT 0 512;
BA_DEF_ BO_  "SCP_FreshnessValueTxLength" INT 0 512;
BA_DEF_ BO_  "SCP_FreshnessValueLength" INT 0 512;
BA_DEF_ BO_  "OvtpPushApplication" ENUM  "FALSE","TRUE";
BA_DEF_ BO_  "GenMsgSendType" ENUM  "FixedPeriodic","Event","EnabledPeriodic","NotUsed","NotUsed","EventPeriodic","NotUsed","NotUsed","NoMsgSendType";
BA_DEF_ BO_  "GenMsgCycleTime" INT 0 100000;
BA_DEF_ BO_  "GenMsgDelayTime" INT 0 1000;
BA_DEF_ BO_  "GenMsgNrOfRepetition" INT 0 100;
BA_DEF_ BO_  "GenMsgStartDelayTime" INT 0 10000;
BA_DEF_ BO_  "EventRateOfChange" INT 10 10000;
BA_DEF_ BO_  "FrameGatewayId" HEX 0 1407;
BA_DEF_ BO_  "NetworkInitialization" ENUM  "No","Yes";
BA_DEF_ BO_  "FrameGatewayNetwork" STRING ;
BA_DEF_ BO_  "FrameRouting" STRING ;
BA_DEF_DEF_  "VFrameFormat" "ExtendedCAN_FD";
BA_DEF_DEF_  "GenSigSendType" "NoSigSendType";
BA_DEF_DEF_  "GenSigInactiveValue" 0;
BA_DEF_DEF_  "WakeupSignal" "No";
BA_DEF_DEF_  "UsedOnPgmDBC" "Yes";
BA_DEF_DEF_  "GenSigStartValueInteger" 0;
BA_DEF_DEF_  "ContentDependant" "No";
BA_DEF_DEF_  "MetaData" "No";
BA_DEF_DEF_  "GenSigStartValue" 0;
BA_DEF_DEF_  "U_CX727_MY2021_Rx" "No";
BA_DEF_DEF_  "U_P702_MY2021_Rx" "No";
BA_DEF_DEF_  "U_T6_MCA_MY2020_Rx" "No";
BA_DEF_DEF_  "ECGUsedRxSignal" "No";
BA_DEF_DEF_  "U_CD542_MY2021_Rx" "No";
BA_DEF_DEF_  "U_U55X_MY2022_Rx" "No";
BA_DEF_DEF_  "U_CD764_MY2022_Rx" "No";
BA_DEF_DEF_  "U_CDX706_MY2023_Rx" "No";
BA_DEF_DEF_  "U_CX727_MY2021_Tx" "No";
BA_DEF_DEF_  "U_P702_MY2021_Tx" "No";
BA_DEF_DEF_  "U_T6_MCA_MY2020_Tx" "No";
BA_DEF_DEF_  "ECGUsedTxSignal" "No";
BA_DEF_DEF_  "U_CD542_MY2021_Tx" "No";
BA_DEF_DEF_  "U_U55X_MY2022_Tx" "No";
BA_DEF_DEF_  "U_CD764_MY2022_Tx" "No";
BA_DEF_DEF_  "U_CDX706_MY2023_Tx" "No";
BA_DEF_DEF_  "GenMsgILSupport" "Yes";
BA_DEF_DEF_  "DiagResponse" "No";
BA_DEF_DEF_  "DiagRequest" "No";
BA_DEF_DEF_  "TpTxIndex" 0;
BA_DEF_DEF_  "DiagState" "No";
BA_DEF_DEF_  "TpApplType" "";
BA_DEF_DEF_  "NmAsrMessage" "No";
BA_DEF_DEF_  "ProgBWConditional" "NONE";
BA_DEF_DEF_  "SCP_AuthInfoTxLength" 53;
BA_DEF_DEF_  "SCP_FreshnessValueTxLength" 11;
BA_DEF_DEF_  "SCP_FreshnessValueLength" 64;
BA_DEF_DEF_  "OvtpPushApplication" "FALSE";
BA_DEF_DEF_  "GenMsgSendType" "NoMsgSendType";
BA_DEF_DEF_  "GenMsgCycleTime" 0;
BA_DEF_DEF_  "GenMsgDelayTime" 20;
BA_DEF_DEF_  "GenMsgNrOfRepetition" 1;
BA_DEF_DEF_  "GenMsgStartDelayTime" 0;
BA_DEF_DEF_  "EventRateOfChange" 10000;
BA_DEF_DEF_  "FrameGatewayId" 0;
BA_DEF_DEF_  "NetworkInitialization" "Yes";
BA_DEF_DEF_  "FrameGatewayNetwork" "NONE";
BA_DEF_DEF_  "FrameRouting" "";
BA_ "GenMsgSendType" BO_ 894 5;
BA_ "GenMsgCycleTime" BO_ 894 200;
BA_ "GenMsgSendType" BO_ 1166 5;
BA_ "GenMsgCycleTime" BO_ 1166 1000;
BA_ "GenMsgSendType" BO_ 1165 5;
BA_ "GenMsgCycleTime" BO_ 1165 1000;
BA_ "GenMsgSendType" BO_ 1164 5;
BA_ "GenMsgCycleTime" BO_ 1164 1000;
BA_ "GenMsgSendType" BO_ 1163 5;
BA_ "GenMsgCycleTime" BO_ 1163 1000;
BA_ "GenMsgSendType" BO_ 895 0;
BA_ "GenMsgCycleTime" BO_ 895 60;
BA_ "GenMsgSendType" BO_ 1092 0;
BA_ "GenMsgCycleTime" BO_ 1092 1000;
BA_ "GenMsgSendType" BO_ 1149 0;
BA_ "GenMsgCycleTime" BO_ 1149 1000;
BA_ "GenMsgSendType" BO_ 811 5;
BA_ "GenMsgCycleTime" BO_ 811 1000;
BA_ "GenMsgSendType" BO_ 1057 0;
BA_ "GenMsgCycleTime" BO_ 1057 100;
BA_ "VFrameFormat" BO_ 1057 14;
BA_ "GenMsgSendType" BO_ 1055 0;
BA_ "GenMsgCycleTime" BO_ 1055 100;
BA_ "VFrameFormat" BO_ 1055 14;
BA_ "GenMsgSendType" BO_ 610 0;
BA_ "GenMsgCycleTime" BO_ 610 100;
BA_ "VFrameFormat" BO_ 610 14;
BA_ "GenMsgSendType" BO_ 562 0;
BA_ "GenMsgCycleTime" BO_ 562 100;
BA_ "VFrameFormat" BO_ 562 14;
BA_ "GenMsgSendType" BO_ 523 0;
BA_ "GenMsgCycleTime" BO_ 523 1000;
BA_ "VFrameFormat" BO_ 523 14;
BA_ "GenMsgSendType" BO_ 519 0;
BA_ "GenMsgCycleTime" BO_ 519 20;
BA_ "GenMsgDelayTime" BO_ 519 10;
BA_ "VFrameFormat" BO_ 519 14;
BA_ "GenMsgSendType" BO_ 517 0;
BA_ "GenMsgCycleTime" BO_ 517 10;
BA_ "GenMsgDelayTime" BO_ 517 0;
BA_ "VFrameFormat" BO_ 517 14;
BA_ "GenMsgSendType" BO_ 516 0;
BA_ "GenMsgCycleTime" BO_ 516 10;
BA_ "GenMsgDelayTime" BO_ 516 0;
BA_ "VFrameFormat" BO_ 516 14;
BA_ "GenMsgSendType" BO_ 514 0;
BA_ "GenMsgCycleTime" BO_ 514 20;
BA_ "GenMsgDelayTime" BO_ 514 10;
BA_ "VFrameFormat" BO_ 514 14;
BA_ "GenMsgSendType" BO_ 512 0;
BA_ "GenMsgCycleTime" BO_ 512 20;
BA_ "GenMsgDelayTime" BO_ 512 10;
BA_ "VFrameFormat" BO_ 512 14;
BA_ "GenMsgSendType" BO_ 382 0;
BA_ "GenMsgCycleTime" BO_ 382 1000;
BA_ "VFrameFormat" BO_ 382 14;
BA_ "GenMsgSendType" BO_ 381 0;
BA_ "GenMsgCycleTime" BO_ 381 100;
BA_ "VFrameFormat" BO_ 381 14;
BA_ "GenMsgSendType" BO_ 380 0;
BA_ "GenMsgCycleTime" BO_ 380 100;
BA_ "VFrameFormat" BO_ 380 14;
BA_ "GenMsgSendType" BO_ 377 0;
BA_ "GenMsgCycleTime" BO_ 377 100;
BA_ "VFrameFormat" BO_ 377 14;
BA_ "GenMsgSendType" BO_ 376 0;
BA_ "GenMsgCycleTime" BO_ 376 100;
BA_ "VFrameFormat" BO_ 376 14;
BA_ "GenMsgSendType" BO_ 373 0;
BA_ "GenMsgCycleTime" BO_ 373 20;
BA_ "GenMsgDelayTime" BO_ 373 10;
BA_ "VFrameFormat" BO_ 373 14;
BA_ "GenMsgSendType" BO_ 372 0;
BA_ "GenMsgCycleTime" BO_ 372 20;
BA_ "GenMsgDelayTime" BO_ 372 10;
BA_ "VFrameFormat" BO_ 372 14;
BA_ "GenMsgSendType" BO_ 359 0;
BA_ "GenMsgCycleTime" BO_ 359 10;
BA_ "GenMsgDelayTime" BO_ 359 0;
BA_ "VFrameFormat" BO_ 359 14;
BA_ "GenMsgSendType" BO_ 358 0;
BA_ "GenMsgCycleTime" BO_ 358 100;
BA_ "VFrameFormat" BO_ 358 14;
BA_ "GenMsgSendType" BO_ 357 0;
BA_ "GenMsgCycleTime" BO_ 357 20;
BA_ "GenMsgDelayTime" BO_ 357 10;
BA_ "VFrameFormat" BO_ 357 14;
BA_ "GenMsgSendType" BO_ 355 0;
BA_ "GenMsgCycleTime" BO_ 355 100;
BA_ "VFrameFormat" BO_ 355 14;
BA_ "GenMsgSendType" BO_ 342 0;
BA_ "GenMsgCycleTime" BO_ 342 100;
BA_ "VFrameFormat" BO_ 342 14;
BA_ "FrameGatewayId" BO_ 894 894;
BA_ "FrameGatewayNetwork" BO_ 894 "HS1_CAN";
BA_ "FrameRouting" BO_ 894 "HS1_CAN,0x37E;";
BA_ "VFrameFormat" BO_ 894 14;
BA_ "GenMsgILSupport" BO_ 1520 0;
BA_ "NmAsrMessage" BO_ 1520 1;
BA_ "GenMsgSendType" BO_ 1520 0;
BA_ "GenMsgCycleTime" BO_ 1520 1000;
BA_ "NetworkInitialization" BO_ 1520 0;
BA_ "VFrameFormat" BO_ 1520 14;
BA_ "FrameGatewayId" BO_ 1166 1166;
BA_ "FrameGatewayNetwork" BO_ 1166 "MS1_CAN";
BA_ "FrameRouting" BO_ 1166 "MS1_CAN,0x48E;";
BA_ "VFrameFormat" BO_ 1166 14;
BA_ "FrameGatewayId" BO_ 1165 1165;
BA_ "FrameGatewayNetwork" BO_ 1165 "MS1_CAN";
BA_ "FrameRouting" BO_ 1165 "MS1_CAN,0x48D;";
BA_ "VFrameFormat" BO_ 1165 14;
BA_ "FrameGatewayId" BO_ 1164 1164;
BA_ "FrameGatewayNetwork" BO_ 1164 "MS1_CAN";
BA_ "FrameRouting" BO_ 1164 "MS1_CAN,0x48C;";
BA_ "VFrameFormat" BO_ 1164 14;
BA_ "FrameGatewayId" BO_ 1163 1163;
BA_ "FrameGatewayNetwork" BO_ 1163 "MS1_CAN";
BA_ "FrameRouting" BO_ 1163 "MS1_CAN,0x48B;";
BA_ "VFrameFormat" BO_ 1163 14;
BA_ "GenMsgSendType" BO_ 71 0;
BA_ "GenMsgCycleTime" BO_ 71 20;
BA_ "GenMsgDelayTime" BO_ 71 10;
BA_ "VFrameFormat" BO_ 71 14;
BA_ "GenMsgSendType" BO_ 1229 5;
BA_ "GenMsgCycleTime" BO_ 1229 1000;
BA_ "VFrameFormat" BO_ 1229 14;
BA_ "GenMsgSendType" BO_ 1238 5;
BA_ "GenMsgCycleTime" BO_ 1238 1000;
BA_ "VFrameFormat" BO_ 1238 14;
BA_ "TpTxIndex" BO_ 2610126880 462455000;
BA_ "GenMsgSendType" BO_ 2610126880 1;
BA_ "GenMsgDelayTime" BO_ 2610126880 0;
BA_ "NetworkInitialization" BO_ 2610126880 0;
BA_ "TpTxIndex" BO_ 2609938648 462455000;
BA_ "GenMsgSendType" BO_ 2609938648 1;
BA_ "GenMsgDelayTime" BO_ 2609938648 0;
BA_ "NetworkInitialization" BO_ 2609938648 0;
BA_ "TpTxIndex" BO_ 2610987224 463503576;
BA_ "GenMsgSendType" BO_ 2610987224 1;
BA_ "GenMsgDelayTime" BO_ 2610987224 0;
BA_ "NetworkInitialization" BO_ 2610987224 0;
BA_ "TpTxIndex" BO_ 2611175456 463503576;
BA_ "GenMsgSendType" BO_ 2611175456 1;
BA_ "GenMsgDelayTime" BO_ 2611175456 0;
BA_ "NetworkInitialization" BO_ 2611175456 0;
BA_ "TpTxIndex" BO_ 2612035800 464552152;
BA_ "OvtpPushApplication" BO_ 2612035800 1;
BA_ "GenMsgSendType" BO_ 2612035800 1;
BA_ "GenMsgDelayTime" BO_ 2612035800 0;
BA_ "NetworkInitialization" BO_ 2612035800 0;
BA_ "TpTxIndex" BO_ 2612224032 464552152;
BA_ "OvtpPushApplication" BO_ 2612224032 1;
BA_ "GenMsgSendType" BO_ 2612224032 1;
BA_ "GenMsgDelayTime" BO_ 2612224032 0;
BA_ "NetworkInitialization" BO_ 2612224032 0;
BA_ "FrameGatewayId" BO_ 895 895;
BA_ "FrameGatewayNetwork" BO_ 895 "HS4_CAN";
BA_ "FrameRouting" BO_ 895 "HS4_CAN,0x37F;";
BA_ "VFrameFormat" BO_ 895 14;
BA_ "FrameGatewayId" BO_ 1092 1092;
BA_ "FrameGatewayNetwork" BO_ 1092 "HS1_CAN";
BA_ "FrameRouting" BO_ 1092 "HS1_CAN,0x444;";
BA_ "VFrameFormat" BO_ 1092 14;
BA_ "GenMsgSendType" BO_ 1236 5;
BA_ "GenMsgCycleTime" BO_ 1236 1000;
BA_ "VFrameFormat" BO_ 1236 14;
BA_ "GenMsgSendType" BO_ 1235 5;
BA_ "GenMsgCycleTime" BO_ 1235 1000;
BA_ "VFrameFormat" BO_ 1235 14;
BA_ "GenMsgSendType" BO_ 1234 5;
BA_ "GenMsgCycleTime" BO_ 1234 200;
BA_ "VFrameFormat" BO_ 1234 14;
BA_ "GenMsgSendType" BO_ 1233 5;
BA_ "GenMsgCycleTime" BO_ 1233 200;
BA_ "VFrameFormat" BO_ 1233 14;
BA_ "GenMsgSendType" BO_ 1237 5;
BA_ "GenMsgCycleTime" BO_ 1237 200;
BA_ "VFrameFormat" BO_ 1237 14;
BA_ "FrameGatewayId" BO_ 1149 1149;
BA_ "FrameGatewayNetwork" BO_ 1149 "HS1_CAN";
BA_ "FrameRouting" BO_ 1149 "HS1_CAN,0x47D;";
BA_ "VFrameFormat" BO_ 1149 14;
BA_ "GenMsgILSupport" BO_ 1436 0;
BA_ "NmAsrMessage" BO_ 1436 1;
BA_ "GenMsgSendType" BO_ 1436 0;
BA_ "GenMsgCycleTime" BO_ 1436 1000;
BA_ "NetworkInitialization" BO_ 1436 0;
BA_ "VFrameFormat" BO_ 1436 14;
BA_ "GenMsgSendType" BO_ 925 0;
BA_ "GenMsgCycleTime" BO_ 925 1000;
BA_ "VFrameFormat" BO_ 925 14;
BA_ "TpTxIndex" BO_ 2611001560 463518680;
BA_ "GenMsgSendType" BO_ 2611001560 1;
BA_ "GenMsgDelayTime" BO_ 2611001560 0;
BA_ "NetworkInitialization" BO_ 2611001560 0;
BA_ "TpTxIndex" BO_ 2611175470 463518680;
BA_ "GenMsgSendType" BO_ 2611175470 1;
BA_ "GenMsgDelayTime" BO_ 2611175470 0;
BA_ "NetworkInitialization" BO_ 2611175470 0;
BA_ "TpTxIndex" BO_ 2612224046 464566488;
BA_ "OvtpPushApplication" BO_ 2612224046 1;
BA_ "GenMsgSendType" BO_ 2612224046 1;
BA_ "GenMsgDelayTime" BO_ 2612224046 0;
BA_ "NetworkInitialization" BO_ 2612224046 0;
BA_ "TpTxIndex" BO_ 2609952984 462470104;
BA_ "GenMsgSendType" BO_ 2609952984 1;
BA_ "GenMsgDelayTime" BO_ 2609952984 0;
BA_ "NetworkInitialization" BO_ 2609952984 0;
BA_ "TpTxIndex" BO_ 2610126894 462470104;
BA_ "GenMsgSendType" BO_ 2610126894 1;
BA_ "GenMsgDelayTime" BO_ 2610126894 0;
BA_ "NetworkInitialization" BO_ 2610126894 0;
BA_ "TpTxIndex" BO_ 2612050136 464566488;
BA_ "OvtpPushApplication" BO_ 2612050136 1;
BA_ "GenMsgSendType" BO_ 2612050136 1;
BA_ "GenMsgDelayTime" BO_ 2612050136 0;
BA_ "NetworkInitialization" BO_ 2612050136 0;
BA_ "GenMsgSendType" BO_ 788 0;
BA_ "GenMsgCycleTime" BO_ 788 500;
BA_ "VFrameFormat" BO_ 788 14;
BA_ "GenMsgSendType" BO_ 536 0;
BA_ "GenMsgCycleTime" BO_ 536 50;
BA_ "VFrameFormat" BO_ 536 14;
BA_ "GenMsgSendType" BO_ 824 5;
BA_ "GenMsgCycleTime" BO_ 824 1000;
BA_ "VFrameFormat" BO_ 824 14;
BA_ "GenMsgSendType" BO_ 823 5;
BA_ "GenMsgCycleTime" BO_ 823 1000;
BA_ "VFrameFormat" BO_ 823 14;
BA_ "GenMsgILSupport" BO_ 1920 0;
BA_ "DiagRequest" BO_ 1920 1;
BA_ "GenMsgSendType" BO_ 1920 1;
BA_ "GenMsgDelayTime" BO_ 1920 0;
BA_ "NetworkInitialization" BO_ 1920 0;
BA_ "VFrameFormat" BO_ 1920 14;
BA_ "FrameGatewayId" BO_ 811 811;
BA_ "FrameGatewayNetwork" BO_ 811 "HS3_CAN";
BA_ "FrameRouting" BO_ 811 "HS3_CAN,0x32B;";
BA_ "VFrameFormat" BO_ 811 14;
BA_ "GenSigStartValueInteger" SG_ 1057 FohEng_D_Rq 2;
BA_ "ContentDependant" SG_ 1057 FohEng_D_Rq 1;
BA_ "GenSigStartValue" SG_ 1057 FohEng_D_Rq 2;
BA_ "U_P702_MY2021_Tx" SG_ 1057 FohEng_D_Rq 1;
BA_ "U_T6_MCA_MY2020_Tx" SG_ 1057 FohEng_D_Rq 1;
BA_ "U_CX727_MY2021_Tx" SG_ 1057 EngIdlShutDwnTxt_D_Rq 1;
BA_ "U_P702_MY2021_Tx" SG_ 1057 EngIdlShutDwnTxt_D_Rq 1;
BA_ "U_T6_MCA_MY2020_Tx" SG_ 1057 EngIdlShutDwnTxt_D_Rq 1;
BA_ "U_CD542_MY2021_Tx" SG_ 1057 EngIdlShutDwnTxt_D_Rq 1;
BA_ "U_U55X_MY2022_Tx" SG_ 1057 EngIdlShutDwnTxt_D_Rq 1;
BA_ "U_CD764_MY2022_Tx" SG_ 1057 EngIdlShutDwnTxt_D_Rq 1;
BA_ "U_CDX706_MY2023_Tx" SG_ 1057 EngIdlShutDwnTxt_D_Rq 1;
BA_ "ContentDependant" SG_ 1057 EngIdlShutDown_D_Stat 1;
BA_ "U_T6_MCA_MY2020_Rx" SG_ 1057 EngIdlShutDown_D_Stat 1;
BA_ "ECGUsedRxSignal" SG_ 1057 EngIdlShutDown_D_Stat 1;
BA_ "U_CD542_MY2021_Rx" SG_ 1057 EngIdlShutDown_D_Stat 1;
BA_ "U_U55X_MY2022_Rx" SG_ 1057 EngIdlShutDown_D_Stat 1;
BA_ "U_CD764_MY2022_Rx" SG_ 1057 EngIdlShutDown_D_Stat 1;
BA_ "U_CDX706_MY2023_Rx" SG_ 1057 EngIdlShutDown_D_Stat 1;
BA_ "U_CX727_MY2021_Tx" SG_ 1057 EngIdlShutDown_D_Stat 1;
BA_ "U_P702_MY2021_Tx" SG_ 1057 EngIdlShutDown_D_Stat 1;
BA_ "U_T6_MCA_MY2020_Tx" SG_ 1057 EngIdlShutDown_D_Stat 1;
BA_ "U_CD542_MY2021_Tx" SG_ 1057 EngIdlShutDown_D_Stat 1;
BA_ "U_U55X_MY2022_Tx" SG_ 1057 EngIdlShutDown_D_Stat 1;
BA_ "U_CD764_MY2022_Tx" SG_ 1057 EngIdlShutDown_D_Stat 1;
BA_ "U_CDX706_MY2023_Tx" SG_ 1057 EngIdlShutDown_D_Stat 1;
BA_ "GenSigStartValueInteger" SG_ 1057 FUEL_ALCOHOL_PERCNT 255;
BA_ "ContentDependant" SG_ 1057 FUEL_ALCOHOL_PERCNT 1;
BA_ "GenSigStartValue" SG_ 1057 FUEL_ALCOHOL_PERCNT 255;
BA_ "U_CX727_MY2021_Tx" SG_ 1057 FUEL_ALCOHOL_PERCNT 1;
BA_ "U_P702_MY2021_Tx" SG_ 1057 FUEL_ALCOHOL_PERCNT 1;
BA_ "U_T6_MCA_MY2020_Tx" SG_ 1057 FUEL_ALCOHOL_PERCNT 1;
BA_ "U_CD542_MY2021_Tx" SG_ 1057 FUEL_ALCOHOL_PERCNT 1;
BA_ "U_U55X_MY2022_Tx" SG_ 1057 FUEL_ALCOHOL_PERCNT 1;
BA_ "U_CDX706_MY2023_Tx" SG_ 1057 FUEL_ALCOHOL_PERCNT 1;
BA_ "ContentDependant" SG_ 1057 TrnTotTq_Rt_Est 1;
BA_ "U_P702_MY2021_Tx" SG_ 1057 TrnTotTq_Rt_Est 1;
BA_ "U_T6_MCA_MY2020_Tx" SG_ 1057 TrnTotTq_Rt_Est 1;
BA_ "ContentDependant" SG_ 1057 TrnTotLss_Tq_Est 1;
BA_ "U_P702_MY2021_Tx" SG_ 1057 TrnTotLss_Tq_Est 1;
BA_ "U_T6_MCA_MY2020_Tx" SG_ 1057 TrnTotLss_Tq_Est 1;
BA_ "U_CX727_MY2021_Tx" SG_ 1057 ECMMILRequest 1;
BA_ "U_P702_MY2021_Tx" SG_ 1057 ECMMILRequest 1;
BA_ "U_T6_MCA_MY2020_Tx" SG_ 1057 ECMMILRequest 1;
BA_ "U_CD542_MY2021_Tx" SG_ 1057 ECMMILRequest 1;
BA_ "U_U55X_MY2022_Tx" SG_ 1057 ECMMILRequest 1;
BA_ "U_CD764_MY2022_Tx" SG_ 1057 ECMMILRequest 1;
BA_ "U_CDX706_MY2023_Tx" SG_ 1057 ECMMILRequest 1;
BA_ "U_CX727_MY2021_Rx" SG_ 1057 AirCondFluidHi_P_Actl 1;
BA_ "U_P702_MY2021_Rx" SG_ 1057 AirCondFluidHi_P_Actl 1;
BA_ "U_CD542_MY2021_Rx" SG_ 1057 AirCondFluidHi_P_Actl 1;
BA_ "U_CDX706_MY2023_Rx" SG_ 1057 AirCondFluidHi_P_Actl 1;
BA_ "U_CX727_MY2021_Tx" SG_ 1057 AirCondFluidHi_P_Actl 1;
BA_ "U_P702_MY2021_Tx" SG_ 1057 AirCondFluidHi_P_Actl 1;
BA_ "U_T6_MCA_MY2020_Tx" SG_ 1057 AirCondFluidHi_P_Actl 1;
BA_ "U_CD542_MY2021_Tx" SG_ 1057 AirCondFluidHi_P_Actl 1;
BA_ "U_U55X_MY2022_Tx" SG_ 1057 AirCondFluidHi_P_Actl 1;
BA_ "U_CD764_MY2022_Tx" SG_ 1057 AirCondFluidHi_P_Actl 1;
BA_ "U_CDX706_MY2023_Tx" SG_ 1057 AirCondFluidHi_P_Actl 1;
BA_ "U_CX727_MY2021_Tx" SG_ 1057 OilPressureWarning 1;
BA_ "U_P702_MY2021_Tx" SG_ 1057 OilPressureWarning 1;
BA_ "U_T6_MCA_MY2020_Tx" SG_ 1057 OilPressureWarning 1;
BA_ "U_CD542_MY2021_Tx" SG_ 1057 OilPressureWarning 1;
BA_ "U_U55X_MY2022_Tx" SG_ 1057 OilPressureWarning 1;
BA_ "U_CD764_MY2022_Tx" SG_ 1057 OilPressureWarning 1;
BA_ "U_CDX706_MY2023_Tx" SG_ 1057 OilPressureWarning 1;
BA_ "ContentDependant" SG_ 1057 VehVLimStat_D_Actl 1;
BA_ "U_P702_MY2021_Rx" SG_ 1057 VehVLimStat_D_Actl 1;
BA_ "U_T6_MCA_MY2020_Rx" SG_ 1057 VehVLimStat_D_Actl 1;
BA_ "U_P702_MY2021_Tx" SG_ 1057 VehVLimStat_D_Actl 1;
BA_ "U_T6_MCA_MY2020_Tx" SG_ 1057 VehVLimStat_D_Actl 1;
BA_ "ContentDependant" SG_ 1057 VehVLimActv_B_Actl 1;
BA_ "U_CX727_MY2021_Rx" SG_ 1057 VehVLimActv_B_Actl 1;
BA_ "U_P702_MY2021_Rx" SG_ 1057 VehVLimActv_B_Actl 1;
BA_ "U_T6_MCA_MY2020_Rx" SG_ 1057 VehVLimActv_B_Actl 1;
BA_ "U_CD542_MY2021_Rx" SG_ 1057 VehVLimActv_B_Actl 1;
BA_ "U_CDX706_MY2023_Rx" SG_ 1057 VehVLimActv_B_Actl 1;
BA_ "U_CX727_MY2021_Tx" SG_ 1057 VehVLimActv_B_Actl 1;
BA_ "U_P702_MY2021_Tx" SG_ 1057 VehVLimActv_B_Actl 1;
BA_ "U_T6_MCA_MY2020_Tx" SG_ 1057 VehVLimActv_B_Actl 1;
BA_ "U_CD542_MY2021_Tx" SG_ 1057 VehVLimActv_B_Actl 1;
BA_ "U_CDX706_MY2023_Tx" SG_ 1057 VehVLimActv_B_Actl 1;
BA_ "U_CX727_MY2021_Tx" SG_ 1057 CoolantFanStepAct 1;
BA_ "U_P702_MY2021_Tx" SG_ 1057 CoolantFanStepAct 1;
BA_ "U_T6_MCA_MY2020_Tx" SG_ 1057 CoolantFanStepAct 1;
BA_ "U_CD542_MY2021_Tx" SG_ 1057 CoolantFanStepAct 1;
BA_ "U_U55X_MY2022_Tx" SG_ 1057 CoolantFanStepAct 1;
BA_ "U_CD764_MY2022_Tx" SG_ 1057 CoolantFanStepAct 1;
BA_ "U_CDX706_MY2023_Tx" SG_ 1057 CoolantFanStepAct 1;
BA_ "U_CDX706_MY2023_Tx" SG_ 1055 DcdcIn_Pw2_Mx 1;
BA_ "U_T6_MCA_MY2020_Rx" SG_ 1055 EcoCochInstNeg_B_Dsply 1;
BA_ "ECGUsedRxSignal" SG_ 1055 EcoCochInstNeg_B_Dsply 1;
BA_ "U_CD542_MY2021_Rx" SG_ 1055 EcoCochInstNeg_B_Dsply 1;
BA_ "U_U55X_MY2022_Rx" SG_ 1055 EcoCochInstNeg_B_Dsply 1;
BA_ "U_CD764_MY2022_Rx" SG_ 1055 EcoCochInstNeg_B_Dsply 1;
BA_ "U_CX727_MY2021_Tx" SG_ 1055 EcoCochInstNeg_B_Dsply 1;
BA_ "U_P702_MY2021_Tx" SG_ 1055 EcoCochInstNeg_B_Dsply 1;
BA_ "U_T6_MCA_MY2020_Tx" SG_ 1055 EcoCochInstNeg_B_Dsply 1;
BA_ "U_CD542_MY2021_Tx" SG_ 1055 EcoCochInstNeg_B_Dsply 1;
BA_ "U_U55X_MY2022_Tx" SG_ 1055 EcoCochInstNeg_B_Dsply 1;
BA_ "U_CD764_MY2022_Tx" SG_ 1055 EcoCochInstNeg_B_Dsply 1;
BA_ "U_CDX706_MY2023_Tx" SG_ 1055 EcoCochInstNeg_B_Dsply 1;
BA_ "GenSigStartValueInteger" SG_ 1055 EcoCochShif_Pc_Dsply 255;
BA_ "GenSigStartValue" SG_ 1055 EcoCochShif_Pc_Dsply 255;
BA_ "U_T6_MCA_MY2020_Rx" SG_ 1055 EcoCochShif_Pc_Dsply 1;
BA_ "ECGUsedRxSignal" SG_ 1055 EcoCochShif_Pc_Dsply 1;
BA_ "U_CD542_MY2021_Rx" SG_ 1055 EcoCochShif_Pc_Dsply 1;
BA_ "U_U55X_MY2022_Rx" SG_ 1055 EcoCochShif_Pc_Dsply 1;
BA_ "U_CD764_MY2022_Rx" SG_ 1055 EcoCochShif_Pc_Dsply 1;
BA_ "U_CX727_MY2021_Tx" SG_ 1055 EcoCochShif_Pc_Dsply 1;
BA_ "U_P702_MY2021_Tx" SG_ 1055 EcoCochShif_Pc_Dsply 1;
BA_ "U_T6_MCA_MY2020_Tx" SG_ 1055 EcoCochShif_Pc_Dsply 1;
BA_ "U_CD542_MY2021_Tx" SG_ 1055 EcoCochShif_Pc_Dsply 1;
BA_ "U_U55X_MY2022_Tx" SG_ 1055 EcoCochShif_Pc_Dsply 1;
BA_ "U_CD764_MY2022_Tx" SG_ 1055 EcoCochShif_Pc_Dsply 1;
BA_ "U_CDX706_MY2023_Tx" SG_ 1055 EcoCochShif_Pc_Dsply 1;
BA_ "GenSigStartValueInteger" SG_ 1055 EcoCochInst_Pc_Dsply 1000;
BA_ "GenSigStartValue" SG_ 1055 EcoCochInst_Pc_Dsply 100;
BA_ "U_T6_MCA_MY2020_Rx" SG_ 1055 EcoCochInst_Pc_Dsply 1;
BA_ "ECGUsedRxSignal" SG_ 1055 EcoCochInst_Pc_Dsply 1;
BA_ "U_CD542_MY2021_Rx" SG_ 1055 EcoCochInst_Pc_Dsply 1;
BA_ "U_U55X_MY2022_Rx" SG_ 1055 EcoCochInst_Pc_Dsply 1;
BA_ "U_CD764_MY2022_Rx" SG_ 1055 EcoCochInst_Pc_Dsply 1;
BA_ "U_CX727_MY2021_Tx" SG_ 1055 EcoCochInst_Pc_Dsply 1;
BA_ "U_P702_MY2021_Tx" SG_ 1055 EcoCochInst_Pc_Dsply 1;
BA_ "U_T6_MCA_MY2020_Tx" SG_ 1055 EcoCochInst_Pc_Dsply 1;
BA_ "U_CD542_MY2021_Tx" SG_ 1055 EcoCochInst_Pc_Dsply 1;
BA_ "U_U55X_MY2022_Tx" SG_ 1055 EcoCochInst_Pc_Dsply 1;
BA_ "U_CD764_MY2022_Tx" SG_ 1055 EcoCochInst_Pc_Dsply 1;
BA_ "U_CDX706_MY2023_Tx" SG_ 1055 EcoCochInst_Pc_Dsply 1;
BA_ "GenSigStartValueInteger" SG_ 1055 EcoCochIdlFuel_Pc_Dsply 255;
BA_ "GenSigStartValue" SG_ 1055 EcoCochIdlFuel_Pc_Dsply 255;
BA_ "U_T6_MCA_MY2020_Rx" SG_ 1055 EcoCochIdlFuel_Pc_Dsply 1;
BA_ "ECGUsedRxSignal" SG_ 1055 EcoCochIdlFuel_Pc_Dsply 1;
BA_ "U_CD542_MY2021_Rx" SG_ 1055 EcoCochIdlFuel_Pc_Dsply 1;
BA_ "U_U55X_MY2022_Rx" SG_ 1055 EcoCochIdlFuel_Pc_Dsply 1;
BA_ "U_CD764_MY2022_Rx" SG_ 1055 EcoCochIdlFuel_Pc_Dsply 1;
BA_ "U_CX727_MY2021_Tx" SG_ 1055 EcoCochIdlFuel_Pc_Dsply 1;
BA_ "U_P702_MY2021_Tx" SG_ 1055 EcoCochIdlFuel_Pc_Dsply 1;
BA_ "U_T6_MCA_MY2020_Tx" SG_ 1055 EcoCochIdlFuel_Pc_Dsply 1;
BA_ "U_CD542_MY2021_Tx" SG_ 1055 EcoCochIdlFuel_Pc_Dsply 1;
BA_ "U_U55X_MY2022_Tx" SG_ 1055 EcoCochIdlFuel_Pc_Dsply 1;
BA_ "U_CD764_MY2022_Tx" SG_ 1055 EcoCochIdlFuel_Pc_Dsply 1;
BA_ "U_CDX706_MY2023_Tx" SG_ 1055 EcoCochIdlFuel_Pc_Dsply 1;
BA_ "GenSigStartValueInteger" SG_ 1055 EcoCochDecel_Pc_Dsply 255;
BA_ "GenSigStartValue" SG_ 1055 EcoCochDecel_Pc_Dsply 255;
BA_ "U_T6_MCA_MY2020_Rx" SG_ 1055 EcoCochDecel_Pc_Dsply 1;
BA_ "ECGUsedRxSignal" SG_ 1055 EcoCochDecel_Pc_Dsply 1;
BA_ "U_U55X_MY2022_Rx" SG_ 1055 EcoCochDecel_Pc_Dsply 1;
BA_ "U_CD764_MY2022_Rx" SG_ 1055 EcoCochDecel_Pc_Dsply 1;
BA_ "U_CX727_MY2021_Tx" SG_ 1055 EcoCochDecel_Pc_Dsply 1;
BA_ "U_P702_MY2021_Tx" SG_ 1055 EcoCochDecel_Pc_Dsply 1;
BA_ "U_T6_MCA_MY2020_Tx" SG_ 1055 EcoCochDecel_Pc_Dsply 1;
BA_ "U_CD542_MY2021_Tx" SG_ 1055 EcoCochDecel_Pc_Dsply 1;
BA_ "U_U55X_MY2022_Tx" SG_ 1055 EcoCochDecel_Pc_Dsply 1;
BA_ "U_CD764_MY2022_Tx" SG_ 1055 EcoCochDecel_Pc_Dsply 1;
BA_ "U_CDX706_MY2023_Tx" SG_ 1055 EcoCochDecel_Pc_Dsply 1;
BA_ "GenSigStartValueInteger" SG_ 1055 EcoCochCrus_Pc_Dsply 255;
BA_ "GenSigStartValue" SG_ 1055 EcoCochCrus_Pc_Dsply 255;
BA_ "U_T6_MCA_MY2020_Rx" SG_ 1055 EcoCochCrus_Pc_Dsply 1;
BA_ "ECGUsedRxSignal" SG_ 1055 EcoCochCrus_Pc_Dsply 1;
BA_ "U_U55X_MY2022_Rx" SG_ 1055 EcoCochCrus_Pc_Dsply 1;
BA_ "U_CD764_MY2022_Rx" SG_ 1055 EcoCochCrus_Pc_Dsply 1;
BA_ "U_CX727_MY2021_Tx" SG_ 1055 EcoCochCrus_Pc_Dsply 1;
BA_ "U_P702_MY2021_Tx" SG_ 1055 EcoCochCrus_Pc_Dsply 1;
BA_ "U_T6_MCA_MY2020_Tx" SG_ 1055 EcoCochCrus_Pc_Dsply 1;
BA_ "U_CD542_MY2021_Tx" SG_ 1055 EcoCochCrus_Pc_Dsply 1;
BA_ "U_U55X_MY2022_Tx" SG_ 1055 EcoCochCrus_Pc_Dsply 1;
BA_ "U_CD764_MY2022_Tx" SG_ 1055 EcoCochCrus_Pc_Dsply 1;
BA_ "U_CDX706_MY2023_Tx" SG_ 1055 EcoCochCrus_Pc_Dsply 1;
BA_ "GenSigStartValueInteger" SG_ 1055 EcoCochA_Pc_Dsply 255;
BA_ "GenSigStartValue" SG_ 1055 EcoCochA_Pc_Dsply 255;
BA_ "U_T6_MCA_MY2020_Rx" SG_ 1055 EcoCochA_Pc_Dsply 1;
BA_ "ECGUsedRxSignal" SG_ 1055 EcoCochA_Pc_Dsply 1;
BA_ "U_U55X_MY2022_Rx" SG_ 1055 EcoCochA_Pc_Dsply 1;
BA_ "U_CD764_MY2022_Rx" SG_ 1055 EcoCochA_Pc_Dsply 1;
BA_ "U_CX727_MY2021_Tx" SG_ 1055 EcoCochA_Pc_Dsply 1;
BA_ "U_P702_MY2021_Tx" SG_ 1055 EcoCochA_Pc_Dsply 1;
BA_ "U_T6_MCA_MY2020_Tx" SG_ 1055 EcoCochA_Pc_Dsply 1;
BA_ "U_CD542_MY2021_Tx" SG_ 1055 EcoCochA_Pc_Dsply 1;
BA_ "U_U55X_MY2022_Tx" SG_ 1055 EcoCochA_Pc_Dsply 1;
BA_ "U_CD764_MY2022_Tx" SG_ 1055 EcoCochA_Pc_Dsply 1;
BA_ "U_CDX706_MY2023_Tx" SG_ 1055 EcoCochA_Pc_Dsply 1;
BA_ "U_CX727_MY2021_Tx" SG_ 610 AwdLckWhlRr_Pc_RqDsply 1;
BA_ "U_T6_MCA_MY2020_Tx" SG_ 610 AwdLckWhlRr_Pc_RqDsply 1;
BA_ "U_CX727_MY2021_Tx" SG_ 610 AwdLckWhlRl_Pc_RqDsply 1;
BA_ "U_T6_MCA_MY2020_Tx" SG_ 610 AwdLckWhlRl_Pc_RqDsply 1;
BA_ "U_CX727_MY2021_Tx" SG_ 610 AwdLckWhlFr_Pc_RqDsply 1;
BA_ "U_T6_MCA_MY2020_Tx" SG_ 610 AwdLckWhlFr_Pc_RqDsply 1;
BA_ "U_CX727_MY2021_Tx" SG_ 610 AwdLckWhlFl_Pc_RqDsply 1;
BA_ "U_T6_MCA_MY2020_Tx" SG_ 610 AwdLckWhlFl_Pc_RqDsply 1;
BA_ "ContentDependant" SG_ 562 OnePdlDrvDStat_No_Cnt 1;
BA_ "MetaData" SG_ 562 OnePdlDrvDStat_No_Cnt 1;
BA_ "ContentDependant" SG_ 562 OnePdlDrvDStat_No_Cs 1;
BA_ "MetaData" SG_ 562 OnePdlDrvDStat_No_Cs 1;
BA_ "ContentDependant" SG_ 562 GearNtrl_No_Cs 1;
BA_ "MetaData" SG_ 562 GearNtrl_No_Cs 1;
BA_ "U_CX727_MY2021_Rx" SG_ 562 GearNtrl_No_Cs 1;
BA_ "U_T6_MCA_MY2020_Rx" SG_ 562 GearNtrl_No_Cs 1;
BA_ "U_CD542_MY2021_Rx" SG_ 562 GearNtrl_No_Cs 1;
BA_ "U_CD764_MY2022_Rx" SG_ 562 GearNtrl_No_Cs 1;
BA_ "U_CDX706_MY2023_Rx" SG_ 562 GearNtrl_No_Cs 1;
BA_ "U_P702_MY2021_Tx" SG_ 562 GearNtrl_No_Cs 1;
BA_ "U_T6_MCA_MY2020_Tx" SG_ 562 GearNtrl_No_Cs 1;
BA_ "U_CD542_MY2021_Tx" SG_ 562 GearNtrl_No_Cs 1;
BA_ "GenSigSendType" SG_ 562 GearNtrl_D_Stat 3;
BA_ "GenSigStartValueInteger" SG_ 562 GearNtrl_D_Stat 2;
BA_ "GenSigStartValue" SG_ 562 GearNtrl_D_Stat 2;
BA_ "U_CX727_MY2021_Rx" SG_ 562 GearNtrl_D_Stat 1;
BA_ "U_P702_MY2021_Rx" SG_ 562 GearNtrl_D_Stat 1;
BA_ "U_T6_MCA_MY2020_Rx" SG_ 562 GearNtrl_D_Stat 1;
BA_ "U_CD542_MY2021_Rx" SG_ 562 GearNtrl_D_Stat 1;
BA_ "U_U55X_MY2022_Rx" SG_ 562 GearNtrl_D_Stat 1;
BA_ "U_CD764_MY2022_Rx" SG_ 562 GearNtrl_D_Stat 1;
BA_ "U_CDX706_MY2023_Rx" SG_ 562 GearNtrl_D_Stat 1;
BA_ "U_P702_MY2021_Tx" SG_ 562 GearNtrl_D_Stat 1;
BA_ "U_T6_MCA_MY2020_Tx" SG_ 562 GearNtrl_D_Stat 1;
BA_ "U_CD542_MY2021_Tx" SG_ 562 GearNtrl_D_Stat 1;
BA_ "GenSigSendType" SG_ 562 OnePdlDrv_D_Stat 3;
BA_ "ContentDependant" SG_ 562 GearNtrl_No_Cnt 1;
BA_ "MetaData" SG_ 562 GearNtrl_No_Cnt 1;
BA_ "U_CX727_MY2021_Rx" SG_ 562 GearNtrl_No_Cnt 1;
BA_ "U_T6_MCA_MY2020_Rx" SG_ 562 GearNtrl_No_Cnt 1;
BA_ "U_CD542_MY2021_Rx" SG_ 562 GearNtrl_No_Cnt 1;
BA_ "U_CD764_MY2022_Rx" SG_ 562 GearNtrl_No_Cnt 1;
BA_ "U_CDX706_MY2023_Rx" SG_ 562 GearNtrl_No_Cnt 1;
BA_ "U_P702_MY2021_Tx" SG_ 562 GearNtrl_No_Cnt 1;
BA_ "U_T6_MCA_MY2020_Tx" SG_ 562 GearNtrl_No_Cnt 1;
BA_ "U_CD542_MY2021_Tx" SG_ 562 GearNtrl_No_Cnt 1;
BA_ "U_P702_MY2021_Tx" SG_ 523 EngAirFiltMsgTxt_D_Rq 1;
BA_ "U_T6_MCA_MY2020_Tx" SG_ 523 EngAirFiltMsgTxt_D_Rq 1;
BA_ "U_CDX706_MY2023_Tx" SG_ 523 EngAirFiltMsgTxt_D_Rq 1;
BA_ "U_P702_MY2021_Tx" SG_ 523 WaterInFuel_B_Falt 1;
BA_ "U_T6_MCA_MY2020_Tx" SG_ 523 WaterInFuel_B_Falt 1;
BA_ "U_P702_MY2021_Tx" SG_ 523 UreaMnAdd_L2_Actl 1;
BA_ "U_T6_MCA_MY2020_Tx" SG_ 523 UreaMnAdd_L2_Actl 1;
BA_ "U_T6_MCA_MY2020_Rx" SG_ 523 VehUreaRnge3_L_DsplyMx 1;
BA_ "ECGUsedRxSignal" SG_ 523 VehUreaRnge3_L_DsplyMx 1;
BA_ "U_U55X_MY2022_Rx" SG_ 523 VehUreaRnge3_L_DsplyMx 1;
BA_ "U_CD764_MY2022_Rx" SG_ 523 VehUreaRnge3_L_DsplyMx 1;
BA_ "U_CDX706_MY2023_Rx" SG_ 523 VehUreaRnge3_L_DsplyMx 1;
BA_ "U_P702_MY2021_Tx" SG_ 523 VehUreaRnge3_L_DsplyMx 1;
BA_ "U_T6_MCA_MY2020_Tx" SG_ 523 VehUreaRnge3_L_DsplyMx 1;
BA_ "GenSigStartValueInteger" SG_ 523 UreaMxAdd_L2_Actl 510;
BA_ "GenSigStartValue" SG_ 523 UreaMxAdd_L2_Actl 510;
BA_ "U_P702_MY2021_Tx" SG_ 523 UreaMxAdd_L2_Actl 1;
BA_ "U_T6_MCA_MY2020_Tx" SG_ 523 UreaMxAdd_L2_Actl 1;
BA_ "GenSigStartValueInteger" SG_ 519 RearDiffLck_Tq_Rq 16382;
BA_ "GenSigStartValue" SG_ 519 RearDiffLck_Tq_Rq 16382;
BA_ "U_U55X_MY2022_Tx" SG_ 519 RearDiffLck_Tq_Rq 1;
BA_ "U_T6_MCA_MY2020_Rx" SG_ 517 FapLc_B_Err 1;
BA_ "U_CD542_MY2021_Rx" SG_ 517 FapLc_B_Err 1;
BA_ "U_U55X_MY2022_Rx" SG_ 517 FapLc_B_Err 1;
BA_ "U_CD764_MY2022_Rx" SG_ 517 FapLc_B_Err 1;
BA_ "U_CDX706_MY2023_Rx" SG_ 517 FapLc_B_Err 1;
BA_ "U_CX727_MY2021_Tx" SG_ 517 FapLc_B_Err 1;
BA_ "U_P702_MY2021_Tx" SG_ 517 FapLc_B_Err 1;
BA_ "U_T6_MCA_MY2020_Tx" SG_ 517 FapLc_B_Err 1;
BA_ "U_CD542_MY2021_Tx" SG_ 517 FapLc_B_Err 1;
BA_ "U_CD764_MY2022_Tx" SG_ 517 FapLc_B_Err 1;
BA_ "U_CDX706_MY2023_Tx" SG_ 517 FapLc_B_Err 1;
BA_ "U_CX727_MY2021_Rx" SG_ 517 BrkTot_Tq_RqFapLc 1;
BA_ "U_P702_MY2021_Rx" SG_ 517 BrkTot_Tq_RqFapLc 1;
BA_ "U_T6_MCA_MY2020_Rx" SG_ 517 BrkTot_Tq_RqFapLc 1;
BA_ "U_CD542_MY2021_Rx" SG_ 517 BrkTot_Tq_RqFapLc 1;
BA_ "U_U55X_MY2022_Rx" SG_ 517 BrkTot_Tq_RqFapLc 1;
BA_ "U_CD764_MY2022_Rx" SG_ 517 BrkTot_Tq_RqFapLc 1;
BA_ "U_CDX706_MY2023_Rx" SG_ 517 BrkTot_Tq_RqFapLc 1;
BA_ "U_CX727_MY2021_Tx" SG_ 517 BrkTot_Tq_RqFapLc 1;
BA_ "U_P702_MY2021_Tx" SG_ 517 BrkTot_Tq_RqFapLc 1;
BA_ "U_T6_MCA_MY2020_Tx" SG_ 517 BrkTot_Tq_RqFapLc 1;
BA_ "U_CD542_MY2021_Tx" SG_ 517 BrkTot_Tq_RqFapLc 1;
BA_ "U_U55X_MY2022_Tx" SG_ 517 BrkTot_Tq_RqFapLc 1;
BA_ "U_CD764_MY2022_Tx" SG_ 517 BrkTot_Tq_RqFapLc 1;
BA_ "U_CDX706_MY2023_Tx" SG_ 517 BrkTot_Tq_RqFapLc 1;
BA_ "U_T6_MCA_MY2020_Rx" SG_ 517 TrnAin_Pc_RqDrv 1;
BA_ "U_U55X_MY2022_Rx" SG_ 517 TrnAin_Pc_RqDrv 1;
BA_ "U_P702_MY2021_Tx" SG_ 517 TrnAin_Pc_RqDrv 1;
BA_ "U_T6_MCA_MY2020_Tx" SG_ 517 TrnAin_Pc_RqDrv 1;
BA_ "U_CD542_MY2021_Tx" SG_ 517 TrnAin_Pc_RqDrv 1;
BA_ "U_U55X_MY2022_Tx" SG_ 517 TrnAin_Pc_RqDrv 1;
BA_ "GenSigStartValueInteger" SG_ 516 EngAoutNActl_D_QF 1;
BA_ "MetaData" SG_ 516 EngAoutNActl_D_QF 1;
BA_ "GenSigStartValue" SG_ 516 EngAoutNActl_D_QF 1;
BA_ "U_P702_MY2021_Rx" SG_ 516 EngAoutNActl_D_QF 1;
BA_ "U_T6_MCA_MY2020_Rx" SG_ 516 EngAoutNActl_D_QF 1;
BA_ "U_CX727_MY2021_Tx" SG_ 516 EngAoutNActl_D_QF 1;
BA_ "U_P702_MY2021_Tx" SG_ 516 EngAoutNActl_D_QF 1;
BA_ "U_T6_MCA_MY2020_Tx" SG_ 516 EngAoutNActl_D_QF 1;
BA_ "ContentDependant" SG_ 516 EngAout3_N_Actl 1;
BA_ "U_CX727_MY2021_Rx" SG_ 516 EngAout3_N_Actl 1;
BA_ "U_P702_MY2021_Rx" SG_ 516 EngAout3_N_Actl 1;
BA_ "U_CD542_MY2021_Rx" SG_ 516 EngAout3_N_Actl 1;
BA_ "U_CDX706_MY2023_Rx" SG_ 516 EngAout3_N_Actl 1;
BA_ "U_P702_MY2021_Tx" SG_ 516 EngAout3_N_Actl 1;
BA_ "U_CD542_MY2021_Tx" SG_ 516 EngAout3_N_Actl 1;
BA_ "U_CDX706_MY2023_Tx" SG_ 516 EngAout3_N_Actl 1;
BA_ "U_CX727_MY2021_Rx" SG_ 516 ApedPos_Pc_ActlArb 1;
BA_ "U_P702_MY2021_Rx" SG_ 516 ApedPos_Pc_ActlArb 1;
BA_ "U_T6_MCA_MY2020_Rx" SG_ 516 ApedPos_Pc_ActlArb 1;
BA_ "ECGUsedRxSignal" SG_ 516 ApedPos_Pc_ActlArb 1;
BA_ "U_CD542_MY2021_Rx" SG_ 516 ApedPos_Pc_ActlArb 1;
BA_ "U_U55X_MY2022_Rx" SG_ 516 ApedPos_Pc_ActlArb 1;
BA_ "U_CD764_MY2022_Rx" SG_ 516 ApedPos_Pc_ActlArb 1;
BA_ "U_CDX706_MY2023_Rx" SG_ 516 ApedPos_Pc_ActlArb 1;
BA_ "U_CX727_MY2021_Tx" SG_ 516 ApedPos_Pc_ActlArb 1;
BA_ "U_P702_MY2021_Tx" SG_ 516 ApedPos_Pc_ActlArb 1;
BA_ "U_T6_MCA_MY2020_Tx" SG_ 516 ApedPos_Pc_ActlArb 1;
BA_ "U_CD542_MY2021_Tx" SG_ 516 ApedPos_Pc_ActlArb 1;
BA_ "U_U55X_MY2022_Tx" SG_ 516 ApedPos_Pc_ActlArb 1;
BA_ "U_CD764_MY2022_Tx" SG_ 516 ApedPos_Pc_ActlArb 1;
BA_ "U_CDX706_MY2023_Tx" SG_ 516 ApedPos_Pc_ActlArb 1;
BA_ "GenSigStartValueInteger" SG_ 516 ApedPosPcActl_D_Qf 1;
BA_ "MetaData" SG_ 516 ApedPosPcActl_D_Qf 1;
BA_ "GenSigStartValue" SG_ 516 ApedPosPcActl_D_Qf 1;
BA_ "U_CX727_MY2021_Rx" SG_ 516 ApedPosPcActl_D_Qf 1;
BA_ "U_P702_MY2021_Rx" SG_ 516 ApedPosPcActl_D_Qf 1;
BA_ "U_T6_MCA_MY2020_Rx" SG_ 516 ApedPosPcActl_D_Qf 1;
BA_ "U_CD542_MY2021_Rx" SG_ 516 ApedPosPcActl_D_Qf 1;
BA_ "U_U55X_MY2022_Rx" SG_ 516 ApedPosPcActl_D_Qf 1;
BA_ "U_CD764_MY2022_Rx" SG_ 516 ApedPosPcActl_D_Qf 1;
BA_ "U_CDX706_MY2023_Rx" SG_ 516 ApedPosPcActl_D_Qf 1;
BA_ "U_CX727_MY2021_Tx" SG_ 516 ApedPosPcActl_D_Qf 1;
BA_ "U_P702_MY2021_Tx" SG_ 516 ApedPosPcActl_D_Qf 1;
BA_ "U_T6_MCA_MY2020_Tx" SG_ 516 ApedPosPcActl_D_Qf 1;
BA_ "U_CD542_MY2021_Tx" SG_ 516 ApedPosPcActl_D_Qf 1;
BA_ "U_U55X_MY2022_Tx" SG_ 516 ApedPosPcActl_D_Qf 1;
BA_ "U_CD764_MY2022_Tx" SG_ 516 ApedPosPcActl_D_Qf 1;
BA_ "U_CDX706_MY2023_Tx" SG_ 516 ApedPosPcActl_D_Qf 1;
BA_ "U_CX727_MY2021_Rx" SG_ 516 EngAout_N_Actl 1;
BA_ "U_P702_MY2021_Rx" SG_ 516 EngAout_N_Actl 1;
BA_ "U_T6_MCA_MY2020_Rx" SG_ 516 EngAout_N_Actl 1;
BA_ "ECGUsedRxSignal" SG_ 516 EngAout_N_Actl 1;
BA_ "U_CD542_MY2021_Rx" SG_ 516 EngAout_N_Actl 1;
BA_ "U_U55X_MY2022_Rx" SG_ 516 EngAout_N_Actl 1;
BA_ "U_CD764_MY2022_Rx" SG_ 516 EngAout_N_Actl 1;
BA_ "U_CDX706_MY2023_Rx" SG_ 516 EngAout_N_Actl 1;
BA_ "U_CX727_MY2021_Tx" SG_ 516 EngAout_N_Actl 1;
BA_ "U_P702_MY2021_Tx" SG_ 516 EngAout_N_Actl 1;
BA_ "U_T6_MCA_MY2020_Tx" SG_ 516 EngAout_N_Actl 1;
BA_ "U_CD542_MY2021_Tx" SG_ 516 EngAout_N_Actl 1;
BA_ "U_U55X_MY2022_Tx" SG_ 516 EngAout_N_Actl 1;
BA_ "U_CD764_MY2022_Tx" SG_ 516 EngAout_N_Actl 1;
BA_ "U_CDX706_MY2023_Tx" SG_ 516 EngAout_N_Actl 1;
BA_ "ContentDependant" SG_ 516 ApedPosPcActl_No_Cnt 1;
BA_ "MetaData" SG_ 516 ApedPosPcActl_No_Cnt 1;
BA_ "U_CX727_MY2021_Rx" SG_ 516 ApedPosPcActl_No_Cnt 1;
BA_ "U_P702_MY2021_Rx" SG_ 516 ApedPosPcActl_No_Cnt 1;
BA_ "U_CD542_MY2021_Rx" SG_ 516 ApedPosPcActl_No_Cnt 1;
BA_ "U_U55X_MY2022_Rx" SG_ 516 ApedPosPcActl_No_Cnt 1;
BA_ "U_CD764_MY2022_Rx" SG_ 516 ApedPosPcActl_No_Cnt 1;
BA_ "U_CDX706_MY2023_Rx" SG_ 516 ApedPosPcActl_No_Cnt 1;
BA_ "U_CX727_MY2021_Tx" SG_ 516 ApedPosPcActl_No_Cnt 1;
BA_ "U_P702_MY2021_Tx" SG_ 516 ApedPosPcActl_No_Cnt 1;
BA_ "U_T6_MCA_MY2020_Tx" SG_ 516 ApedPosPcActl_No_Cnt 1;
BA_ "U_CD542_MY2021_Tx" SG_ 516 ApedPosPcActl_No_Cnt 1;
BA_ "U_CDX706_MY2023_Tx" SG_ 516 ApedPosPcActl_No_Cnt 1;
BA_ "ContentDependant" SG_ 516 ApedPosPcActl_No_Cs 1;
BA_ "MetaData" SG_ 516 ApedPosPcActl_No_Cs 1;
BA_ "U_CX727_MY2021_Rx" SG_ 516 ApedPosPcActl_No_Cs 1;
BA_ "U_P702_MY2021_Rx" SG_ 516 ApedPosPcActl_No_Cs 1;
BA_ "U_CD542_MY2021_Rx" SG_ 516 ApedPosPcActl_No_Cs 1;
BA_ "U_U55X_MY2022_Rx" SG_ 516 ApedPosPcActl_No_Cs 1;
BA_ "U_CD764_MY2022_Rx" SG_ 516 ApedPosPcActl_No_Cs 1;
BA_ "U_CDX706_MY2023_Rx" SG_ 516 ApedPosPcActl_No_Cs 1;
BA_ "U_CX727_MY2021_Tx" SG_ 516 ApedPosPcActl_No_Cs 1;
BA_ "U_P702_MY2021_Tx" SG_ 516 ApedPosPcActl_No_Cs 1;
BA_ "U_T6_MCA_MY2020_Tx" SG_ 516 ApedPosPcActl_No_Cs 1;
BA_ "U_CD542_MY2021_Tx" SG_ 516 ApedPosPcActl_No_Cs 1;
BA_ "U_CDX706_MY2023_Tx" SG_ 516 ApedPosPcActl_No_Cs 1;
BA_ "U_P702_MY2021_Rx" SG_ 516 ApedPos_PcRate_ActlArb 1;
BA_ "U_T6_MCA_MY2020_Rx" SG_ 516 ApedPos_PcRate_ActlArb 1;
BA_ "U_CDX706_MY2023_Rx" SG_ 516 ApedPos_PcRate_ActlArb 1;
BA_ "U_CX727_MY2021_Tx" SG_ 516 ApedPos_PcRate_ActlArb 1;
BA_ "U_P702_MY2021_Tx" SG_ 516 ApedPos_PcRate_ActlArb 1;
BA_ "U_T6_MCA_MY2020_Tx" SG_ 516 ApedPos_PcRate_ActlArb 1;
BA_ "U_CD542_MY2021_Tx" SG_ 516 ApedPos_PcRate_ActlArb 1;
BA_ "U_U55X_MY2022_Tx" SG_ 516 ApedPos_PcRate_ActlArb 1;
BA_ "U_CD764_MY2022_Tx" SG_ 516 ApedPos_PcRate_ActlArb 1;
BA_ "U_CDX706_MY2023_Tx" SG_ 516 ApedPos_PcRate_ActlArb 1;
BA_ "U_CX727_MY2021_Tx" SG_ 514 StrtrMtrDlyStrt_B_Stat 1;
BA_ "U_P702_MY2021_Tx" SG_ 514 StrtrMtrDlyStrt_B_Stat 1;
BA_ "U_T6_MCA_MY2020_Tx" SG_ 514 StrtrMtrDlyStrt_B_Stat 1;
BA_ "U_CD542_MY2021_Tx" SG_ 514 StrtrMtrDlyStrt_B_Stat 1;
BA_ "U_U55X_MY2022_Tx" SG_ 514 StrtrMtrDlyStrt_B_Stat 1;
BA_ "U_CD764_MY2022_Tx" SG_ 514 StrtrMtrDlyStrt_B_Stat 1;
BA_ "U_CDX706_MY2023_Tx" SG_ 514 StrtrMtrDlyStrt_B_Stat 1;
BA_ "U_P702_MY2021_Rx" SG_ 514 VehVTrlrAid_B_Avail 1;
BA_ "U_T6_MCA_MY2020_Rx" SG_ 514 VehVTrlrAid_B_Avail 1;
BA_ "U_U55X_MY2022_Rx" SG_ 514 VehVTrlrAid_B_Avail 1;
BA_ "U_P702_MY2021_Tx" SG_ 514 VehVTrlrAid_B_Avail 1;
BA_ "U_T6_MCA_MY2020_Tx" SG_ 514 VehVTrlrAid_B_Avail 1;
BA_ "U_U55X_MY2022_Tx" SG_ 514 VehVTrlrAid_B_Avail 1;
BA_ "U_CD764_MY2022_Tx" SG_ 514 VehVTrlrAid_B_Avail 1;
BA_ "U_CDX706_MY2023_Tx" SG_ 514 VehVTrlrAid_B_Avail 1;
BA_ "U_CX727_MY2021_Tx" SG_ 514 StrtrMtrCtlMsgTxt_D_Rq 1;
BA_ "U_P702_MY2021_Tx" SG_ 514 StrtrMtrCtlMsgTxt_D_Rq 1;
BA_ "U_T6_MCA_MY2020_Tx" SG_ 514 StrtrMtrCtlMsgTxt_D_Rq 1;
BA_ "U_CD542_MY2021_Tx" SG_ 514 StrtrMtrCtlMsgTxt_D_Rq 1;
BA_ "U_U55X_MY2022_Tx" SG_ 514 StrtrMtrCtlMsgTxt_D_Rq 1;
BA_ "U_CD764_MY2022_Tx" SG_ 514 StrtrMtrCtlMsgTxt_D_Rq 1;
BA_ "U_CDX706_MY2023_Tx" SG_ 514 StrtrMtrCtlMsgTxt_D_Rq 1;
BA_ "MetaData" SG_ 514 VehVActlEng_No_Cs 1;
BA_ "U_CX727_MY2021_Rx" SG_ 514 VehVActlEng_No_Cs 1;
BA_ "U_P702_MY2021_Rx" SG_ 514 VehVActlEng_No_Cs 1;
BA_ "U_T6_MCA_MY2020_Rx" SG_ 514 VehVActlEng_No_Cs 1;
BA_ "U_CD542_MY2021_Rx" SG_ 514 VehVActlEng_No_Cs 1;
BA_ "U_U55X_MY2022_Rx" SG_ 514 VehVActlEng_No_Cs 1;
BA_ "U_CD764_MY2022_Rx" SG_ 514 VehVActlEng_No_Cs 1;
BA_ "U_CDX706_MY2023_Rx" SG_ 514 VehVActlEng_No_Cs 1;
BA_ "U_CX727_MY2021_Tx" SG_ 514 VehVActlEng_No_Cs 1;
BA_ "U_P702_MY2021_Tx" SG_ 514 VehVActlEng_No_Cs 1;
BA_ "U_T6_MCA_MY2020_Tx" SG_ 514 VehVActlEng_No_Cs 1;
BA_ "U_CD542_MY2021_Tx" SG_ 514 VehVActlEng_No_Cs 1;
BA_ "U_U55X_MY2022_Tx" SG_ 514 VehVActlEng_No_Cs 1;
BA_ "U_CD764_MY2022_Tx" SG_ 514 VehVActlEng_No_Cs 1;
BA_ "U_CDX706_MY2023_Tx" SG_ 514 VehVActlEng_No_Cs 1;
BA_ "MetaData" SG_ 514 VehVActlEng_No_Cnt 1;
BA_ "U_CX727_MY2021_Rx" SG_ 514 VehVActlEng_No_Cnt 1;
BA_ "U_P702_MY2021_Rx" SG_ 514 VehVActlEng_No_Cnt 1;
BA_ "U_T6_MCA_MY2020_Rx" SG_ 514 VehVActlEng_No_Cnt 1;
BA_ "U_CD542_MY2021_Rx" SG_ 514 VehVActlEng_No_Cnt 1;
BA_ "U_U55X_MY2022_Rx" SG_ 514 VehVActlEng_No_Cnt 1;
BA_ "U_CD764_MY2022_Rx" SG_ 514 VehVActlEng_No_Cnt 1;
BA_ "U_CDX706_MY2023_Rx" SG_ 514 VehVActlEng_No_Cnt 1;
BA_ "U_CX727_MY2021_Tx" SG_ 514 VehVActlEng_No_Cnt 1;
BA_ "U_P702_MY2021_Tx" SG_ 514 VehVActlEng_No_Cnt 1;
BA_ "U_T6_MCA_MY2020_Tx" SG_ 514 VehVActlEng_No_Cnt 1;
BA_ "U_CD542_MY2021_Tx" SG_ 514 VehVActlEng_No_Cnt 1;
BA_ "U_U55X_MY2022_Tx" SG_ 514 VehVActlEng_No_Cnt 1;
BA_ "U_CD764_MY2022_Tx" SG_ 514 VehVActlEng_No_Cnt 1;
BA_ "U_CDX706_MY2023_Tx" SG_ 514 VehVActlEng_No_Cnt 1;
BA_ "U_CX727_MY2021_Rx" SG_ 514 Veh_V_RqCcSet 1;
BA_ "U_P702_MY2021_Rx" SG_ 514 Veh_V_RqCcSet 1;
BA_ "U_T6_MCA_MY2020_Rx" SG_ 514 Veh_V_RqCcSet 1;
BA_ "U_CD542_MY2021_Rx" SG_ 514 Veh_V_RqCcSet 1;
BA_ "U_U55X_MY2022_Rx" SG_ 514 Veh_V_RqCcSet 1;
BA_ "U_CD764_MY2022_Rx" SG_ 514 Veh_V_RqCcSet 1;
BA_ "U_CDX706_MY2023_Rx" SG_ 514 Veh_V_RqCcSet 1;
BA_ "U_CX727_MY2021_Tx" SG_ 514 Veh_V_RqCcSet 1;
BA_ "U_P702_MY2021_Tx" SG_ 514 Veh_V_RqCcSet 1;
BA_ "U_T6_MCA_MY2020_Tx" SG_ 514 Veh_V_RqCcSet 1;
BA_ "U_CD542_MY2021_Tx" SG_ 514 Veh_V_RqCcSet 1;
BA_ "U_U55X_MY2022_Tx" SG_ 514 Veh_V_RqCcSet 1;
BA_ "U_CD764_MY2022_Tx" SG_ 514 Veh_V_RqCcSet 1;
BA_ "U_CDX706_MY2023_Tx" SG_ 514 Veh_V_RqCcSet 1;
BA_ "MetaData" SG_ 514 VehVActlEng_D_Qf 1;
BA_ "U_CX727_MY2021_Rx" SG_ 514 VehVActlEng_D_Qf 1;
BA_ "U_P702_MY2021_Rx" SG_ 514 VehVActlEng_D_Qf 1;
BA_ "U_T6_MCA_MY2020_Rx" SG_ 514 VehVActlEng_D_Qf 1;
BA_ "ECGUsedRxSignal" SG_ 514 VehVActlEng_D_Qf 1;
BA_ "U_CD542_MY2021_Rx" SG_ 514 VehVActlEng_D_Qf 1;
BA_ "U_U55X_MY2022_Rx" SG_ 514 VehVActlEng_D_Qf 1;
BA_ "U_CD764_MY2022_Rx" SG_ 514 VehVActlEng_D_Qf 1;
BA_ "U_CDX706_MY2023_Rx" SG_ 514 VehVActlEng_D_Qf 1;
BA_ "U_CX727_MY2021_Tx" SG_ 514 VehVActlEng_D_Qf 1;
BA_ "U_P702_MY2021_Tx" SG_ 514 VehVActlEng_D_Qf 1;
BA_ "U_T6_MCA_MY2020_Tx" SG_ 514 VehVActlEng_D_Qf 1;
BA_ "U_CD542_MY2021_Tx" SG_ 514 VehVActlEng_D_Qf 1;
BA_ "U_U55X_MY2022_Tx" SG_ 514 VehVActlEng_D_Qf 1;
BA_ "U_CD764_MY2022_Tx" SG_ 514 VehVActlEng_D_Qf 1;
BA_ "U_CDX706_MY2023_Tx" SG_ 514 VehVActlEng_D_Qf 1;
BA_ "U_CX727_MY2021_Rx" SG_ 514 Veh_V_ActlEng 1;
BA_ "U_P702_MY2021_Rx" SG_ 514 Veh_V_ActlEng 1;
BA_ "U_T6_MCA_MY2020_Rx" SG_ 514 Veh_V_ActlEng 1;
BA_ "ECGUsedRxSignal" SG_ 514 Veh_V_ActlEng 1;
BA_ "U_CD542_MY2021_Rx" SG_ 514 Veh_V_ActlEng 1;
BA_ "U_U55X_MY2022_Rx" SG_ 514 Veh_V_ActlEng 1;
BA_ "U_CD764_MY2022_Rx" SG_ 514 Veh_V_ActlEng 1;
BA_ "U_CDX706_MY2023_Rx" SG_ 514 Veh_V_ActlEng 1;
BA_ "U_CX727_MY2021_Tx" SG_ 514 Veh_V_ActlEng 1;
BA_ "U_P702_MY2021_Tx" SG_ 514 Veh_V_ActlEng 1;
BA_ "U_T6_MCA_MY2020_Tx" SG_ 514 Veh_V_ActlEng 1;
BA_ "U_CD542_MY2021_Tx" SG_ 514 Veh_V_ActlEng 1;
BA_ "U_U55X_MY2022_Tx" SG_ 514 Veh_V_ActlEng 1;
BA_ "U_CD764_MY2022_Tx" SG_ 514 Veh_V_ActlEng 1;
BA_ "U_CDX706_MY2023_Tx" SG_ 514 Veh_V_ActlEng 1;
BA_ "ContentDependant" SG_ 514 EngAout_Tq_VacLimSpcN 1;
BA_ "U_CX727_MY2021_Rx" SG_ 514 EngAout_Tq_VacLimSpcN 1;
BA_ "U_CD542_MY2021_Rx" SG_ 514 EngAout_Tq_VacLimSpcN 1;
BA_ "U_CDX706_MY2023_Rx" SG_ 514 EngAout_Tq_VacLimSpcN 1;
BA_ "U_CX727_MY2021_Tx" SG_ 514 EngAout_Tq_VacLimSpcN 1;
BA_ "U_CD542_MY2021_Tx" SG_ 514 EngAout_Tq_VacLimSpcN 1;
BA_ "U_CDX706_MY2023_Tx" SG_ 514 EngAout_Tq_VacLimSpcN 1;
BA_ "ContentDependant" SG_ 514 EngCylSync_No_Ctr 1;
BA_ "U_CX727_MY2021_Rx" SG_ 514 EngCylSync_No_Ctr 1;
BA_ "U_CD542_MY2021_Rx" SG_ 514 EngCylSync_No_Ctr 1;
BA_ "U_CDX706_MY2023_Rx" SG_ 514 EngCylSync_No_Ctr 1;
BA_ "U_CX727_MY2021_Tx" SG_ 514 EngCylSync_No_Ctr 1;
BA_ "U_CD542_MY2021_Tx" SG_ 514 EngCylSync_No_Ctr 1;
BA_ "U_CDX706_MY2023_Tx" SG_ 514 EngCylSync_No_Ctr 1;
BA_ "GenSigStartValueInteger" SG_ 514 GearRvrse_D_Actl 7;
BA_ "GenSigStartValue" SG_ 514 GearRvrse_D_Actl 7;
BA_ "U_CX727_MY2021_Rx" SG_ 514 GearRvrse_D_Actl 1;
BA_ "U_P702_MY2021_Rx" SG_ 514 GearRvrse_D_Actl 1;
BA_ "U_T6_MCA_MY2020_Rx" SG_ 514 GearRvrse_D_Actl 1;
BA_ "ECGUsedRxSignal" SG_ 514 GearRvrse_D_Actl 1;
BA_ "U_CD542_MY2021_Rx" SG_ 514 GearRvrse_D_Actl 1;
BA_ "U_U55X_MY2022_Rx" SG_ 514 GearRvrse_D_Actl 1;
BA_ "U_CD764_MY2022_Rx" SG_ 514 GearRvrse_D_Actl 1;
BA_ "U_CDX706_MY2023_Rx" SG_ 514 GearRvrse_D_Actl 1;
BA_ "U_CX727_MY2021_Tx" SG_ 514 GearRvrse_D_Actl 1;
BA_ "U_P702_MY2021_Tx" SG_ 514 GearRvrse_D_Actl 1;
BA_ "U_T6_MCA_MY2020_Tx" SG_ 514 GearRvrse_D_Actl 1;
BA_ "U_CD542_MY2021_Tx" SG_ 514 GearRvrse_D_Actl 1;
BA_ "U_U55X_MY2022_Tx" SG_ 514 GearRvrse_D_Actl 1;
BA_ "U_CD764_MY2022_Tx" SG_ 514 GearRvrse_D_Actl 1;
BA_ "U_CDX706_MY2023_Tx" SG_ 514 GearRvrse_D_Actl 1;
BA_ "U_P702_MY2021_Tx" SG_ 514 StrtrMtrCtlMsgTxt_D2_Rq 1;
BA_ "U_T6_MCA_MY2020_Tx" SG_ 514 StrtrMtrCtlMsgTxt_D2_Rq 1;
BA_ "U_CD542_MY2021_Tx" SG_ 514 StrtrMtrCtlMsgTxt_D2_Rq 1;
BA_ "U_U55X_MY2022_Tx" SG_ 514 StrtrMtrCtlMsgTxt_D2_Rq 1;
BA_ "U_CD764_MY2022_Tx" SG_ 514 StrtrMtrCtlMsgTxt_D2_Rq 1;
BA_ "U_CDX706_MY2023_Tx" SG_ 514 StrtrMtrCtlMsgTxt_D2_Rq 1;
BA_ "ContentDependant" SG_ 512 PrplWhlTotTqRq_No_Cs 1;
BA_ "MetaData" SG_ 512 PrplWhlTotTqRq_No_Cs 1;
BA_ "U_CX727_MY2021_Rx" SG_ 512 PrplWhlTotTqRq_No_Cs 1;
BA_ "U_P702_MY2021_Rx" SG_ 512 PrplWhlTotTqRq_No_Cs 1;
BA_ "U_CD542_MY2021_Rx" SG_ 512 PrplWhlTotTqRq_No_Cs 1;
BA_ "U_U55X_MY2022_Rx" SG_ 512 PrplWhlTotTqRq_No_Cs 1;
BA_ "U_CD764_MY2022_Rx" SG_ 512 PrplWhlTotTqRq_No_Cs 1;
BA_ "U_CDX706_MY2023_Rx" SG_ 512 PrplWhlTotTqRq_No_Cs 1;
BA_ "U_CX727_MY2021_Tx" SG_ 512 PrplWhlTotTqRq_No_Cs 1;
BA_ "U_P702_MY2021_Tx" SG_ 512 PrplWhlTotTqRq_No_Cs 1;
BA_ "U_CD542_MY2021_Tx" SG_ 512 PrplWhlTotTqRq_No_Cs 1;
BA_ "U_CDX706_MY2023_Tx" SG_ 512 PrplWhlTotTqRq_No_Cs 1;
BA_ "ContentDependant" SG_ 512 PrplWhlTotTqRq_No_Cnt 1;
BA_ "MetaData" SG_ 512 PrplWhlTotTqRq_No_Cnt 1;
BA_ "U_CX727_MY2021_Rx" SG_ 512 PrplWhlTotTqRq_No_Cnt 1;
BA_ "U_P702_MY2021_Rx" SG_ 512 PrplWhlTotTqRq_No_Cnt 1;
BA_ "U_CD542_MY2021_Rx" SG_ 512 PrplWhlTotTqRq_No_Cnt 1;
BA_ "U_U55X_MY2022_Rx" SG_ 512 PrplWhlTotTqRq_No_Cnt 1;
BA_ "U_CD764_MY2022_Rx" SG_ 512 PrplWhlTotTqRq_No_Cnt 1;
BA_ "U_CDX706_MY2023_Rx" SG_ 512 PrplWhlTotTqRq_No_Cnt 1;
BA_ "U_CX727_MY2021_Tx" SG_ 512 PrplWhlTotTqRq_No_Cnt 1;
BA_ "U_P702_MY2021_Tx" SG_ 512 PrplWhlTotTqRq_No_Cnt 1;
BA_ "U_CD542_MY2021_Tx" SG_ 512 PrplWhlTotTqRq_No_Cnt 1;
BA_ "U_CDX706_MY2023_Tx" SG_ 512 PrplWhlTotTqRq_No_Cnt 1;
BA_ "ContentDependant" SG_ 512 EngAout_Tq_MxMxN 1;
BA_ "U_CX727_MY2021_Rx" SG_ 512 EngAout_Tq_MxMxN 1;
BA_ "U_CD542_MY2021_Rx" SG_ 512 EngAout_Tq_MxMxN 1;
BA_ "U_CX727_MY2021_Tx" SG_ 512 EngAout_Tq_MxMxN 1;
BA_ "U_CD542_MY2021_Tx" SG_ 512 EngAout_Tq_MxMxN 1;
BA_ "U_CDX706_MY2023_Tx" SG_ 512 EngAout_Tq_MxMxN 1;
BA_ "U_CX727_MY2021_Rx" SG_ 512 PrplWhlTot_Tq_Rq 1;
BA_ "U_P702_MY2021_Rx" SG_ 512 PrplWhlTot_Tq_Rq 1;
BA_ "U_T6_MCA_MY2020_Rx" SG_ 512 PrplWhlTot_Tq_Rq 1;
BA_ "U_CD542_MY2021_Rx" SG_ 512 PrplWhlTot_Tq_Rq 1;
BA_ "U_U55X_MY2022_Rx" SG_ 512 PrplWhlTot_Tq_Rq 1;
BA_ "U_CD764_MY2022_Rx" SG_ 512 PrplWhlTot_Tq_Rq 1;
BA_ "U_CDX706_MY2023_Rx" SG_ 512 PrplWhlTot_Tq_Rq 1;
BA_ "U_CX727_MY2021_Tx" SG_ 512 PrplWhlTot_Tq_Rq 1;
BA_ "U_P702_MY2021_Tx" SG_ 512 PrplWhlTot_Tq_Rq 1;
BA_ "U_T6_MCA_MY2020_Tx" SG_ 512 PrplWhlTot_Tq_Rq 1;
BA_ "U_CD542_MY2021_Tx" SG_ 512 PrplWhlTot_Tq_Rq 1;
BA_ "U_U55X_MY2022_Tx" SG_ 512 PrplWhlTot_Tq_Rq 1;
BA_ "U_CD764_MY2022_Tx" SG_ 512 PrplWhlTot_Tq_Rq 1;
BA_ "U_CDX706_MY2023_Tx" SG_ 512 PrplWhlTot_Tq_Rq 1;
BA_ "U_CX727_MY2021_Rx" SG_ 512 PrplWhlTot_Tq_LimMn 1;
BA_ "U_P702_MY2021_Rx" SG_ 512 PrplWhlTot_Tq_LimMn 1;
BA_ "U_T6_MCA_MY2020_Rx" SG_ 512 PrplWhlTot_Tq_LimMn 1;
BA_ "U_CD542_MY2021_Rx" SG_ 512 PrplWhlTot_Tq_LimMn 1;
BA_ "U_U55X_MY2022_Rx" SG_ 512 PrplWhlTot_Tq_LimMn 1;
BA_ "U_CD764_MY2022_Rx" SG_ 512 PrplWhlTot_Tq_LimMn 1;
BA_ "U_CDX706_MY2023_Rx" SG_ 512 PrplWhlTot_Tq_LimMn 1;
BA_ "U_CX727_MY2021_Tx" SG_ 512 PrplWhlTot_Tq_LimMn 1;
BA_ "U_P702_MY2021_Tx" SG_ 512 PrplWhlTot_Tq_LimMn 1;
BA_ "U_T6_MCA_MY2020_Tx" SG_ 512 PrplWhlTot_Tq_LimMn 1;
BA_ "U_CD542_MY2021_Tx" SG_ 512 PrplWhlTot_Tq_LimMn 1;
BA_ "U_U55X_MY2022_Tx" SG_ 512 PrplWhlTot_Tq_LimMn 1;
BA_ "U_CD764_MY2022_Tx" SG_ 512 PrplWhlTot_Tq_LimMn 1;
BA_ "U_CDX706_MY2023_Tx" SG_ 512 PrplWhlTot_Tq_LimMn 1;
BA_ "U_T6_MCA_MY2020_Rx" SG_ 512 PtDrvMde_D_Stat 1;
BA_ "U_CD542_MY2021_Rx" SG_ 512 PtDrvMde_D_Stat 1;
BA_ "U_U55X_MY2022_Rx" SG_ 512 PtDrvMde_D_Stat 1;
BA_ "U_CD764_MY2022_Rx" SG_ 512 PtDrvMde_D_Stat 1;
BA_ "U_CDX706_MY2023_Rx" SG_ 512 PtDrvMde_D_Stat 1;
BA_ "U_P702_MY2021_Tx" SG_ 512 PtDrvMde_D_Stat 1;
BA_ "U_T6_MCA_MY2020_Tx" SG_ 512 PtDrvMde_D_Stat 1;
BA_ "U_CDX706_MY2023_Tx" SG_ 512 PtDrvMde_D_Stat 1;
BA_ "U_CDX706_MY2023_Tx" SG_ 382 EngIdlShutDown_D2_Type 1;
BA_ "ECGUsedRxSignal" SG_ 382 DcacOut2_Pw2_Dsply 1;
BA_ "U_CD764_MY2022_Rx" SG_ 382 DcacOut2_Pw2_Dsply 1;
BA_ "U_CDX706_MY2023_Rx" SG_ 382 DcacOut2_Pw2_Dsply 1;
BA_ "U_CDX706_MY2023_Tx" SG_ 382 DcacOut2_Pw2_Dsply 1;
BA_ "ECGUsedRxSignal" SG_ 382 DcacOut1_Pw2_Dsply 1;
BA_ "U_CD764_MY2022_Rx" SG_ 382 DcacOut1_Pw2_Dsply 1;
BA_ "U_CDX706_MY2023_Rx" SG_ 382 DcacOut1_Pw2_Dsply 1;
BA_ "U_CDX706_MY2023_Tx" SG_ 382 DcacOut1_Pw2_Dsply 1;
BA_ "GenSigStartValueInteger" SG_ 382 EngMnfldChrg_Te_Actl 126;
BA_ "GenSigStartValue" SG_ 382 EngMnfldChrg_Te_Actl 126;
BA_ "GenSigStartValueInteger" SG_ 382 EngInnrClnt_Te_Actl 56;
BA_ "GenSigStartValue" SG_ 382 EngInnrClnt_Te_Actl 126;
BA_ "ECGUsedRxSignal" SG_ 382 DcacOut_E_Tot 1;
BA_ "U_CDX706_MY2023_Rx" SG_ 382 DcacOut_E_Tot 1;
BA_ "U_CDX706_MY2023_Tx" SG_ 382 DcacOut_E_Tot 1;
BA_ "U_P702_MY2021_Tx" SG_ 381 EngOilLife_T_Actl 1;
BA_ "U_T6_MCA_MY2020_Tx" SG_ 381 EngOilLife_T_Actl 1;
BA_ "U_CDX706_MY2023_Tx" SG_ 381 EngOilLife_T_Actl 1;
BA_ "U_T6_MCA_MY2020_Rx" SG_ 381 EngOilSrvcMsgTxt_D_Rq 1;
BA_ "ECGUsedRxSignal" SG_ 381 EngOilSrvcMsgTxt_D_Rq 1;
BA_ "U_CD542_MY2021_Rx" SG_ 381 EngOilSrvcMsgTxt_D_Rq 1;
BA_ "U_U55X_MY2022_Rx" SG_ 381 EngOilSrvcMsgTxt_D_Rq 1;
BA_ "U_CD764_MY2022_Rx" SG_ 381 EngOilSrvcMsgTxt_D_Rq 1;
BA_ "U_CDX706_MY2023_Rx" SG_ 381 EngOilSrvcMsgTxt_D_Rq 1;
BA_ "U_P702_MY2021_Tx" SG_ 381 EngOilSrvcMsgTxt_D_Rq 1;
BA_ "U_T6_MCA_MY2020_Tx" SG_ 381 EngOilSrvcMsgTxt_D_Rq 1;
BA_ "U_CDX706_MY2023_Tx" SG_ 381 EngOilSrvcMsgTxt_D_Rq 1;
BA_ "U_P702_MY2021_Tx" SG_ 381 DistToNextOilChange 1;
BA_ "U_T6_MCA_MY2020_Tx" SG_ 381 DistToNextOilChange 1;
BA_ "U_CDX706_MY2023_Tx" SG_ 381 DistToNextOilChange 1;
BA_ "U_P702_MY2021_Tx" SG_ 381 RunDryPrevent_B_Stat 1;
BA_ "U_T6_MCA_MY2020_Tx" SG_ 381 RunDryPrevent_B_Stat 1;
BA_ "U_T6_MCA_MY2020_Rx" SG_ 381 WaterInFuel 1;
BA_ "ECGUsedRxSignal" SG_ 381 WaterInFuel 1;
BA_ "U_CD542_MY2021_Rx" SG_ 381 WaterInFuel 1;
BA_ "U_U55X_MY2022_Rx" SG_ 381 WaterInFuel 1;
BA_ "U_CD764_MY2022_Rx" SG_ 381 WaterInFuel 1;
BA_ "U_CDX706_MY2023_Rx" SG_ 381 WaterInFuel 1;
BA_ "U_P702_MY2021_Tx" SG_ 381 WaterInFuel 1;
BA_ "U_T6_MCA_MY2020_Tx" SG_ 381 WaterInFuel 1;
BA_ "U_P702_MY2021_Tx" SG_ 381 GlowIndication 1;
BA_ "U_T6_MCA_MY2020_Tx" SG_ 381 GlowIndication 1;
BA_ "U_CX727_MY2021_Rx" SG_ 380 FuelMaintMde_D_Rq 1;
BA_ "U_CD542_MY2021_Rx" SG_ 380 FuelMaintMde_D_Rq 1;
BA_ "U_CX727_MY2021_Tx" SG_ 380 FuelMaintMde_D_Rq 1;
BA_ "U_CD542_MY2021_Tx" SG_ 380 FuelMaintMde_D_Rq 1;
BA_ "U_CDX706_MY2023_Tx" SG_ 380 FuelMaintMde_D_Rq 1;
BA_ "GenSigStartValueInteger" SG_ 380 GrdAsstAllw_D_DsplyPt 1;
BA_ "GenSigStartValue" SG_ 380 GrdAsstAllw_D_DsplyPt 1;
BA_ "U_CX727_MY2021_Rx" SG_ 380 GrdAsstAllw_D_DsplyPt 1;
BA_ "U_CD542_MY2021_Rx" SG_ 380 GrdAsstAllw_D_DsplyPt 1;
BA_ "U_CDX706_MY2023_Rx" SG_ 380 GrdAsstAllw_D_DsplyPt 1;
BA_ "U_CX727_MY2021_Tx" SG_ 380 GrdAsstAllw_D_DsplyPt 1;
BA_ "U_CD542_MY2021_Tx" SG_ 380 GrdAsstAllw_D_DsplyPt 1;
BA_ "U_CDX706_MY2023_Tx" SG_ 380 GrdAsstAllw_D_DsplyPt 1;
BA_ "WakeupSignal" SG_ 380 EngOilLvlWarn_D_Rq1 1;
BA_ "U_CX727_MY2021_Tx" SG_ 380 EngOilLvlWarn_D_Rq1 1;
BA_ "U_P702_MY2021_Tx" SG_ 380 EngOilLvlWarn_D_Rq1 1;
BA_ "U_T6_MCA_MY2020_Tx" SG_ 380 EngOilLvlWarn_D_Rq1 1;
BA_ "U_CD542_MY2021_Tx" SG_ 380 EngOilLvlWarn_D_Rq1 1;
BA_ "U_U55X_MY2022_Tx" SG_ 380 EngOilLvlWarn_D_Rq1 1;
BA_ "U_CD764_MY2022_Tx" SG_ 380 EngOilLvlWarn_D_Rq1 1;
BA_ "U_CDX706_MY2023_Tx" SG_ 380 EngOilLvlWarn_D_Rq1 1;
BA_ "U_P702_MY2021_Tx" SG_ 380 EngExhBrkOnLamp_B_Rq 1;
BA_ "U_T6_MCA_MY2020_Tx" SG_ 380 EngExhBrkOnLamp_B_Rq 1;
BA_ "U_P702_MY2021_Tx" SG_ 380 EngExhBrkAutoLamp_B_Rq 1;
BA_ "U_T6_MCA_MY2020_Tx" SG_ 380 EngExhBrkAutoLamp_B_Rq 1;
BA_ "U_CX727_MY2021_Rx" SG_ 380 EngAout_N_MxAllw 1;
BA_ "U_P702_MY2021_Rx" SG_ 380 EngAout_N_MxAllw 1;
BA_ "U_CD542_MY2021_Rx" SG_ 380 EngAout_N_MxAllw 1;
BA_ "U_CDX706_MY2023_Rx" SG_ 380 EngAout_N_MxAllw 1;
BA_ "U_CX727_MY2021_Tx" SG_ 380 EngAout_N_MxAllw 1;
BA_ "U_P702_MY2021_Tx" SG_ 380 EngAout_N_MxAllw 1;
BA_ "U_T6_MCA_MY2020_Tx" SG_ 380 EngAout_N_MxAllw 1;
BA_ "U_CD542_MY2021_Tx" SG_ 380 EngAout_N_MxAllw 1;
BA_ "U_CDX706_MY2023_Tx" SG_ 380 EngAout_N_MxAllw 1;
BA_ "U_P702_MY2021_Rx" SG_ 380 EngExhBrkMde_D_Actl 1;
BA_ "U_T6_MCA_MY2020_Rx" SG_ 380 EngExhBrkMde_D_Actl 1;
BA_ "U_P702_MY2021_Tx" SG_ 380 EngExhBrkMde_D_Actl 1;
BA_ "U_T6_MCA_MY2020_Tx" SG_ 380 EngExhBrkMde_D_Actl 1;
BA_ "U_P702_MY2021_Rx" SG_ 380 WhlRearDual_D_Stat 1;
BA_ "MetaData" SG_ 380 EngAoutIdlRqEc_No_Cs 1;
BA_ "MetaData" SG_ 380 EngAoutIdlRqEc_No_Cnt 1;
BA_ "U_CX727_MY2021_Tx" SG_ 377 HvacAirFullOut_B_Rq 1;
BA_ "U_P702_MY2021_Tx" SG_ 377 HvacAirFullOut_B_Rq 1;
BA_ "U_T6_MCA_MY2020_Tx" SG_ 377 HvacAirFullOut_B_Rq 1;
BA_ "U_CD542_MY2021_Tx" SG_ 377 HvacAirFullOut_B_Rq 1;
BA_ "U_U55X_MY2022_Tx" SG_ 377 HvacAirFullOut_B_Rq 1;
BA_ "U_CD764_MY2022_Tx" SG_ 377 HvacAirFullOut_B_Rq 1;
BA_ "U_CDX706_MY2023_Tx" SG_ 377 HvacAirFullOut_B_Rq 1;
BA_ "U_CX727_MY2021_Tx" SG_ 377 TrnManShif_D_IndDrv 1;
BA_ "U_T6_MCA_MY2020_Tx" SG_ 377 TrnManShif_D_IndDrv 1;
BA_ "U_CD542_MY2021_Tx" SG_ 377 TrnManShif_D_IndDrv 1;
BA_ "U_CDX706_MY2023_Tx" SG_ 377 TrnManShif_D_IndDrv 1;
BA_ "U_CX727_MY2021_Rx" SG_ 377 EngAout_Tq_Actl 1;
BA_ "U_CD542_MY2021_Rx" SG_ 377 EngAout_Tq_Actl 1;
BA_ "U_CDX706_MY2023_Rx" SG_ 377 EngAout_Tq_Actl 1;
BA_ "U_CX727_MY2021_Tx" SG_ 377 EngAout_Tq_Actl 1;
BA_ "U_CD542_MY2021_Tx" SG_ 377 EngAout_Tq_Actl 1;
BA_ "U_CDX706_MY2023_Tx" SG_ 377 EngAout_Tq_Actl 1;
BA_ "U_CX727_MY2021_Tx" SG_ 377 TrnManShifGear_D_IndDrv 1;
BA_ "U_T6_MCA_MY2020_Tx" SG_ 377 TrnManShifGear_D_IndDrv 1;
BA_ "U_CD542_MY2021_Tx" SG_ 377 TrnManShifGear_D_IndDrv 1;
BA_ "U_CDX706_MY2023_Tx" SG_ 377 TrnManShifGear_D_IndDrv 1;
BA_ "ContentDependant" SG_ 377 EngFuelCutFull_B_Inhbt 1;
BA_ "U_CX727_MY2021_Rx" SG_ 377 EngFuelCutFull_B_Inhbt 1;
BA_ "U_CD542_MY2021_Rx" SG_ 377 EngFuelCutFull_B_Inhbt 1;
BA_ "U_CDX706_MY2023_Rx" SG_ 377 EngFuelCutFull_B_Inhbt 1;
BA_ "U_CX727_MY2021_Tx" SG_ 377 EngFuelCutFull_B_Inhbt 1;
BA_ "U_CD542_MY2021_Tx" SG_ 377 EngFuelCutFull_B_Inhbt 1;
BA_ "U_CDX706_MY2023_Tx" SG_ 377 EngFuelCutFull_B_Inhbt 1;
BA_ "ContentDependant" SG_ 377 FuelFlw_Vl_Dsply 1;
BA_ "U_CX727_MY2021_Rx" SG_ 377 FuelFlw_Vl_Dsply 1;
BA_ "U_T6_MCA_MY2020_Rx" SG_ 377 FuelFlw_Vl_Dsply 1;
BA_ "ECGUsedRxSignal" SG_ 377 FuelFlw_Vl_Dsply 1;
BA_ "U_CD542_MY2021_Rx" SG_ 377 FuelFlw_Vl_Dsply 1;
BA_ "U_U55X_MY2022_Rx" SG_ 377 FuelFlw_Vl_Dsply 1;
BA_ "U_CD764_MY2022_Rx" SG_ 377 FuelFlw_Vl_Dsply 1;
BA_ "U_CDX706_MY2023_Rx" SG_ 377 FuelFlw_Vl_Dsply 1;
BA_ "U_CX727_MY2021_Tx" SG_ 377 FuelFlw_Vl_Dsply 1;
BA_ "U_P702_MY2021_Tx" SG_ 377 FuelFlw_Vl_Dsply 1;
BA_ "U_T6_MCA_MY2020_Tx" SG_ 377 FuelFlw_Vl_Dsply 1;
BA_ "U_CD542_MY2021_Tx" SG_ 377 FuelFlw_Vl_Dsply 1;
BA_ "U_U55X_MY2022_Tx" SG_ 377 FuelFlw_Vl_Dsply 1;
BA_ "U_CD764_MY2022_Tx" SG_ 377 FuelFlw_Vl_Dsply 1;
BA_ "U_CDX706_MY2023_Tx" SG_ 377 FuelFlw_Vl_Dsply 1;
BA_ "ContentDependant" SG_ 377 FuelFillInlet_B_Dsply 1;
BA_ "U_P702_MY2021_Tx" SG_ 377 FuelFillInlet_B_Dsply 1;
BA_ "U_T6_MCA_MY2020_Tx" SG_ 377 FuelFillInlet_B_Dsply 1;
BA_ "U_CD542_MY2021_Tx" SG_ 377 FuelFillInlet_B_Dsply 1;
BA_ "U_U55X_MY2022_Tx" SG_ 377 FuelFillInlet_B_Dsply 1;
BA_ "U_CD764_MY2022_Tx" SG_ 377 FuelFillInlet_B_Dsply 1;
BA_ "U_CDX706_MY2023_Tx" SG_ 377 FuelFillInlet_B_Dsply 1;
BA_ "U_T6_MCA_MY2020_Rx" SG_ 377 EngSrvcRqd_B_Rq 1;
BA_ "ECGUsedRxSignal" SG_ 377 EngSrvcRqd_B_Rq 1;
BA_ "U_CD542_MY2021_Rx" SG_ 377 EngSrvcRqd_B_Rq 1;
BA_ "U_U55X_MY2022_Rx" SG_ 377 EngSrvcRqd_B_Rq 1;
BA_ "U_CD764_MY2022_Rx" SG_ 377 EngSrvcRqd_B_Rq 1;
BA_ "U_CDX706_MY2023_Rx" SG_ 377 EngSrvcRqd_B_Rq 1;
BA_ "U_CX727_MY2021_Tx" SG_ 377 EngSrvcRqd_B_Rq 1;
BA_ "U_P702_MY2021_Tx" SG_ 377 EngSrvcRqd_B_Rq 1;
BA_ "U_T6_MCA_MY2020_Tx" SG_ 377 EngSrvcRqd_B_Rq 1;
BA_ "U_CD542_MY2021_Tx" SG_ 377 EngSrvcRqd_B_Rq 1;
BA_ "U_U55X_MY2022_Tx" SG_ 377 EngSrvcRqd_B_Rq 1;
BA_ "U_CD764_MY2022_Tx" SG_ 377 EngSrvcRqd_B_Rq 1;
BA_ "U_CDX706_MY2023_Tx" SG_ 377 EngSrvcRqd_B_Rq 1;
BA_ "ContentDependant" SG_ 377 OdoCount 1;
BA_ "U_CX727_MY2021_Tx" SG_ 377 OdoCount 1;
BA_ "U_P702_MY2021_Tx" SG_ 377 OdoCount 1;
BA_ "U_T6_MCA_MY2020_Tx" SG_ 377 OdoCount 1;
BA_ "U_CD542_MY2021_Tx" SG_ 377 OdoCount 1;
BA_ "U_U55X_MY2022_Tx" SG_ 377 OdoCount 1;
BA_ "U_CD764_MY2022_Tx" SG_ 377 OdoCount 1;
BA_ "U_CDX706_MY2023_Tx" SG_ 377 OdoCount 1;
BA_ "ContentDependant" SG_ 377 EngOilLife_Pc_Actl 1;
BA_ "U_T6_MCA_MY2020_Rx" SG_ 377 EngOilLife_Pc_Actl 1;
BA_ "ECGUsedRxSignal" SG_ 377 EngOilLife_Pc_Actl 1;
BA_ "U_CD542_MY2021_Rx" SG_ 377 EngOilLife_Pc_Actl 1;
BA_ "U_U55X_MY2022_Rx" SG_ 377 EngOilLife_Pc_Actl 1;
BA_ "U_CD764_MY2022_Rx" SG_ 377 EngOilLife_Pc_Actl 1;
BA_ "U_CDX706_MY2023_Rx" SG_ 377 EngOilLife_Pc_Actl 1;
BA_ "U_CX727_MY2021_Tx" SG_ 377 EngOilLife_Pc_Actl 1;
BA_ "U_P702_MY2021_Tx" SG_ 377 EngOilLife_Pc_Actl 1;
BA_ "U_T6_MCA_MY2020_Tx" SG_ 377 EngOilLife_Pc_Actl 1;
BA_ "U_CD542_MY2021_Tx" SG_ 377 EngOilLife_Pc_Actl 1;
BA_ "U_U55X_MY2022_Tx" SG_ 377 EngOilLife_Pc_Actl 1;
BA_ "U_CD764_MY2022_Tx" SG_ 377 EngOilLife_Pc_Actl 1;
BA_ "U_CDX706_MY2023_Tx" SG_ 377 EngOilLife_Pc_Actl 1;
BA_ "ContentDependant" SG_ 377 TrnKickDown_B_RqDrv 1;
BA_ "U_T6_MCA_MY2020_Tx" SG_ 377 TrnKickDown_B_RqDrv 1;
BA_ "U_T6_MCA_MY2020_Rx" SG_ 377 FuelFilterLamp_B_Dsply 1;
BA_ "ECGUsedRxSignal" SG_ 377 FuelFilterLamp_B_Dsply 1;
BA_ "U_CD542_MY2021_Rx" SG_ 377 FuelFilterLamp_B_Dsply 1;
BA_ "U_U55X_MY2022_Rx" SG_ 377 FuelFilterLamp_B_Dsply 1;
BA_ "U_CD764_MY2022_Rx" SG_ 377 FuelFilterLamp_B_Dsply 1;
BA_ "U_CDX706_MY2023_Rx" SG_ 377 FuelFilterLamp_B_Dsply 1;
BA_ "U_P702_MY2021_Tx" SG_ 377 FuelFilterLamp_B_Dsply 1;
BA_ "U_T6_MCA_MY2020_Tx" SG_ 377 FuelFilterLamp_B_Dsply 1;
BA_ "ContentDependant" SG_ 377 AirCondRec_B_Rq 1;
BA_ "U_CX727_MY2021_Tx" SG_ 377 AirCondRec_B_Rq 1;
BA_ "U_P702_MY2021_Tx" SG_ 377 AirCondRec_B_Rq 1;
BA_ "U_T6_MCA_MY2020_Tx" SG_ 377 AirCondRec_B_Rq 1;
BA_ "U_CD542_MY2021_Tx" SG_ 377 AirCondRec_B_Rq 1;
BA_ "U_U55X_MY2022_Tx" SG_ 377 AirCondRec_B_Rq 1;
BA_ "U_CD764_MY2022_Tx" SG_ 377 AirCondRec_B_Rq 1;
BA_ "U_CDX706_MY2023_Tx" SG_ 377 AirCondRec_B_Rq 1;
BA_ "ContentDependant" SG_ 377 AirCondClutch_B_Stats 1;
BA_ "U_CX727_MY2021_Tx" SG_ 377 AirCondClutch_B_Stats 1;
BA_ "U_P702_MY2021_Tx" SG_ 377 AirCondClutch_B_Stats 1;
BA_ "U_T6_MCA_MY2020_Tx" SG_ 377 AirCondClutch_B_Stats 1;
BA_ "U_CD542_MY2021_Tx" SG_ 377 AirCondClutch_B_Stats 1;
BA_ "U_U55X_MY2022_Tx" SG_ 377 AirCondClutch_B_Stats 1;
BA_ "U_CD764_MY2022_Tx" SG_ 377 AirCondClutch_B_Stats 1;
BA_ "U_CDX706_MY2023_Tx" SG_ 377 AirCondClutch_B_Stats 1;
BA_ "MetaData" SG_ 377 EngAoutTqActl_D_Qf 1;
BA_ "U_CX727_MY2021_Rx" SG_ 377 EngAoutTqActl_D_Qf 1;
BA_ "U_CD542_MY2021_Rx" SG_ 377 EngAoutTqActl_D_Qf 1;
BA_ "U_CDX706_MY2023_Rx" SG_ 377 EngAoutTqActl_D_Qf 1;
BA_ "U_CX727_MY2021_Tx" SG_ 377 EngAoutTqActl_D_Qf 1;
BA_ "U_CD542_MY2021_Tx" SG_ 377 EngAoutTqActl_D_Qf 1;
BA_ "U_CDX706_MY2023_Tx" SG_ 377 EngAoutTqActl_D_Qf 1;
BA_ "U_CX727_MY2021_Tx" SG_ 376 GasPrtc_D_RqDsply 1;
BA_ "U_P702_MY2021_Tx" SG_ 376 GasPrtc_D_RqDsply 1;
BA_ "U_T6_MCA_MY2020_Tx" SG_ 376 GasPrtc_D_RqDsply 1;
BA_ "U_CD542_MY2021_Tx" SG_ 376 GasPrtc_D_RqDsply 1;
BA_ "U_U55X_MY2022_Tx" SG_ 376 GasPrtc_D_RqDsply 1;
BA_ "U_CD764_MY2022_Tx" SG_ 376 GasPrtc_D_RqDsply 1;
BA_ "U_CDX706_MY2023_Tx" SG_ 376 GasPrtc_D_RqDsply 1;
BA_ "U_T6_MCA_MY2020_Rx" SG_ 376 LnchCtlSys_D_Stat 1;
BA_ "U_CD542_MY2021_Rx" SG_ 376 LnchCtlSys_D_Stat 1;
BA_ "ContentDependant" SG_ 376 EngAout_Aa_Actl 1;
BA_ "U_CX727_MY2021_Rx" SG_ 376 EngAout_Aa_Actl 1;
BA_ "U_P702_MY2021_Rx" SG_ 376 EngAout_Aa_Actl 1;
BA_ "U_T6_MCA_MY2020_Rx" SG_ 376 EngAout_Aa_Actl 1;
BA_ "U_CD542_MY2021_Rx" SG_ 376 EngAout_Aa_Actl 1;
BA_ "U_U55X_MY2022_Rx" SG_ 376 EngAout_Aa_Actl 1;
BA_ "U_CD764_MY2022_Rx" SG_ 376 EngAout_Aa_Actl 1;
BA_ "U_CDX706_MY2023_Rx" SG_ 376 EngAout_Aa_Actl 1;
BA_ "U_CX727_MY2021_Tx" SG_ 376 EngAout_Aa_Actl 1;
BA_ "U_P702_MY2021_Tx" SG_ 376 EngAout_Aa_Actl 1;
BA_ "U_T6_MCA_MY2020_Tx" SG_ 376 EngAout_Aa_Actl 1;
BA_ "U_CD542_MY2021_Tx" SG_ 376 EngAout_Aa_Actl 1;
BA_ "U_U55X_MY2022_Tx" SG_ 376 EngAout_Aa_Actl 1;
BA_ "U_CD764_MY2022_Tx" SG_ 376 EngAout_Aa_Actl 1;
BA_ "U_CDX706_MY2023_Tx" SG_ 376 EngAout_Aa_Actl 1;
BA_ "U_CX727_MY2021_Rx" SG_ 376 DynoMde_B_Cmd 1;
BA_ "U_P702_MY2021_Rx" SG_ 376 DynoMde_B_Cmd 1;
BA_ "U_T6_MCA_MY2020_Rx" SG_ 376 DynoMde_B_Cmd 1;
BA_ "U_CD542_MY2021_Rx" SG_ 376 DynoMde_B_Cmd 1;
BA_ "U_U55X_MY2022_Rx" SG_ 376 DynoMde_B_Cmd 1;
BA_ "U_CD764_MY2022_Rx" SG_ 376 DynoMde_B_Cmd 1;
BA_ "U_CDX706_MY2023_Rx" SG_ 376 DynoMde_B_Cmd 1;
BA_ "U_CX727_MY2021_Tx" SG_ 376 DynoMde_B_Cmd 1;
BA_ "U_P702_MY2021_Tx" SG_ 376 DynoMde_B_Cmd 1;
BA_ "U_T6_MCA_MY2020_Tx" SG_ 376 DynoMde_B_Cmd 1;
BA_ "U_CD542_MY2021_Tx" SG_ 376 DynoMde_B_Cmd 1;
BA_ "U_U55X_MY2022_Tx" SG_ 376 DynoMde_B_Cmd 1;
BA_ "U_CD764_MY2022_Tx" SG_ 376 DynoMde_B_Cmd 1;
BA_ "U_CDX706_MY2023_Tx" SG_ 376 DynoMde_B_Cmd 1;
BA_ "U_CX727_MY2021_Tx" SG_ 376 AslChime_B_Rq 1;
BA_ "U_P702_MY2021_Tx" SG_ 376 AslChime_B_Rq 1;
BA_ "U_T6_MCA_MY2020_Tx" SG_ 376 AslChime_B_Rq 1;
BA_ "U_CD542_MY2021_Tx" SG_ 376 AslChime_B_Rq 1;
BA_ "U_CD764_MY2022_Tx" SG_ 376 AslChime_B_Rq 1;
BA_ "U_CDX706_MY2023_Tx" SG_ 376 AslChime_B_Rq 1;
BA_ "GenSigStartValueInteger" SG_ 376 HvacHtrCore2_Te_Actl 200;
BA_ "U_CX727_MY2021_Rx" SG_ 376 HvacHtrCore2_Te_Actl 1;
BA_ "U_P702_MY2021_Rx" SG_ 376 HvacHtrCore2_Te_Actl 1;
BA_ "U_CD542_MY2021_Rx" SG_ 376 HvacHtrCore2_Te_Actl 1;
BA_ "U_CDX706_MY2023_Rx" SG_ 376 HvacHtrCore2_Te_Actl 1;
BA_ "U_CX727_MY2021_Tx" SG_ 376 HvacHtrCore2_Te_Actl 1;
BA_ "U_P702_MY2021_Tx" SG_ 376 HvacHtrCore2_Te_Actl 1;
BA_ "U_CD542_MY2021_Tx" SG_ 376 HvacHtrCore2_Te_Actl 1;
BA_ "U_CDX706_MY2023_Tx" SG_ 376 HvacHtrCore2_Te_Actl 1;
BA_ "U_CX727_MY2021_Rx" SG_ 376 PtcHtr_D_Cmd 1;
BA_ "U_CD542_MY2021_Rx" SG_ 376 PtcHtr_D_Cmd 1;
BA_ "U_CX727_MY2021_Tx" SG_ 376 PtcHtr_D_Cmd 1;
BA_ "U_CD542_MY2021_Tx" SG_ 376 PtcHtr_D_Cmd 1;
BA_ "U_CDX706_MY2023_Tx" SG_ 376 PtcHtr_D_Cmd 1;
BA_ "U_P702_MY2021_Tx" SG_ 376 EcssLamp_D_RqDsply 1;
BA_ "U_T6_MCA_MY2020_Tx" SG_ 376 EcssLamp_D_RqDsply 1;
BA_ "GenSigStartValueInteger" SG_ 376 AirAmbTe_D_Qf 1;
BA_ "MetaData" SG_ 376 AirAmbTe_D_Qf 1;
BA_ "GenSigStartValue" SG_ 376 AirAmbTe_D_Qf 1;
BA_ "U_CX727_MY2021_Rx" SG_ 376 AirAmbTe_D_Qf 1;
BA_ "U_P702_MY2021_Rx" SG_ 376 AirAmbTe_D_Qf 1;
BA_ "U_T6_MCA_MY2020_Rx" SG_ 376 AirAmbTe_D_Qf 1;
BA_ "U_CD542_MY2021_Rx" SG_ 376 AirAmbTe_D_Qf 1;
BA_ "U_U55X_MY2022_Rx" SG_ 376 AirAmbTe_D_Qf 1;
BA_ "U_CD764_MY2022_Rx" SG_ 376 AirAmbTe_D_Qf 1;
BA_ "U_CDX706_MY2023_Rx" SG_ 376 AirAmbTe_D_Qf 1;
BA_ "U_CX727_MY2021_Tx" SG_ 376 AirAmbTe_D_Qf 1;
BA_ "U_P702_MY2021_Tx" SG_ 376 AirAmbTe_D_Qf 1;
BA_ "U_T6_MCA_MY2020_Tx" SG_ 376 AirAmbTe_D_Qf 1;
BA_ "U_CD542_MY2021_Tx" SG_ 376 AirAmbTe_D_Qf 1;
BA_ "U_U55X_MY2022_Tx" SG_ 376 AirAmbTe_D_Qf 1;
BA_ "U_CD764_MY2022_Tx" SG_ 376 AirAmbTe_D_Qf 1;
BA_ "U_CDX706_MY2023_Tx" SG_ 376 AirAmbTe_D_Qf 1;
BA_ "GenSigStartValueInteger" SG_ 376 AirAmb_Te_ActlFilt 512;
BA_ "U_CX727_MY2021_Rx" SG_ 376 AirAmb_Te_ActlFilt 1;
BA_ "U_P702_MY2021_Rx" SG_ 376 AirAmb_Te_ActlFilt 1;
BA_ "U_T6_MCA_MY2020_Rx" SG_ 376 AirAmb_Te_ActlFilt 1;
BA_ "ECGUsedRxSignal" SG_ 376 AirAmb_Te_ActlFilt 1;
BA_ "U_CD542_MY2021_Rx" SG_ 376 AirAmb_Te_ActlFilt 1;
BA_ "U_U55X_MY2022_Rx" SG_ 376 AirAmb_Te_ActlFilt 1;
BA_ "U_CD764_MY2022_Rx" SG_ 376 AirAmb_Te_ActlFilt 1;
BA_ "U_CDX706_MY2023_Rx" SG_ 376 AirAmb_Te_ActlFilt 1;
BA_ "U_CX727_MY2021_Tx" SG_ 376 AirAmb_Te_ActlFilt 1;
BA_ "U_P702_MY2021_Tx" SG_ 376 AirAmb_Te_ActlFilt 1;
BA_ "U_T6_MCA_MY2020_Tx" SG_ 376 AirAmb_Te_ActlFilt 1;
BA_ "U_CD542_MY2021_Tx" SG_ 376 AirAmb_Te_ActlFilt 1;
BA_ "U_U55X_MY2022_Tx" SG_ 376 AirAmb_Te_ActlFilt 1;
BA_ "U_CD764_MY2022_Tx" SG_ 376 AirAmb_Te_ActlFilt 1;
BA_ "U_CDX706_MY2023_Tx" SG_ 376 AirAmb_Te_ActlFilt 1;
BA_ "U_CX727_MY2021_Rx" SG_ 376 AirAmb_P_Actl 1;
BA_ "U_P702_MY2021_Rx" SG_ 376 AirAmb_P_Actl 1;
BA_ "U_T6_MCA_MY2020_Rx" SG_ 376 AirAmb_P_Actl 1;
BA_ "U_CD542_MY2021_Rx" SG_ 376 AirAmb_P_Actl 1;
BA_ "U_U55X_MY2022_Rx" SG_ 376 AirAmb_P_Actl 1;
BA_ "U_CD764_MY2022_Rx" SG_ 376 AirAmb_P_Actl 1;
BA_ "U_CX727_MY2021_Tx" SG_ 376 AirAmb_P_Actl 1;
BA_ "U_P702_MY2021_Tx" SG_ 376 AirAmb_P_Actl 1;
BA_ "U_T6_MCA_MY2020_Tx" SG_ 376 AirAmb_P_Actl 1;
BA_ "U_CD542_MY2021_Tx" SG_ 376 AirAmb_P_Actl 1;
BA_ "U_U55X_MY2022_Tx" SG_ 376 AirAmb_P_Actl 1;
BA_ "U_CD764_MY2022_Tx" SG_ 376 AirAmb_P_Actl 1;
BA_ "U_CDX706_MY2023_Tx" SG_ 376 AirAmb_P_Actl 1;
BA_ "U_CX727_MY2021_Tx" SG_ 376 AslIconDsply_D_Rq 1;
BA_ "U_P702_MY2021_Tx" SG_ 376 AslIconDsply_D_Rq 1;
BA_ "U_T6_MCA_MY2020_Tx" SG_ 376 AslIconDsply_D_Rq 1;
BA_ "U_CD542_MY2021_Tx" SG_ 376 AslIconDsply_D_Rq 1;
BA_ "U_CD764_MY2022_Tx" SG_ 376 AslIconDsply_D_Rq 1;
BA_ "U_CDX706_MY2023_Tx" SG_ 376 AslIconDsply_D_Rq 1;
BA_ "GenSigStartValueInteger" SG_ 376 AirAmb_Te_Actl 512;
BA_ "U_CX727_MY2021_Rx" SG_ 376 AirAmb_Te_Actl 1;
BA_ "U_P702_MY2021_Rx" SG_ 376 AirAmb_Te_Actl 1;
BA_ "U_T6_MCA_MY2020_Rx" SG_ 376 AirAmb_Te_Actl 1;
BA_ "U_CD542_MY2021_Rx" SG_ 376 AirAmb_Te_Actl 1;
BA_ "U_U55X_MY2022_Rx" SG_ 376 AirAmb_Te_Actl 1;
BA_ "U_CD764_MY2022_Rx" SG_ 376 AirAmb_Te_Actl 1;
BA_ "U_CDX706_MY2023_Rx" SG_ 376 AirAmb_Te_Actl 1;
BA_ "U_CX727_MY2021_Tx" SG_ 376 AirAmb_Te_Actl 1;
BA_ "U_P702_MY2021_Tx" SG_ 376 AirAmb_Te_Actl 1;
BA_ "U_T6_MCA_MY2020_Tx" SG_ 376 AirAmb_Te_Actl 1;
BA_ "U_CD542_MY2021_Tx" SG_ 376 AirAmb_Te_Actl 1;
BA_ "U_U55X_MY2022_Tx" SG_ 376 AirAmb_Te_Actl 1;
BA_ "U_CD764_MY2022_Tx" SG_ 376 AirAmb_Te_Actl 1;
BA_ "U_CDX706_MY2023_Tx" SG_ 376 AirAmb_Te_Actl 1;
BA_ "U_T6_MCA_MY2020_Rx" SG_ 373 DieslPrtc2_D_RqDsply 1;
BA_ "ECGUsedRxSignal" SG_ 373 DieslPrtc2_D_RqDsply 1;
BA_ "U_CD542_MY2021_Rx" SG_ 373 DieslPrtc2_D_RqDsply 1;
BA_ "U_U55X_MY2022_Rx" SG_ 373 DieslPrtc2_D_RqDsply 1;
BA_ "U_CD764_MY2022_Rx" SG_ 373 DieslPrtc2_D_RqDsply 1;
BA_ "U_CDX706_MY2023_Rx" SG_ 373 DieslPrtc2_D_RqDsply 1;
BA_ "U_P702_MY2021_Tx" SG_ 373 DieslPrtc2_D_RqDsply 1;
BA_ "U_T6_MCA_MY2020_Tx" SG_ 373 DieslPrtc2_D_RqDsply 1;
BA_ "U_P702_MY2021_Rx" SG_ 373 DieslPrtcRgen_D_Actl 1;
BA_ "U_T6_MCA_MY2020_Rx" SG_ 373 DieslPrtcRgen_D_Actl 1;
BA_ "U_P702_MY2021_Tx" SG_ 373 DieslPrtcRgen_D_Actl 1;
BA_ "U_T6_MCA_MY2020_Tx" SG_ 373 DieslPrtcRgen_D_Actl 1;
BA_ "ContentDependant" SG_ 373 EngFuelCutFull_B_Allw 1;
BA_ "U_CX727_MY2021_Rx" SG_ 373 EngFuelCutFull_B_Allw 1;
BA_ "U_CD542_MY2021_Rx" SG_ 373 EngFuelCutFull_B_Allw 1;
BA_ "U_CDX706_MY2023_Rx" SG_ 373 EngFuelCutFull_B_Allw 1;
BA_ "U_CX727_MY2021_Tx" SG_ 373 EngFuelCutFull_B_Allw 1;
BA_ "U_CD542_MY2021_Tx" SG_ 373 EngFuelCutFull_B_Allw 1;
BA_ "U_CDX706_MY2023_Tx" SG_ 373 EngFuelCutFull_B_Allw 1;
BA_ "U_P702_MY2021_Tx" SG_ 373 EngTeColdPrtct_D_Stats 1;
BA_ "U_T6_MCA_MY2020_Tx" SG_ 373 EngTeColdPrtct_D_Stats 1;
BA_ "U_T6_MCA_MY2020_Rx" SG_ 373 EngExhOvrTe_B_RqDsply 1;
BA_ "ECGUsedRxSignal" SG_ 373 EngExhOvrTe_B_RqDsply 1;
BA_ "U_CD542_MY2021_Rx" SG_ 373 EngExhOvrTe_B_RqDsply 1;
BA_ "U_U55X_MY2022_Rx" SG_ 373 EngExhOvrTe_B_RqDsply 1;
BA_ "U_CD764_MY2022_Rx" SG_ 373 EngExhOvrTe_B_RqDsply 1;
BA_ "U_CDX706_MY2023_Rx" SG_ 373 EngExhOvrTe_B_RqDsply 1;
BA_ "U_P702_MY2021_Tx" SG_ 373 EngExhOvrTe_B_RqDsply 1;
BA_ "U_T6_MCA_MY2020_Tx" SG_ 373 EngExhOvrTe_B_RqDsply 1;
BA_ "ContentDependant" SG_ 373 EngAout_Tq_MxActlN 1;
BA_ "U_CD542_MY2021_Tx" SG_ 373 EngAout_Tq_MxActlN 1;
BA_ "U_CDX706_MY2023_Tx" SG_ 373 EngAout_Tq_MxActlN 1;
BA_ "GenSigStartValueInteger" SG_ 359 PrplWhlRgenMn_Tq_Actl 4095;
BA_ "U_CX727_MY2021_Rx" SG_ 359 PrplWhlRgenMn_Tq_Actl 1;
BA_ "U_P702_MY2021_Rx" SG_ 359 PrplWhlRgenMn_Tq_Actl 1;
BA_ "U_CD542_MY2021_Rx" SG_ 359 PrplWhlRgenMn_Tq_Actl 1;
BA_ "U_CD764_MY2022_Rx" SG_ 359 PrplWhlRgenMn_Tq_Actl 1;
BA_ "U_CDX706_MY2023_Rx" SG_ 359 PrplWhlRgenMn_Tq_Actl 1;
BA_ "U_CX727_MY2021_Tx" SG_ 359 PrplWhlRgenMn_Tq_Actl 1;
BA_ "U_P702_MY2021_Tx" SG_ 359 PrplWhlRgenMn_Tq_Actl 1;
BA_ "U_CD542_MY2021_Tx" SG_ 359 PrplWhlRgenMn_Tq_Actl 1;
BA_ "U_CDX706_MY2023_Tx" SG_ 359 PrplWhlRgenMn_Tq_Actl 1;
BA_ "U_P702_MY2021_Rx" SG_ 359 ElPw_D_StatStrtStop 1;
BA_ "U_T6_MCA_MY2020_Rx" SG_ 359 ElPw_D_StatStrtStop 1;
BA_ "U_CD542_MY2021_Rx" SG_ 359 ElPw_D_StatStrtStop 1;
BA_ "U_U55X_MY2022_Rx" SG_ 359 ElPw_D_StatStrtStop 1;
BA_ "U_CD764_MY2022_Rx" SG_ 359 ElPw_D_StatStrtStop 1;
BA_ "U_CDX706_MY2023_Rx" SG_ 359 ElPw_D_StatStrtStop 1;
BA_ "U_CX727_MY2021_Tx" SG_ 359 ElPw_D_StatStrtStop 1;
BA_ "U_P702_MY2021_Tx" SG_ 359 ElPw_D_StatStrtStop 1;
BA_ "U_T6_MCA_MY2020_Tx" SG_ 359 ElPw_D_StatStrtStop 1;
BA_ "U_CD542_MY2021_Tx" SG_ 359 ElPw_D_StatStrtStop 1;
BA_ "U_U55X_MY2022_Tx" SG_ 359 ElPw_D_StatStrtStop 1;
BA_ "U_CD764_MY2022_Tx" SG_ 359 ElPw_D_StatStrtStop 1;
BA_ "U_CDX706_MY2023_Tx" SG_ 359 ElPw_D_StatStrtStop 1;
BA_ "ContentDependant" SG_ 359 TrnAin_Tq_Actl 1;
BA_ "U_CX727_MY2021_Rx" SG_ 359 TrnAin_Tq_Actl 1;
BA_ "U_P702_MY2021_Rx" SG_ 359 TrnAin_Tq_Actl 1;
BA_ "U_T6_MCA_MY2020_Rx" SG_ 359 TrnAin_Tq_Actl 1;
BA_ "U_CD542_MY2021_Rx" SG_ 359 TrnAin_Tq_Actl 1;
BA_ "U_U55X_MY2022_Rx" SG_ 359 TrnAin_Tq_Actl 1;
BA_ "U_CD764_MY2022_Rx" SG_ 359 TrnAin_Tq_Actl 1;
BA_ "U_CX727_MY2021_Tx" SG_ 359 TrnAin_Tq_Actl 1;
BA_ "U_P702_MY2021_Tx" SG_ 359 TrnAin_Tq_Actl 1;
BA_ "U_T6_MCA_MY2020_Tx" SG_ 359 TrnAin_Tq_Actl 1;
BA_ "U_CD542_MY2021_Tx" SG_ 359 TrnAin_Tq_Actl 1;
BA_ "U_U55X_MY2022_Tx" SG_ 359 TrnAin_Tq_Actl 1;
BA_ "U_CD764_MY2022_Tx" SG_ 359 TrnAin_Tq_Actl 1;
BA_ "U_CDX706_MY2023_Tx" SG_ 359 TrnAin_Tq_Actl 1;
BA_ "U_CX727_MY2021_Rx" SG_ 359 PrplWhlTot2_Tq_Actl 1;
BA_ "U_P702_MY2021_Rx" SG_ 359 PrplWhlTot2_Tq_Actl 1;
BA_ "U_T6_MCA_MY2020_Rx" SG_ 359 PrplWhlTot2_Tq_Actl 1;
BA_ "ECGUsedRxSignal" SG_ 359 PrplWhlTot2_Tq_Actl 1;
BA_ "U_CD542_MY2021_Rx" SG_ 359 PrplWhlTot2_Tq_Actl 1;
BA_ "U_U55X_MY2022_Rx" SG_ 359 PrplWhlTot2_Tq_Actl 1;
BA_ "U_CD764_MY2022_Rx" SG_ 359 PrplWhlTot2_Tq_Actl 1;
BA_ "U_CDX706_MY2023_Rx" SG_ 359 PrplWhlTot2_Tq_Actl 1;
BA_ "U_CX727_MY2021_Tx" SG_ 359 PrplWhlTot2_Tq_Actl 1;
BA_ "U_P702_MY2021_Tx" SG_ 359 PrplWhlTot2_Tq_Actl 1;
BA_ "U_T6_MCA_MY2020_Tx" SG_ 359 PrplWhlTot2_Tq_Actl 1;
BA_ "U_CD542_MY2021_Tx" SG_ 359 PrplWhlTot2_Tq_Actl 1;
BA_ "U_U55X_MY2022_Tx" SG_ 359 PrplWhlTot2_Tq_Actl 1;
BA_ "U_CD764_MY2022_Tx" SG_ 359 PrplWhlTot2_Tq_Actl 1;
BA_ "U_CDX706_MY2023_Tx" SG_ 359 PrplWhlTot2_Tq_Actl 1;
BA_ "U_CX727_MY2021_Tx" SG_ 359 LscmbbDeny_B_ActlPrpl 1;
BA_ "U_CD542_MY2021_Tx" SG_ 359 LscmbbDeny_B_ActlPrpl 1;
BA_ "U_CDX706_MY2023_Tx" SG_ 359 LscmbbDeny_B_ActlPrpl 1;
BA_ "U_CX727_MY2021_Tx" SG_ 359 LscmbbEngTqMn_B_Actl 1;
BA_ "U_CD542_MY2021_Tx" SG_ 359 LscmbbEngTqMn_B_Actl 1;
BA_ "U_CDX706_MY2023_Tx" SG_ 359 LscmbbEngTqMn_B_Actl 1;
BA_ "U_CX727_MY2021_Rx" SG_ 359 PwPckTq_D_Stat 1;
BA_ "U_P702_MY2021_Rx" SG_ 359 PwPckTq_D_Stat 1;
BA_ "U_T6_MCA_MY2020_Rx" SG_ 359 PwPckTq_D_Stat 1;
BA_ "ECGUsedRxSignal" SG_ 359 PwPckTq_D_Stat 1;
BA_ "U_CD542_MY2021_Rx" SG_ 359 PwPckTq_D_Stat 1;
BA_ "U_U55X_MY2022_Rx" SG_ 359 PwPckTq_D_Stat 1;
BA_ "U_CD764_MY2022_Rx" SG_ 359 PwPckTq_D_Stat 1;
BA_ "U_CDX706_MY2023_Rx" SG_ 359 PwPckTq_D_Stat 1;
BA_ "U_CX727_MY2021_Tx" SG_ 359 PwPckTq_D_Stat 1;
BA_ "U_P702_MY2021_Tx" SG_ 359 PwPckTq_D_Stat 1;
BA_ "U_T6_MCA_MY2020_Tx" SG_ 359 PwPckTq_D_Stat 1;
BA_ "U_CD542_MY2021_Tx" SG_ 359 PwPckTq_D_Stat 1;
BA_ "U_U55X_MY2022_Tx" SG_ 359 PwPckTq_D_Stat 1;
BA_ "U_CD764_MY2022_Tx" SG_ 359 PwPckTq_D_Stat 1;
BA_ "U_CDX706_MY2023_Tx" SG_ 359 PwPckTq_D_Stat 1;
BA_ "U_CX727_MY2021_Rx" SG_ 359 Eng_D_Stat 1;
BA_ "U_P702_MY2021_Rx" SG_ 359 Eng_D_Stat 1;
BA_ "U_T6_MCA_MY2020_Rx" SG_ 359 Eng_D_Stat 1;
BA_ "ECGUsedRxSignal" SG_ 359 Eng_D_Stat 1;
BA_ "U_CD542_MY2021_Rx" SG_ 359 Eng_D_Stat 1;
BA_ "U_U55X_MY2022_Rx" SG_ 359 Eng_D_Stat 1;
BA_ "U_CD764_MY2022_Rx" SG_ 359 Eng_D_Stat 1;
BA_ "U_CDX706_MY2023_Rx" SG_ 359 Eng_D_Stat 1;
BA_ "U_CX727_MY2021_Tx" SG_ 359 Eng_D_Stat 1;
BA_ "U_P702_MY2021_Tx" SG_ 359 Eng_D_Stat 1;
BA_ "U_T6_MCA_MY2020_Tx" SG_ 359 Eng_D_Stat 1;
BA_ "U_CD542_MY2021_Tx" SG_ 359 Eng_D_Stat 1;
BA_ "U_U55X_MY2022_Tx" SG_ 359 Eng_D_Stat 1;
BA_ "U_CD764_MY2022_Tx" SG_ 359 Eng_D_Stat 1;
BA_ "U_CDX706_MY2023_Tx" SG_ 359 Eng_D_Stat 1;
BA_ "GenSigStartValueInteger" SG_ 359 PlgActvArb_B_Actl 1;
BA_ "ContentDependant" SG_ 359 PlgActvArb_B_Actl 1;
BA_ "GenSigStartValue" SG_ 359 PlgActvArb_B_Actl 1;
BA_ "ECGUsedRxSignal" SG_ 359 PlgActvArb_B_Actl 1;
BA_ "U_CD542_MY2021_Rx" SG_ 359 PlgActvArb_B_Actl 1;
BA_ "U_U55X_MY2022_Rx" SG_ 359 PlgActvArb_B_Actl 1;
BA_ "U_CD764_MY2022_Rx" SG_ 359 PlgActvArb_B_Actl 1;
BA_ "U_CDX706_MY2023_Rx" SG_ 359 PlgActvArb_B_Actl 1;
BA_ "U_CX727_MY2021_Tx" SG_ 359 PlgActvArb_B_Actl 1;
BA_ "U_CD542_MY2021_Tx" SG_ 359 PlgActvArb_B_Actl 1;
BA_ "U_CDX706_MY2023_Tx" SG_ 359 PlgActvArb_B_Actl 1;
BA_ "U_CX727_MY2021_Rx" SG_ 359 ElPw_D_Stat 1;
BA_ "U_P702_MY2021_Rx" SG_ 359 ElPw_D_Stat 1;
BA_ "U_T6_MCA_MY2020_Rx" SG_ 359 ElPw_D_Stat 1;
BA_ "U_CD542_MY2021_Rx" SG_ 359 ElPw_D_Stat 1;
BA_ "U_U55X_MY2022_Rx" SG_ 359 ElPw_D_Stat 1;
BA_ "U_CD764_MY2022_Rx" SG_ 359 ElPw_D_Stat 1;
BA_ "U_CDX706_MY2023_Rx" SG_ 359 ElPw_D_Stat 1;
BA_ "U_CX727_MY2021_Tx" SG_ 359 ElPw_D_Stat 1;
BA_ "U_P702_MY2021_Tx" SG_ 359 ElPw_D_Stat 1;
BA_ "U_T6_MCA_MY2020_Tx" SG_ 359 ElPw_D_Stat 1;
BA_ "U_CD542_MY2021_Tx" SG_ 359 ElPw_D_Stat 1;
BA_ "U_U55X_MY2022_Tx" SG_ 359 ElPw_D_Stat 1;
BA_ "U_CD764_MY2022_Tx" SG_ 359 ElPw_D_Stat 1;
BA_ "U_CDX706_MY2023_Tx" SG_ 359 ElPw_D_Stat 1;
BA_ "ContentDependant" SG_ 359 TrnAinTq_D_Qf 1;
BA_ "MetaData" SG_ 359 TrnAinTq_D_Qf 1;
BA_ "U_CX727_MY2021_Rx" SG_ 359 TrnAinTq_D_Qf 1;
BA_ "U_P702_MY2021_Rx" SG_ 359 TrnAinTq_D_Qf 1;
BA_ "U_T6_MCA_MY2020_Rx" SG_ 359 TrnAinTq_D_Qf 1;
BA_ "U_CD542_MY2021_Rx" SG_ 359 TrnAinTq_D_Qf 1;
BA_ "U_U55X_MY2022_Rx" SG_ 359 TrnAinTq_D_Qf 1;
BA_ "U_CD764_MY2022_Rx" SG_ 359 TrnAinTq_D_Qf 1;
BA_ "U_CX727_MY2021_Tx" SG_ 359 TrnAinTq_D_Qf 1;
BA_ "U_P702_MY2021_Tx" SG_ 359 TrnAinTq_D_Qf 1;
BA_ "U_T6_MCA_MY2020_Tx" SG_ 359 TrnAinTq_D_Qf 1;
BA_ "U_CD542_MY2021_Tx" SG_ 359 TrnAinTq_D_Qf 1;
BA_ "U_U55X_MY2022_Tx" SG_ 359 TrnAinTq_D_Qf 1;
BA_ "U_CD764_MY2022_Tx" SG_ 359 TrnAinTq_D_Qf 1;
BA_ "U_CDX706_MY2023_Tx" SG_ 359 TrnAinTq_D_Qf 1;
BA_ "U_P702_MY2021_Tx" SG_ 358 StopStrtStdby_D_Indic 1;
BA_ "U_T6_MCA_MY2020_Tx" SG_ 358 StopStrtStdby_D_Indic 1;
BA_ "U_CD542_MY2021_Tx" SG_ 358 StopStrtStdby_D_Indic 1;
BA_ "U_U55X_MY2022_Tx" SG_ 358 StopStrtStdby_D_Indic 1;
BA_ "U_CD764_MY2022_Tx" SG_ 358 StopStrtStdby_D_Indic 1;
BA_ "U_CDX706_MY2023_Tx" SG_ 358 StopStrtStdby_D_Indic 1;
BA_ "U_P702_MY2021_Tx" SG_ 358 StopStrtIODTxt_D_Rq 1;
BA_ "U_T6_MCA_MY2020_Tx" SG_ 358 StopStrtIODTxt_D_Rq 1;
BA_ "U_CD542_MY2021_Tx" SG_ 358 StopStrtIODTxt_D_Rq 1;
BA_ "U_U55X_MY2022_Tx" SG_ 358 StopStrtIODTxt_D_Rq 1;
BA_ "U_CD764_MY2022_Tx" SG_ 358 StopStrtIODTxt_D_Rq 1;
BA_ "U_CDX706_MY2023_Tx" SG_ 358 StopStrtIODTxt_D_Rq 1;
BA_ "U_P702_MY2021_Tx" SG_ 358 StopStrtDrvMde_D_Indic 1;
BA_ "U_T6_MCA_MY2020_Tx" SG_ 358 StopStrtDrvMde_D_Indic 1;
BA_ "U_CD542_MY2021_Tx" SG_ 358 StopStrtDrvMde_D_Indic 1;
BA_ "U_U55X_MY2022_Tx" SG_ 358 StopStrtDrvMde_D_Indic 1;
BA_ "U_CD764_MY2022_Tx" SG_ 358 StopStrtDrvMde_D_Indic 1;
BA_ "U_CDX706_MY2023_Tx" SG_ 358 StopStrtDrvMde_D_Indic 1;
BA_ "U_P702_MY2021_Tx" SG_ 358 StopStrtMsgTxt_D_Rq 1;
BA_ "U_T6_MCA_MY2020_Tx" SG_ 358 StopStrtMsgTxt_D_Rq 1;
BA_ "U_CD542_MY2021_Tx" SG_ 358 StopStrtMsgTxt_D_Rq 1;
BA_ "U_U55X_MY2022_Tx" SG_ 358 StopStrtMsgTxt_D_Rq 1;
BA_ "U_CD764_MY2022_Tx" SG_ 358 StopStrtMsgTxt_D_Rq 1;
BA_ "U_CDX706_MY2023_Tx" SG_ 358 StopStrtMsgTxt_D_Rq 1;
BA_ "U_CX727_MY2021_Tx" SG_ 358 OdoTripVerify_L_Actl 1;
BA_ "U_P702_MY2021_Tx" SG_ 358 OdoTripVerify_L_Actl 1;
BA_ "U_T6_MCA_MY2020_Tx" SG_ 358 OdoTripVerify_L_Actl 1;
BA_ "U_CD542_MY2021_Tx" SG_ 358 OdoTripVerify_L_Actl 1;
BA_ "U_U55X_MY2022_Tx" SG_ 358 OdoTripVerify_L_Actl 1;
BA_ "U_CD764_MY2022_Tx" SG_ 358 OdoTripVerify_L_Actl 1;
BA_ "U_CDX706_MY2023_Tx" SG_ 358 OdoTripVerify_L_Actl 1;
BA_ "ContentDependant" SG_ 358 HiElPwInhbt_B_Stat 1;
BA_ "U_P702_MY2021_Tx" SG_ 358 HiElPwInhbt_B_Stat 1;
BA_ "U_T6_MCA_MY2020_Tx" SG_ 358 HiElPwInhbt_B_Stat 1;
BA_ "U_CD542_MY2021_Tx" SG_ 358 HiElPwInhbt_B_Stat 1;
BA_ "U_U55X_MY2022_Tx" SG_ 358 HiElPwInhbt_B_Stat 1;
BA_ "U_CD764_MY2022_Tx" SG_ 358 HiElPwInhbt_B_Stat 1;
BA_ "U_CDX706_MY2023_Tx" SG_ 358 HiElPwInhbt_B_Stat 1;
BA_ "GenSigStartValueInteger" SG_ 358 AutoStopPtDelta_I_Est 127;
BA_ "ContentDependant" SG_ 358 AutoStopPtDelta_I_Est 1;
BA_ "U_P702_MY2021_Tx" SG_ 358 AutoStopPtDelta_I_Est 1;
BA_ "U_T6_MCA_MY2020_Tx" SG_ 358 AutoStopPtDelta_I_Est 1;
BA_ "U_CD542_MY2021_Tx" SG_ 358 AutoStopPtDelta_I_Est 1;
BA_ "U_U55X_MY2022_Tx" SG_ 358 AutoStopPtDelta_I_Est 1;
BA_ "U_CD764_MY2022_Tx" SG_ 358 AutoStopPtDelta_I_Est 1;
BA_ "U_CDX706_MY2023_Tx" SG_ 358 AutoStopPtDelta_I_Est 1;
BA_ "GenSigStartValueInteger" SG_ 357 BPedDrvAppl_D_QF 1;
BA_ "MetaData" SG_ 357 BPedDrvAppl_D_QF 1;
BA_ "GenSigStartValue" SG_ 357 BPedDrvAppl_D_QF 1;
BA_ "U_CX727_MY2021_Rx" SG_ 357 BPedDrvAppl_D_QF 1;
BA_ "U_P702_MY2021_Rx" SG_ 357 BPedDrvAppl_D_QF 1;
BA_ "U_T6_MCA_MY2020_Rx" SG_ 357 BPedDrvAppl_D_QF 1;
BA_ "U_CD542_MY2021_Rx" SG_ 357 BPedDrvAppl_D_QF 1;
BA_ "U_U55X_MY2022_Rx" SG_ 357 BPedDrvAppl_D_QF 1;
BA_ "U_CD764_MY2022_Rx" SG_ 357 BPedDrvAppl_D_QF 1;
BA_ "U_CDX706_MY2023_Rx" SG_ 357 BPedDrvAppl_D_QF 1;
BA_ "U_CX727_MY2021_Tx" SG_ 357 BPedDrvAppl_D_QF 1;
BA_ "U_P702_MY2021_Tx" SG_ 357 BPedDrvAppl_D_QF 1;
BA_ "U_T6_MCA_MY2020_Tx" SG_ 357 BPedDrvAppl_D_QF 1;
BA_ "U_CD542_MY2021_Tx" SG_ 357 BPedDrvAppl_D_QF 1;
BA_ "U_U55X_MY2022_Tx" SG_ 357 BPedDrvAppl_D_QF 1;
BA_ "U_CD764_MY2022_Tx" SG_ 357 BPedDrvAppl_D_QF 1;
BA_ "U_CDX706_MY2023_Tx" SG_ 357 BPedDrvAppl_D_QF 1;
BA_ "U_T6_MCA_MY2020_Rx" SG_ 357 CmbbDeny_B_ActlPrpl 1;
BA_ "U_CD542_MY2021_Rx" SG_ 357 CmbbDeny_B_ActlPrpl 1;
BA_ "U_U55X_MY2022_Rx" SG_ 357 CmbbDeny_B_ActlPrpl 1;
BA_ "U_CD764_MY2022_Rx" SG_ 357 CmbbDeny_B_ActlPrpl 1;
BA_ "U_CDX706_MY2023_Rx" SG_ 357 CmbbDeny_B_ActlPrpl 1;
BA_ "U_CX727_MY2021_Tx" SG_ 357 CmbbDeny_B_ActlPrpl 1;
BA_ "U_P702_MY2021_Tx" SG_ 357 CmbbDeny_B_ActlPrpl 1;
BA_ "U_T6_MCA_MY2020_Tx" SG_ 357 CmbbDeny_B_ActlPrpl 1;
BA_ "U_CD542_MY2021_Tx" SG_ 357 CmbbDeny_B_ActlPrpl 1;
BA_ "U_U55X_MY2022_Tx" SG_ 357 CmbbDeny_B_ActlPrpl 1;
BA_ "U_CD764_MY2022_Tx" SG_ 357 CmbbDeny_B_ActlPrpl 1;
BA_ "U_CDX706_MY2023_Tx" SG_ 357 CmbbDeny_B_ActlPrpl 1;
BA_ "MetaData" SG_ 357 BpedDrvAppl_No_Cs 1;
BA_ "U_T6_MCA_MY2020_Rx" SG_ 357 PrplTqMnSat_B_Actl 1;
BA_ "U_CD542_MY2021_Rx" SG_ 357 PrplTqMnSat_B_Actl 1;
BA_ "U_U55X_MY2022_Rx" SG_ 357 PrplTqMnSat_B_Actl 1;
BA_ "U_CD764_MY2022_Rx" SG_ 357 PrplTqMnSat_B_Actl 1;
BA_ "U_CDX706_MY2023_Rx" SG_ 357 PrplTqMnSat_B_Actl 1;
BA_ "U_CX727_MY2021_Tx" SG_ 357 PrplTqMnSat_B_Actl 1;
BA_ "U_P702_MY2021_Tx" SG_ 357 PrplTqMnSat_B_Actl 1;
BA_ "U_T6_MCA_MY2020_Tx" SG_ 357 PrplTqMnSat_B_Actl 1;
BA_ "U_CD542_MY2021_Tx" SG_ 357 PrplTqMnSat_B_Actl 1;
BA_ "U_U55X_MY2022_Tx" SG_ 357 PrplTqMnSat_B_Actl 1;
BA_ "U_CD764_MY2022_Tx" SG_ 357 PrplTqMnSat_B_Actl 1;
BA_ "U_CDX706_MY2023_Tx" SG_ 357 PrplTqMnSat_B_Actl 1;
BA_ "U_CX727_MY2021_Rx" SG_ 357 VehStrtStop_D_Rq 1;
BA_ "U_CD542_MY2021_Rx" SG_ 357 VehStrtStop_D_Rq 1;
BA_ "U_CDX706_MY2023_Rx" SG_ 357 VehStrtStop_D_Rq 1;
BA_ "U_CX727_MY2021_Tx" SG_ 357 VehStrtStop_D_Rq 1;
BA_ "U_CD542_MY2021_Tx" SG_ 357 VehStrtStop_D_Rq 1;
BA_ "U_CDX706_MY2023_Tx" SG_ 357 VehStrtStop_D_Rq 1;
BA_ "MetaData" SG_ 357 BpedDrvAppl_No_Cnt 1;
BA_ "GenSigStartValueInteger" SG_ 357 BpedDrvAppl_D_Actl 1;
BA_ "GenSigStartValue" SG_ 357 BpedDrvAppl_D_Actl 1;
BA_ "U_CX727_MY2021_Rx" SG_ 357 BpedDrvAppl_D_Actl 1;
BA_ "U_P702_MY2021_Rx" SG_ 357 BpedDrvAppl_D_Actl 1;
BA_ "U_T6_MCA_MY2020_Rx" SG_ 357 BpedDrvAppl_D_Actl 1;
BA_ "ECGUsedRxSignal" SG_ 357 BpedDrvAppl_D_Actl 1;
BA_ "U_CD542_MY2021_Rx" SG_ 357 BpedDrvAppl_D_Actl 1;
BA_ "U_U55X_MY2022_Rx" SG_ 357 BpedDrvAppl_D_Actl 1;
BA_ "U_CD764_MY2022_Rx" SG_ 357 BpedDrvAppl_D_Actl 1;
BA_ "U_CDX706_MY2023_Rx" SG_ 357 BpedDrvAppl_D_Actl 1;
BA_ "U_CX727_MY2021_Tx" SG_ 357 BpedDrvAppl_D_Actl 1;
BA_ "U_P702_MY2021_Tx" SG_ 357 BpedDrvAppl_D_Actl 1;
BA_ "U_T6_MCA_MY2020_Tx" SG_ 357 BpedDrvAppl_D_Actl 1;
BA_ "U_CD542_MY2021_Tx" SG_ 357 BpedDrvAppl_D_Actl 1;
BA_ "U_U55X_MY2022_Tx" SG_ 357 BpedDrvAppl_D_Actl 1;
BA_ "U_CD764_MY2022_Tx" SG_ 357 BpedDrvAppl_D_Actl 1;
BA_ "U_CDX706_MY2023_Tx" SG_ 357 BpedDrvAppl_D_Actl 1;
BA_ "U_T6_MCA_MY2020_Rx" SG_ 357 CmbbEngTqMn_B_Actl 1;
BA_ "U_CD542_MY2021_Rx" SG_ 357 CmbbEngTqMn_B_Actl 1;
BA_ "U_U55X_MY2022_Rx" SG_ 357 CmbbEngTqMn_B_Actl 1;
BA_ "U_CD764_MY2022_Rx" SG_ 357 CmbbEngTqMn_B_Actl 1;
BA_ "U_CDX706_MY2023_Rx" SG_ 357 CmbbEngTqMn_B_Actl 1;
BA_ "U_CX727_MY2021_Tx" SG_ 357 CmbbEngTqMn_B_Actl 1;
BA_ "U_P702_MY2021_Tx" SG_ 357 CmbbEngTqMn_B_Actl 1;
BA_ "U_T6_MCA_MY2020_Tx" SG_ 357 CmbbEngTqMn_B_Actl 1;
BA_ "U_CD542_MY2021_Tx" SG_ 357 CmbbEngTqMn_B_Actl 1;
BA_ "U_U55X_MY2022_Tx" SG_ 357 CmbbEngTqMn_B_Actl 1;
BA_ "U_CD764_MY2022_Tx" SG_ 357 CmbbEngTqMn_B_Actl 1;
BA_ "U_CDX706_MY2023_Tx" SG_ 357 CmbbEngTqMn_B_Actl 1;
BA_ "U_T6_MCA_MY2020_Rx" SG_ 357 Veh_V_DsplyCcSet 1;
BA_ "U_CD542_MY2021_Rx" SG_ 357 Veh_V_DsplyCcSet 1;
BA_ "U_U55X_MY2022_Rx" SG_ 357 Veh_V_DsplyCcSet 1;
BA_ "U_CD764_MY2022_Rx" SG_ 357 Veh_V_DsplyCcSet 1;
BA_ "U_CDX706_MY2023_Rx" SG_ 357 Veh_V_DsplyCcSet 1;
BA_ "U_CX727_MY2021_Tx" SG_ 357 Veh_V_DsplyCcSet 1;
BA_ "U_P702_MY2021_Tx" SG_ 357 Veh_V_DsplyCcSet 1;
BA_ "U_T6_MCA_MY2020_Tx" SG_ 357 Veh_V_DsplyCcSet 1;
BA_ "U_CD542_MY2021_Tx" SG_ 357 Veh_V_DsplyCcSet 1;
BA_ "U_U55X_MY2022_Tx" SG_ 357 Veh_V_DsplyCcSet 1;
BA_ "U_CD764_MY2022_Tx" SG_ 357 Veh_V_DsplyCcSet 1;
BA_ "U_CDX706_MY2023_Tx" SG_ 357 Veh_V_DsplyCcSet 1;
BA_ "U_T6_MCA_MY2020_Rx" SG_ 357 AccEngStat_D_Actl 1;
BA_ "U_CD542_MY2021_Rx" SG_ 357 AccEngStat_D_Actl 1;
BA_ "U_U55X_MY2022_Rx" SG_ 357 AccEngStat_D_Actl 1;
BA_ "U_CD764_MY2022_Rx" SG_ 357 AccEngStat_D_Actl 1;
BA_ "U_CDX706_MY2023_Rx" SG_ 357 AccEngStat_D_Actl 1;
BA_ "U_CX727_MY2021_Tx" SG_ 357 AccEngStat_D_Actl 1;
BA_ "U_P702_MY2021_Tx" SG_ 357 AccEngStat_D_Actl 1;
BA_ "U_T6_MCA_MY2020_Tx" SG_ 357 AccEngStat_D_Actl 1;
BA_ "U_CD542_MY2021_Tx" SG_ 357 AccEngStat_D_Actl 1;
BA_ "U_U55X_MY2022_Tx" SG_ 357 AccEngStat_D_Actl 1;
BA_ "U_CD764_MY2022_Tx" SG_ 357 AccEngStat_D_Actl 1;
BA_ "U_CDX706_MY2023_Tx" SG_ 357 AccEngStat_D_Actl 1;
BA_ "U_CX727_MY2021_Rx" SG_ 357 CcMde_D_Actl 1;
BA_ "U_P702_MY2021_Rx" SG_ 357 CcMde_D_Actl 1;
BA_ "U_T6_MCA_MY2020_Rx" SG_ 357 CcMde_D_Actl 1;
BA_ "U_U55X_MY2022_Rx" SG_ 357 CcMde_D_Actl 1;
BA_ "U_CX727_MY2021_Tx" SG_ 357 CcMde_D_Actl 1;
BA_ "U_P702_MY2021_Tx" SG_ 357 CcMde_D_Actl 1;
BA_ "U_T6_MCA_MY2020_Tx" SG_ 357 CcMde_D_Actl 1;
BA_ "U_CD542_MY2021_Tx" SG_ 357 CcMde_D_Actl 1;
BA_ "U_U55X_MY2022_Tx" SG_ 357 CcMde_D_Actl 1;
BA_ "U_CD764_MY2022_Tx" SG_ 357 CcMde_D_Actl 1;
BA_ "U_CDX706_MY2023_Tx" SG_ 357 CcMde_D_Actl 1;
BA_ "U_CX727_MY2021_Rx" SG_ 357 CcStat_D_Actl 1;
BA_ "U_P702_MY2021_Rx" SG_ 357 CcStat_D_Actl 1;
BA_ "U_T6_MCA_MY2020_Rx" SG_ 357 CcStat_D_Actl 1;
BA_ "U_CD542_MY2021_Rx" SG_ 357 CcStat_D_Actl 1;
BA_ "U_U55X_MY2022_Rx" SG_ 357 CcStat_D_Actl 1;
BA_ "U_CD764_MY2022_Rx" SG_ 357 CcStat_D_Actl 1;
BA_ "U_CDX706_MY2023_Rx" SG_ 357 CcStat_D_Actl 1;
BA_ "U_CX727_MY2021_Tx" SG_ 357 CcStat_D_Actl 1;
BA_ "U_P702_MY2021_Tx" SG_ 357 CcStat_D_Actl 1;
BA_ "U_T6_MCA_MY2020_Tx" SG_ 357 CcStat_D_Actl 1;
BA_ "U_CD542_MY2021_Tx" SG_ 357 CcStat_D_Actl 1;
BA_ "U_U55X_MY2022_Tx" SG_ 357 CcStat_D_Actl 1;
BA_ "U_CD764_MY2022_Tx" SG_ 357 CcStat_D_Actl 1;
BA_ "U_CDX706_MY2023_Tx" SG_ 357 CcStat_D_Actl 1;
BA_ "U_CX727_MY2021_Rx" SG_ 357 EngAout_N_MnAllw 1;
BA_ "U_P702_MY2021_Rx" SG_ 357 EngAout_N_MnAllw 1;
BA_ "U_CD542_MY2021_Rx" SG_ 357 EngAout_N_MnAllw 1;
BA_ "U_CDX706_MY2023_Rx" SG_ 357 EngAout_N_MnAllw 1;
BA_ "U_CX727_MY2021_Tx" SG_ 357 EngAout_N_MnAllw 1;
BA_ "U_P702_MY2021_Tx" SG_ 357 EngAout_N_MnAllw 1;
BA_ "U_CD542_MY2021_Tx" SG_ 357 EngAout_N_MnAllw 1;
BA_ "U_CDX706_MY2023_Tx" SG_ 357 EngAout_N_MnAllw 1;
BA_ "U_CX727_MY2021_Rx" SG_ 357 CcOvrrdActv_B_Actl 1;
BA_ "U_P702_MY2021_Rx" SG_ 357 CcOvrrdActv_B_Actl 1;
BA_ "U_T6_MCA_MY2020_Rx" SG_ 357 CcOvrrdActv_B_Actl 1;
BA_ "U_CD542_MY2021_Rx" SG_ 357 CcOvrrdActv_B_Actl 1;
BA_ "U_U55X_MY2022_Rx" SG_ 357 CcOvrrdActv_B_Actl 1;
BA_ "U_CD764_MY2022_Rx" SG_ 357 CcOvrrdActv_B_Actl 1;
BA_ "U_CDX706_MY2023_Rx" SG_ 357 CcOvrrdActv_B_Actl 1;
BA_ "U_CX727_MY2021_Tx" SG_ 357 CcOvrrdActv_B_Actl 1;
BA_ "U_P702_MY2021_Tx" SG_ 357 CcOvrrdActv_B_Actl 1;
BA_ "U_T6_MCA_MY2020_Tx" SG_ 357 CcOvrrdActv_B_Actl 1;
BA_ "U_CD542_MY2021_Tx" SG_ 357 CcOvrrdActv_B_Actl 1;
BA_ "U_U55X_MY2022_Tx" SG_ 357 CcOvrrdActv_B_Actl 1;
BA_ "U_CD764_MY2022_Tx" SG_ 357 CcOvrrdActv_B_Actl 1;
BA_ "U_CDX706_MY2023_Tx" SG_ 357 CcOvrrdActv_B_Actl 1;
BA_ "U_CX727_MY2021_Rx" SG_ 357 AccStopMde_D_Rq 1;
BA_ "U_P702_MY2021_Rx" SG_ 357 AccStopMde_D_Rq 1;
BA_ "U_T6_MCA_MY2020_Rx" SG_ 357 AccStopMde_D_Rq 1;
BA_ "U_CD542_MY2021_Rx" SG_ 357 AccStopMde_D_Rq 1;
BA_ "U_U55X_MY2022_Rx" SG_ 357 AccStopMde_D_Rq 1;
BA_ "U_CD764_MY2022_Rx" SG_ 357 AccStopMde_D_Rq 1;
BA_ "U_CDX706_MY2023_Rx" SG_ 357 AccStopMde_D_Rq 1;
BA_ "U_CX727_MY2021_Tx" SG_ 357 AccStopMde_D_Rq 1;
BA_ "U_P702_MY2021_Tx" SG_ 357 AccStopMde_D_Rq 1;
BA_ "U_T6_MCA_MY2020_Tx" SG_ 357 AccStopMde_D_Rq 1;
BA_ "U_CD542_MY2021_Tx" SG_ 357 AccStopMde_D_Rq 1;
BA_ "U_U55X_MY2022_Tx" SG_ 357 AccStopMde_D_Rq 1;
BA_ "U_CD764_MY2022_Tx" SG_ 357 AccStopMde_D_Rq 1;
BA_ "U_CDX706_MY2023_Tx" SG_ 357 AccStopMde_D_Rq 1;
BA_ "ECGUsedRxSignal" SG_ 355 AutoRgenTxt_B_RqDsply 1;
BA_ "U_CD542_MY2021_Rx" SG_ 355 AutoRgenTxt_B_RqDsply 1;
BA_ "U_U55X_MY2022_Rx" SG_ 355 AutoRgenTxt_B_RqDsply 1;
BA_ "U_CD764_MY2022_Rx" SG_ 355 AutoRgenTxt_B_RqDsply 1;
BA_ "U_CDX706_MY2023_Rx" SG_ 355 AutoRgenTxt_B_RqDsply 1;
BA_ "U_P702_MY2021_Tx" SG_ 355 AutoRgenTxt_B_RqDsply 1;
BA_ "U_T6_MCA_MY2020_Tx" SG_ 355 AutoRgenTxt_B_RqDsply 1;
BA_ "U_P702_MY2021_Tx" SG_ 355 AccFllwMdeActv_B_Actl 1;
BA_ "U_T6_MCA_MY2020_Tx" SG_ 355 AccFllwMdeActv_B_Actl 1;
BA_ "U_P702_MY2021_Tx" SG_ 355 EngPtoMde_D_Actl 1;
BA_ "U_T6_MCA_MY2020_Tx" SG_ 355 EngPtoMde_D_Actl 1;
BA_ "ECGUsedRxSignal" SG_ 355 ManRgenTxt_D_RqDsply 1;
BA_ "U_CD542_MY2021_Rx" SG_ 355 ManRgenTxt_D_RqDsply 1;
BA_ "U_U55X_MY2022_Rx" SG_ 355 ManRgenTxt_D_RqDsply 1;
BA_ "U_CD764_MY2022_Rx" SG_ 355 ManRgenTxt_D_RqDsply 1;
BA_ "U_CDX706_MY2023_Rx" SG_ 355 ManRgenTxt_D_RqDsply 1;
BA_ "U_P702_MY2021_Tx" SG_ 355 ManRgenTxt_D_RqDsply 1;
BA_ "U_T6_MCA_MY2020_Tx" SG_ 355 ManRgenTxt_D_RqDsply 1;
BA_ "ECGUsedRxSignal" SG_ 355 ManRgenSoot_Pc_RqDsply 1;
BA_ "U_CD542_MY2021_Rx" SG_ 355 ManRgenSoot_Pc_RqDsply 1;
BA_ "U_U55X_MY2022_Rx" SG_ 355 ManRgenSoot_Pc_RqDsply 1;
BA_ "U_CD764_MY2022_Rx" SG_ 355 ManRgenSoot_Pc_RqDsply 1;
BA_ "U_CDX706_MY2023_Rx" SG_ 355 ManRgenSoot_Pc_RqDsply 1;
BA_ "U_P702_MY2021_Tx" SG_ 355 ManRgenSoot_Pc_RqDsply 1;
BA_ "U_T6_MCA_MY2020_Tx" SG_ 355 ManRgenSoot_Pc_RqDsply 1;
BA_ "U_P702_MY2021_Tx" SG_ 355 DieslMsgTxt_D_Rq 1;
BA_ "U_T6_MCA_MY2020_Tx" SG_ 355 DieslMsgTxt_D_Rq 1;
BA_ "U_T6_MCA_MY2020_Tx" SG_ 342 FuelRange_L2_DsplyEng 1;
BA_ "U_CX727_MY2021_Rx" SG_ 342 HtrLoop_B_Stat 1;
BA_ "U_CD542_MY2021_Rx" SG_ 342 HtrLoop_B_Stat 1;
BA_ "U_CX727_MY2021_Tx" SG_ 342 HtrLoop_B_Stat 1;
BA_ "U_CD542_MY2021_Tx" SG_ 342 HtrLoop_B_Stat 1;
BA_ "U_CDX706_MY2023_Tx" SG_ 342 HtrLoop_B_Stat 1;
BA_ "ContentDependant" SG_ 342 EngOvrhtMitgActv_D_Ind 1;
BA_ "U_CX727_MY2021_Tx" SG_ 342 EngOvrhtMitgActv_D_Ind 1;
BA_ "U_P702_MY2021_Tx" SG_ 342 EngOvrhtMitgActv_D_Ind 1;
BA_ "U_T6_MCA_MY2020_Tx" SG_ 342 EngOvrhtMitgActv_D_Ind 1;
BA_ "U_CD542_MY2021_Tx" SG_ 342 EngOvrhtMitgActv_D_Ind 1;
BA_ "U_U55X_MY2022_Tx" SG_ 342 EngOvrhtMitgActv_D_Ind 1;
BA_ "U_CD764_MY2022_Tx" SG_ 342 EngOvrhtMitgActv_D_Ind 1;
BA_ "U_CDX706_MY2023_Tx" SG_ 342 EngOvrhtMitgActv_D_Ind 1;
BA_ "MetaData" SG_ 342 EngClntTe_D_Qf 1;
BA_ "U_CX727_MY2021_Rx" SG_ 342 EngClntTe_D_Qf 1;
BA_ "U_P702_MY2021_Rx" SG_ 342 EngClntTe_D_Qf 1;
BA_ "U_T6_MCA_MY2020_Rx" SG_ 342 EngClntTe_D_Qf 1;
BA_ "U_CD542_MY2021_Rx" SG_ 342 EngClntTe_D_Qf 1;
BA_ "U_U55X_MY2022_Rx" SG_ 342 EngClntTe_D_Qf 1;
BA_ "U_CDX706_MY2023_Rx" SG_ 342 EngClntTe_D_Qf 1;
BA_ "U_CX727_MY2021_Tx" SG_ 342 EngClntTe_D_Qf 1;
BA_ "U_P702_MY2021_Tx" SG_ 342 EngClntTe_D_Qf 1;
BA_ "U_T6_MCA_MY2020_Tx" SG_ 342 EngClntTe_D_Qf 1;
BA_ "U_CD542_MY2021_Tx" SG_ 342 EngClntTe_D_Qf 1;
BA_ "U_U55X_MY2022_Tx" SG_ 342 EngClntTe_D_Qf 1;
BA_ "U_CD764_MY2022_Tx" SG_ 342 EngClntTe_D_Qf 1;
BA_ "U_CDX706_MY2023_Tx" SG_ 342 EngClntTe_D_Qf 1;
BA_ "ContentDependant" SG_ 342 EngGoutLss_Tq_Est 1;
BA_ "U_CX727_MY2021_Rx" SG_ 342 EngGoutLss_Tq_Est 1;
BA_ "U_P702_MY2021_Rx" SG_ 342 EngGoutLss_Tq_Est 1;
BA_ "U_CD542_MY2021_Rx" SG_ 342 EngGoutLss_Tq_Est 1;
BA_ "U_CDX706_MY2023_Rx" SG_ 342 EngGoutLss_Tq_Est 1;
BA_ "U_CX727_MY2021_Tx" SG_ 342 EngGoutLss_Tq_Est 1;
BA_ "U_P702_MY2021_Tx" SG_ 342 EngGoutLss_Tq_Est 1;
BA_ "U_CD542_MY2021_Tx" SG_ 342 EngGoutLss_Tq_Est 1;
BA_ "U_CDX706_MY2023_Tx" SG_ 342 EngGoutLss_Tq_Est 1;
BA_ "U_T6_MCA_MY2020_Rx" SG_ 342 EngOil_Te_Actl 1;
BA_ "U_P702_MY2021_Tx" SG_ 342 EngOil_Te_Actl 1;
BA_ "U_T6_MCA_MY2020_Tx" SG_ 342 EngOil_Te_Actl 1;
BA_ "U_CX727_MY2021_Rx" SG_ 342 EngClnt_Te_Actl 1;
BA_ "U_P702_MY2021_Rx" SG_ 342 EngClnt_Te_Actl 1;
BA_ "U_T6_MCA_MY2020_Rx" SG_ 342 EngClnt_Te_Actl 1;
BA_ "ECGUsedRxSignal" SG_ 342 EngClnt_Te_Actl 1;
BA_ "U_CD542_MY2021_Rx" SG_ 342 EngClnt_Te_Actl 1;
BA_ "U_U55X_MY2022_Rx" SG_ 342 EngClnt_Te_Actl 1;
BA_ "U_CD764_MY2022_Rx" SG_ 342 EngClnt_Te_Actl 1;
BA_ "U_CDX706_MY2023_Rx" SG_ 342 EngClnt_Te_Actl 1;
BA_ "U_CX727_MY2021_Tx" SG_ 342 EngClnt_Te_Actl 1;
BA_ "U_P702_MY2021_Tx" SG_ 342 EngClnt_Te_Actl 1;
BA_ "U_T6_MCA_MY2020_Tx" SG_ 342 EngClnt_Te_Actl 1;
BA_ "U_CD542_MY2021_Tx" SG_ 342 EngClnt_Te_Actl 1;
BA_ "U_U55X_MY2022_Tx" SG_ 342 EngClnt_Te_Actl 1;
BA_ "U_CD764_MY2022_Tx" SG_ 342 EngClnt_Te_Actl 1;
BA_ "U_CDX706_MY2023_Tx" SG_ 342 EngClnt_Te_Actl 1;
BA_ "U_U55X_MY2022_Rx" SG_ 894 RmtCtlKeySrch_D_Stat 1;
BA_ "U_CDX706_MY2023_Rx" SG_ 894 RmtCtlKeySrch_D_Stat 1;
BA_ "U_U55X_MY2022_Rx" SG_ 894 RmtCtlBody_D_Stat 1;
BA_ "U_CDX706_MY2023_Rx" SG_ 894 RmtCtlBody_D_Stat 1;
BA_ "GenSigStartValueInteger" SG_ 1520 AWD_GWOnBoardTester 255;
BA_ "ContentDependant" SG_ 1520 AWD_GWOnBoardTester 1;
BA_ "GenSigStartValue" SG_ 1520 AWD_GWOnBoardTester 255;
BA_ "U_T6_MCA_MY2020_Tx" SG_ 1520 AWD_GWOnBoardTester 1;
BA_ "GenSigStartValueInteger" SG_ 1520 AWD_GWNMProxy 255;
BA_ "ContentDependant" SG_ 1520 AWD_GWNMProxy 1;
BA_ "GenSigStartValue" SG_ 1520 AWD_GWNMProxy 255;
BA_ "U_T6_MCA_MY2020_Tx" SG_ 1520 AWD_GWNMProxy 1;
BA_ "GenSigStartValueInteger" SG_ 1520 AWD_AutoSarNMReserved4 255;
BA_ "ContentDependant" SG_ 1520 AWD_AutoSarNMReserved4 1;
BA_ "GenSigStartValue" SG_ 1520 AWD_AutoSarNMReserved4 255;
BA_ "U_T6_MCA_MY2020_Tx" SG_ 1520 AWD_AutoSarNMReserved4 1;
BA_ "GenSigStartValueInteger" SG_ 1520 AWD_AutoSarNMReserved3 255;
BA_ "ContentDependant" SG_ 1520 AWD_AutoSarNMReserved3 1;
BA_ "GenSigStartValue" SG_ 1520 AWD_AutoSarNMReserved3 255;
BA_ "U_T6_MCA_MY2020_Tx" SG_ 1520 AWD_AutoSarNMReserved3 1;
BA_ "GenSigStartValueInteger" SG_ 1520 AWD_AutoSarNMReserved2 255;
BA_ "ContentDependant" SG_ 1520 AWD_AutoSarNMReserved2 1;
BA_ "GenSigStartValue" SG_ 1520 AWD_AutoSarNMReserved2 255;
BA_ "U_T6_MCA_MY2020_Tx" SG_ 1520 AWD_AutoSarNMReserved2 1;
BA_ "GenSigStartValueInteger" SG_ 1520 AWD_AutoSarNMReserved1 255;
BA_ "ContentDependant" SG_ 1520 AWD_AutoSarNMReserved1 1;
BA_ "GenSigStartValue" SG_ 1520 AWD_AutoSarNMReserved1 255;
BA_ "U_T6_MCA_MY2020_Tx" SG_ 1520 AWD_AutoSarNMReserved1 1;
BA_ "GenSigStartValueInteger" SG_ 1520 AWD_AutoSarNMNodeId 240;
BA_ "ContentDependant" SG_ 1520 AWD_AutoSarNMNodeId 1;
BA_ "GenSigStartValue" SG_ 1520 AWD_AutoSarNMNodeId 240;
BA_ "U_T6_MCA_MY2020_Tx" SG_ 1520 AWD_AutoSarNMNodeId 1;
BA_ "ContentDependant" SG_ 1520 AWD_AutoSarNMControl 1;
BA_ "U_T6_MCA_MY2020_Tx" SG_ 1520 AWD_AutoSarNMControl 1;
BA_ "U_CDX706_MY2023_Rx" SG_ 1166 DrOpenPrvntRr_D_Stat 1;
BA_ "U_U55X_MY2022_Rx" SG_ 1166 DrHandleInnrRr_B_Stat 1;
BA_ "U_CDX706_MY2023_Rx" SG_ 1166 DrHandleInnrRr_B_Stat 1;
BA_ "WakeupSignal" SG_ 1166 DrSwtchInnrRr_No_Rq 1;
BA_ "U_CDX706_MY2023_Rx" SG_ 1165 DrOpenPrvntRl_D_Stat 1;
BA_ "U_U55X_MY2022_Rx" SG_ 1165 DrHandleInnrRl_B_Stat 1;
BA_ "U_CDX706_MY2023_Rx" SG_ 1165 DrHandleInnrRl_B_Stat 1;
BA_ "WakeupSignal" SG_ 1165 DrSwtchInnrRl_No_Rq 1;
BA_ "U_CDX706_MY2023_Rx" SG_ 1164 DrOpenPrvntFr_D_Stat 1;
BA_ "U_U55X_MY2022_Rx" SG_ 1164 DrHandleInnrFr_B_Stat 1;
BA_ "U_CDX706_MY2023_Rx" SG_ 1164 DrHandleInnrFr_B_Stat 1;
BA_ "WakeupSignal" SG_ 1164 DrSwtchInnrFr_No_Rq 1;
BA_ "U_CDX706_MY2023_Rx" SG_ 1163 DrOpenPrvntFl_D_Stat 1;
BA_ "U_U55X_MY2022_Rx" SG_ 1163 DrHandleInnrFl_B_Stat 1;
BA_ "U_CDX706_MY2023_Rx" SG_ 1163 DrHandleInnrFl_B_Stat 1;
BA_ "WakeupSignal" SG_ 1163 DrSwtchInnrFl_No_Rq 1;
BA_ "U_CX727_MY2021_Rx" SG_ 71 immoTarget1Status 1;
BA_ "U_P702_MY2021_Rx" SG_ 71 immoTarget1Status 1;
BA_ "U_T6_MCA_MY2020_Rx" SG_ 71 immoTarget1Status 1;
BA_ "U_CD542_MY2021_Rx" SG_ 71 immoTarget1Status 1;
BA_ "U_U55X_MY2022_Rx" SG_ 71 immoTarget1Status 1;
BA_ "U_CD764_MY2022_Rx" SG_ 71 immoTarget1Status 1;
BA_ "U_CDX706_MY2023_Rx" SG_ 71 immoTarget1Status 1;
BA_ "U_CX727_MY2021_Tx" SG_ 71 immoTarget1Status 1;
BA_ "U_P702_MY2021_Tx" SG_ 71 immoTarget1Status 1;
BA_ "U_T6_MCA_MY2020_Tx" SG_ 71 immoTarget1Status 1;
BA_ "U_CD542_MY2021_Tx" SG_ 71 immoTarget1Status 1;
BA_ "U_U55X_MY2022_Tx" SG_ 71 immoTarget1Status 1;
BA_ "U_CD764_MY2022_Tx" SG_ 71 immoTarget1Status 1;
BA_ "U_CDX706_MY2023_Tx" SG_ 71 immoTarget1Status 1;
BA_ "U_CX727_MY2021_Rx" SG_ 71 immoTarget1Data 1;
BA_ "U_P702_MY2021_Rx" SG_ 71 immoTarget1Data 1;
BA_ "U_T6_MCA_MY2020_Rx" SG_ 71 immoTarget1Data 1;
BA_ "U_CD542_MY2021_Rx" SG_ 71 immoTarget1Data 1;
BA_ "U_U55X_MY2022_Rx" SG_ 71 immoTarget1Data 1;
BA_ "U_CD764_MY2022_Rx" SG_ 71 immoTarget1Data 1;
BA_ "U_CDX706_MY2023_Rx" SG_ 71 immoTarget1Data 1;
BA_ "U_CX727_MY2021_Tx" SG_ 71 immoTarget1Data 1;
BA_ "U_P702_MY2021_Tx" SG_ 71 immoTarget1Data 1;
BA_ "U_T6_MCA_MY2020_Tx" SG_ 71 immoTarget1Data 1;
BA_ "U_CD542_MY2021_Tx" SG_ 71 immoTarget1Data 1;
BA_ "U_U55X_MY2022_Tx" SG_ 71 immoTarget1Data 1;
BA_ "U_CD764_MY2022_Tx" SG_ 71 immoTarget1Data 1;
BA_ "U_CDX706_MY2023_Tx" SG_ 71 immoTarget1Data 1;
BA_ "U_CX727_MY2021_Rx" SG_ 71 immoTarget1Cmd 1;
BA_ "U_P702_MY2021_Rx" SG_ 71 immoTarget1Cmd 1;
BA_ "U_T6_MCA_MY2020_Rx" SG_ 71 immoTarget1Cmd 1;
BA_ "U_CD542_MY2021_Rx" SG_ 71 immoTarget1Cmd 1;
BA_ "U_U55X_MY2022_Rx" SG_ 71 immoTarget1Cmd 1;
BA_ "U_CD764_MY2022_Rx" SG_ 71 immoTarget1Cmd 1;
BA_ "U_CDX706_MY2023_Rx" SG_ 71 immoTarget1Cmd 1;
BA_ "U_CX727_MY2021_Tx" SG_ 71 immoTarget1Cmd 1;
BA_ "U_P702_MY2021_Tx" SG_ 71 immoTarget1Cmd 1;
BA_ "U_T6_MCA_MY2020_Tx" SG_ 71 immoTarget1Cmd 1;
BA_ "U_CD542_MY2021_Tx" SG_ 71 immoTarget1Cmd 1;
BA_ "U_U55X_MY2022_Tx" SG_ 71 immoTarget1Cmd 1;
BA_ "U_CD764_MY2022_Tx" SG_ 71 immoTarget1Cmd 1;
BA_ "U_CDX706_MY2023_Tx" SG_ 71 immoTarget1Cmd 1;
BA_ "GenSigSendType" SG_ 1229 DrOpenPrvntRight_B_Rq 3;
BA_ "U_CDX706_MY2023_Tx" SG_ 1229 DrOpenPrvntRight_B_Rq 1;
BA_ "GenSigSendType" SG_ 1229 DrOpenPrvntLeft_B_Rq 3;
BA_ "U_CDX706_MY2023_Tx" SG_ 1229 DrOpenPrvntLeft_B_Rq 1;
BA_ "GenSigSendType" SG_ 1229 ExitNotClrRight_B_Stat 3;
BA_ "U_U55X_MY2022_Tx" SG_ 1229 ExitNotClrRight_B_Stat 1;
BA_ "U_CD764_MY2022_Tx" SG_ 1229 ExitNotClrRight_B_Stat 1;
BA_ "U_CDX706_MY2023_Tx" SG_ 1229 ExitNotClrRight_B_Stat 1;
BA_ "GenSigSendType" SG_ 1229 ExitNotClrLeft_B_Stat 3;
BA_ "U_U55X_MY2022_Tx" SG_ 1229 ExitNotClrLeft_B_Stat 1;
BA_ "U_CD764_MY2022_Tx" SG_ 1229 ExitNotClrLeft_B_Stat 1;
BA_ "U_CDX706_MY2023_Tx" SG_ 1229 ExitNotClrLeft_B_Stat 1;
BA_ "GenSigSendType" SG_ 1238 TjaCanclMsgTxt_D_Dsply 3;
BA_ "ECGUsedRxSignal" SG_ 1238 TjaCanclMsgTxt_D_Dsply 1;
BA_ "U_CDX706_MY2023_Rx" SG_ 1238 TjaCanclMsgTxt_D_Dsply 1;
BA_ "U_CDX706_MY2023_Tx" SG_ 1238 TjaCanclMsgTxt_D_Dsply 1;
BA_ "GenSigSendType" SG_ 1238 TsrAslButtnPress_D_Rq 3;
BA_ "GenSigSendType" SG_ 1238 Fba_D_Stat 3;
BA_ "GenSigStartValue" SG_ 1238 Fba_D_Stat 1;
BA_ "GenSigSendType" SG_ 1238 FbaAlrt_D_Dsply 3;
BA_ "GenSigSendType" SG_ 1238 FbaMnu_D_Rq 3;
BA_ "GenSigSendType" SG_ 1238 TjaLaneBiasEnbl_D_Stat 3;
BA_ "U_CDX706_MY2023_Tx" SG_ 1238 TjaLaneBiasEnbl_D_Stat 1;
BA_ "GenSigSendType" SG_ 1238 TjaLcWarn_D_Rq 3;
BA_ "U_CDX706_MY2023_Tx" SG_ 1238 TjaLcWarn_D_Rq 1;
BA_ "GenSigSendType" SG_ 1238 TjaLcMsgTxt_D_Rq 3;
BA_ "U_CDX706_MY2023_Tx" SG_ 1238 TjaLcMsgTxt_D_Rq 1;
BA_ "GenSigSendType" SG_ 1238 TjaLc_D_Stat 3;
BA_ "U_CDX706_MY2023_Tx" SG_ 1238 TjaLc_D_Stat 1;
BA_ "GenSigSendType" SG_ 1238 TjaLcEnbl_D_Stat 3;
BA_ "U_CDX706_MY2023_Tx" SG_ 1238 TjaLcEnbl_D_Stat 1;
BA_ "GenSigSendType" SG_ 1238 AhbcMnu_D_Rq 3;
BA_ "U_CDX706_MY2023_Tx" SG_ 1238 AhbcMnu_D_Rq 1;
BA_ "GenSigSendType" SG_ 1238 GfhbMnu_D_Rq 3;
BA_ "U_CDX706_MY2023_Tx" SG_ 1238 GfhbMnu_D_Rq 1;
BA_ "GenSigSendType" SG_ 1238 TjaLaneBias_D_Stat 3;
BA_ "U_U55X_MY2022_Tx" SG_ 1238 TjaLaneBias_D_Stat 1;
BA_ "U_CDX706_MY2023_Tx" SG_ 1238 TjaLaneBias_D_Stat 1;
BA_ "U_U55X_MY2022_Tx" SG_ 1238 IaccVAdjReas_D_Dsply 1;
BA_ "U_CDX706_MY2023_Tx" SG_ 1238 IaccVAdjReas_D_Dsply 1;
BA_ "GenSigSendType" SG_ 1238 IaccVAdjLim_No_Actl 3;
BA_ "U_U55X_MY2022_Tx" SG_ 1238 IaccVAdjLim_No_Actl 1;
BA_ "U_CDX706_MY2023_Tx" SG_ 1238 IaccVAdjLim_No_Actl 1;
BA_ "GenSigSendType" SG_ 1238 FbaMsg_D_Rq 3;
BA_ "GenSigSendType" SG_ 2610126880 OTAPhysVDMtoGWM_ECG 3;
BA_ "ECGUsedRxSignal" SG_ 2610126880 OTAPhysVDMtoGWM_ECG 1;
BA_ "U_CD542_MY2021_Rx" SG_ 2610126880 OTAPhysVDMtoGWM_ECG 1;
BA_ "U_CDX706_MY2023_Rx" SG_ 2610126880 OTAPhysVDMtoGWM_ECG 1;
BA_ "U_T6_MCA_MY2020_Tx" SG_ 2610126880 OTAPhysVDMtoGWM_ECG 1;
BA_ "GenSigSendType" SG_ 2609938648 OTAPhysGWM_ECGtoVDM 3;
BA_ "U_T6_MCA_MY2020_Rx" SG_ 2609938648 OTAPhysGWM_ECGtoVDM 1;
BA_ "ECGUsedTxSignal" SG_ 2609938648 OTAPhysGWM_ECGtoVDM 1;
BA_ "U_CD542_MY2021_Tx" SG_ 2609938648 OTAPhysGWM_ECGtoVDM 1;
BA_ "U_CDX706_MY2023_Tx" SG_ 2609938648 OTAPhysGWM_ECGtoVDM 1;
BA_ "GenSigSendType" SG_ 2610987224 PARSEDPhysGWM_ECGtoVDM 3;
BA_ "U_T6_MCA_MY2020_Rx" SG_ 2610987224 PARSEDPhysGWM_ECGtoVDM 1;
BA_ "ECGUsedTxSignal" SG_ 2610987224 PARSEDPhysGWM_ECGtoVDM 1;
BA_ "U_CD542_MY2021_Tx" SG_ 2610987224 PARSEDPhysGWM_ECGtoVDM 1;
BA_ "U_CDX706_MY2023_Tx" SG_ 2610987224 PARSEDPhysGWM_ECGtoVDM 1;
BA_ "GenSigSendType" SG_ 2611175456 PARSEDPhysVDMtoGWM_ECG 3;
BA_ "ECGUsedRxSignal" SG_ 2611175456 PARSEDPhysVDMtoGWM_ECG 1;
BA_ "U_CD542_MY2021_Rx" SG_ 2611175456 PARSEDPhysVDMtoGWM_ECG 1;
BA_ "U_CDX706_MY2023_Rx" SG_ 2611175456 PARSEDPhysVDMtoGWM_ECG 1;
BA_ "U_T6_MCA_MY2020_Tx" SG_ 2611175456 PARSEDPhysVDMtoGWM_ECG 1;
BA_ "GenSigSendType" SG_ 2612035800 PARSEDPushFcGWM_ECGtoVDM 3;
BA_ "U_T6_MCA_MY2020_Rx" SG_ 2612035800 PARSEDPushFcGWM_ECGtoVDM 1;
BA_ "ECGUsedTxSignal" SG_ 2612035800 PARSEDPushFcGWM_ECGtoVDM 1;
BA_ "U_CD542_MY2021_Tx" SG_ 2612035800 PARSEDPushFcGWM_ECGtoVDM 1;
BA_ "U_CDX706_MY2023_Tx" SG_ 2612035800 PARSEDPushFcGWM_ECGtoVDM 1;
BA_ "GenSigSendType" SG_ 2612224032 PARSEDPushVDMtoGWM_ECG 3;
BA_ "ECGUsedRxSignal" SG_ 2612224032 PARSEDPushVDMtoGWM_ECG 1;
BA_ "U_CD542_MY2021_Rx" SG_ 2612224032 PARSEDPushVDMtoGWM_ECG 1;
BA_ "U_CDX706_MY2023_Rx" SG_ 2612224032 PARSEDPushVDMtoGWM_ECG 1;
BA_ "U_T6_MCA_MY2020_Tx" SG_ 2612224032 PARSEDPushVDMtoGWM_ECG 1;
BA_ "MetaData" SG_ 895 RmtCtlDStat_No_Cs 1;
BA_ "U_U55X_MY2022_Rx" SG_ 895 RmtCtlDStat_No_Cs 1;
BA_ "U_CDX706_MY2023_Rx" SG_ 895 RmtCtlDStat_No_Cs 1;
BA_ "MetaData" SG_ 895 RmtCtlDStat_No_Cnt 1;
BA_ "U_U55X_MY2022_Rx" SG_ 895 RmtCtlDStat_No_Cnt 1;
BA_ "U_CDX706_MY2023_Rx" SG_ 895 RmtCtlDStat_No_Cnt 1;
BA_ "WakeupSignal" SG_ 895 RmtCtl_D_Stat 1;
BA_ "U_U55X_MY2022_Rx" SG_ 895 RmtCtl_D_Stat 1;
BA_ "U_CDX706_MY2023_Rx" SG_ 895 RmtCtl_D_Stat 1;
BA_ "U_CDX706_MY2023_Rx" SG_ 1092 BattTracCell_U_Mx 1;
BA_ "GenSigStartValueInteger" SG_ 1092 BattTracMnCell_Te_Actl 254;
BA_ "GenSigStartValue" SG_ 1092 BattTracMnCell_Te_Actl 254;
BA_ "GenSigStartValueInteger" SG_ 1092 BattTracMxCell_Te_Actl 254;
BA_ "GenSigStartValue" SG_ 1092 BattTracMxCell_Te_Actl 254;
BA_ "GenSigStartValueInteger" SG_ 1092 BattTracInsltn_R_Actl 255;
BA_ "GenSigStartValue" SG_ 1092 BattTracInsltn_R_Actl 255;
BA_ "U_CDX706_MY2023_Rx" SG_ 1092 BattTracInsltn_R_Actl 1;
BA_ "GenSigStartValue" SG_ 1236 ApaSlotRearX_L_Actl 1048;
BA_ "U_U55X_MY2022_Tx" SG_ 1236 ApaSlotRearX_L_Actl 1;
BA_ "U_CDX706_MY2023_Tx" SG_ 1236 ApaSlotRearX_L_Actl 1;
BA_ "GenSigSendType" SG_ 1236 ApaSlotRight3X_L_Actl 3;
BA_ "GenSigStartValue" SG_ 1236 ApaSlotRight3X_L_Actl 1048;
BA_ "U_U55X_MY2022_Tx" SG_ 1236 ApaSlotRight3X_L_Actl 1;
BA_ "U_CDX706_MY2023_Tx" SG_ 1236 ApaSlotRight3X_L_Actl 1;
BA_ "GenSigSendType" SG_ 1236 ApaSlotRight3_D_Stat 3;
BA_ "U_U55X_MY2022_Tx" SG_ 1236 ApaSlotRight3_D_Stat 1;
BA_ "U_CDX706_MY2023_Tx" SG_ 1236 ApaSlotRight3_D_Stat 1;
BA_ "GenSigSendType" SG_ 1236 ApaSlotRight3_B_Altr 3;
BA_ "U_U55X_MY2022_Tx" SG_ 1236 ApaSlotRight3_B_Altr 1;
BA_ "U_CDX706_MY2023_Tx" SG_ 1236 ApaSlotRight3_B_Altr 1;
BA_ "GenSigSendType" SG_ 1236 ApaSlotRight2X_L_Actl 3;
BA_ "GenSigStartValue" SG_ 1236 ApaSlotRight2X_L_Actl 1048;
BA_ "U_U55X_MY2022_Tx" SG_ 1236 ApaSlotRight2X_L_Actl 1;
BA_ "U_CDX706_MY2023_Tx" SG_ 1236 ApaSlotRight2X_L_Actl 1;
BA_ "GenSigSendType" SG_ 1236 ApaSlotRight2_D_Stat 3;
BA_ "U_U55X_MY2022_Tx" SG_ 1236 ApaSlotRight2_D_Stat 1;
BA_ "U_CDX706_MY2023_Tx" SG_ 1236 ApaSlotRight2_D_Stat 1;
BA_ "GenSigSendType" SG_ 1236 ApaSlotRight2_B_Altr 3;
BA_ "U_U55X_MY2022_Tx" SG_ 1236 ApaSlotRight2_B_Altr 1;
BA_ "U_CDX706_MY2023_Tx" SG_ 1236 ApaSlotRight2_B_Altr 1;
BA_ "GenSigSendType" SG_ 1236 ApaSlotRight1X_L_Actl 3;
BA_ "GenSigStartValue" SG_ 1236 ApaSlotRight1X_L_Actl 1048;
BA_ "U_U55X_MY2022_Tx" SG_ 1236 ApaSlotRight1X_L_Actl 1;
BA_ "U_CDX706_MY2023_Tx" SG_ 1236 ApaSlotRight1X_L_Actl 1;
BA_ "GenSigSendType" SG_ 1236 ApaSlotRight1_D_Stat 3;
BA_ "U_U55X_MY2022_Tx" SG_ 1236 ApaSlotRight1_D_Stat 1;
BA_ "U_CDX706_MY2023_Tx" SG_ 1236 ApaSlotRight1_D_Stat 1;
BA_ "GenSigSendType" SG_ 1236 ApaSlotRight1_B_Altr 3;
BA_ "U_U55X_MY2022_Tx" SG_ 1236 ApaSlotRight1_B_Altr 1;
BA_ "U_CDX706_MY2023_Tx" SG_ 1236 ApaSlotRight1_B_Altr 1;
BA_ "GenSigStartValue" SG_ 1236 ApaSlotRearY_L_Actl 32;
BA_ "U_U55X_MY2022_Tx" SG_ 1236 ApaSlotRearY_L_Actl 1;
BA_ "U_CDX706_MY2023_Tx" SG_ 1236 ApaSlotRearY_L_Actl 1;
BA_ "U_U55X_MY2022_Tx" SG_ 1236 ApaSlotRear_D_Stat 1;
BA_ "U_CDX706_MY2023_Tx" SG_ 1236 ApaSlotRear_D_Stat 1;
BA_ "GenSigSendType" SG_ 1235 ApaSlotFront_D_Stat 3;
BA_ "U_U55X_MY2022_Tx" SG_ 1235 ApaSlotFront_D_Stat 1;
BA_ "U_CDX706_MY2023_Tx" SG_ 1235 ApaSlotFront_D_Stat 1;
BA_ "GenSigStartValue" SG_ 1235 ApaSlotFrontX_L_Actl 1048;
BA_ "U_U55X_MY2022_Tx" SG_ 1235 ApaSlotFrontX_L_Actl 1;
BA_ "U_CDX706_MY2023_Tx" SG_ 1235 ApaSlotFrontX_L_Actl 1;
BA_ "GenSigStartValue" SG_ 1235 ApaSlotFrontY_L_Actl 32;
BA_ "U_U55X_MY2022_Tx" SG_ 1235 ApaSlotFrontY_L_Actl 1;
BA_ "U_CDX706_MY2023_Tx" SG_ 1235 ApaSlotFrontY_L_Actl 1;
BA_ "GenSigSendType" SG_ 1235 ApaSlotLeft3X_L_Actl 3;
BA_ "GenSigStartValue" SG_ 1235 ApaSlotLeft3X_L_Actl 1048;
BA_ "U_U55X_MY2022_Tx" SG_ 1235 ApaSlotLeft3X_L_Actl 1;
BA_ "U_CDX706_MY2023_Tx" SG_ 1235 ApaSlotLeft3X_L_Actl 1;
BA_ "GenSigSendType" SG_ 1235 ApaSlotLeft3_D_Stat 3;
BA_ "U_U55X_MY2022_Tx" SG_ 1235 ApaSlotLeft3_D_Stat 1;
BA_ "U_CDX706_MY2023_Tx" SG_ 1235 ApaSlotLeft3_D_Stat 1;
BA_ "GenSigSendType" SG_ 1235 ApaSlotLeft3_B_Altr 3;
BA_ "U_U55X_MY2022_Tx" SG_ 1235 ApaSlotLeft3_B_Altr 1;
BA_ "U_CDX706_MY2023_Tx" SG_ 1235 ApaSlotLeft3_B_Altr 1;
BA_ "GenSigSendType" SG_ 1235 ApaSlotLeft2X_L_Actl 3;
BA_ "GenSigStartValue" SG_ 1235 ApaSlotLeft2X_L_Actl 1048;
BA_ "U_U55X_MY2022_Tx" SG_ 1235 ApaSlotLeft2X_L_Actl 1;
BA_ "U_CDX706_MY2023_Tx" SG_ 1235 ApaSlotLeft2X_L_Actl 1;
BA_ "GenSigSendType" SG_ 1235 ApaSlotLeft2_D_Stat 3;
BA_ "U_U55X_MY2022_Tx" SG_ 1235 ApaSlotLeft2_D_Stat 1;
BA_ "U_CDX706_MY2023_Tx" SG_ 1235 ApaSlotLeft2_D_Stat 1;
BA_ "GenSigSendType" SG_ 1235 ApaSlotLeft2_B_Altr 3;
BA_ "U_U55X_MY2022_Tx" SG_ 1235 ApaSlotLeft2_B_Altr 1;
BA_ "U_CDX706_MY2023_Tx" SG_ 1235 ApaSlotLeft2_B_Altr 1;
BA_ "GenSigSendType" SG_ 1235 ApaSlotLeft1X_L_Actl 3;
BA_ "GenSigStartValue" SG_ 1235 ApaSlotLeft1X_L_Actl 1048;
BA_ "U_U55X_MY2022_Tx" SG_ 1235 ApaSlotLeft1X_L_Actl 1;
BA_ "U_CDX706_MY2023_Tx" SG_ 1235 ApaSlotLeft1X_L_Actl 1;
BA_ "GenSigSendType" SG_ 1235 ApaSlotLeft1_D_Stat 3;
BA_ "U_U55X_MY2022_Tx" SG_ 1235 ApaSlotLeft1_D_Stat 1;
BA_ "U_CDX706_MY2023_Tx" SG_ 1235 ApaSlotLeft1_D_Stat 1;
BA_ "GenSigSendType" SG_ 1235 ApaSlotLeft1_B_Altr 3;
BA_ "U_U55X_MY2022_Tx" SG_ 1235 ApaSlotLeft1_B_Altr 1;
BA_ "U_CDX706_MY2023_Tx" SG_ 1235 ApaSlotLeft1_B_Altr 1;
BA_ "GenSigSendType" SG_ 1234 RmtCtlSnsBlckg_B_Stat 3;
BA_ "U_U55X_MY2022_Tx" SG_ 1234 RmtCtlSnsBlckg_B_Stat 1;
BA_ "U_CDX706_MY2023_Tx" SG_ 1234 RmtCtlSnsBlckg_B_Stat 1;
BA_ "GenSigSendType" SG_ 1234 RmtCtlConfgSrc_D_Stat 3;
BA_ "GenSigStartValue" SG_ 1234 RmtCtlConfgSrc_D_Stat 1;
BA_ "U_U55X_MY2022_Tx" SG_ 1234 RmtCtlConfgSrc_D_Stat 1;
BA_ "U_CDX706_MY2023_Tx" SG_ 1234 RmtCtlConfgSrc_D_Stat 1;
BA_ "GenSigSendType" SG_ 1234 RmtCtlTrjctry_D_Avail 3;
BA_ "U_U55X_MY2022_Tx" SG_ 1234 RmtCtlTrjctry_D_Avail 1;
BA_ "U_CDX706_MY2023_Tx" SG_ 1234 RmtCtlTrjctry_D_Avail 1;
BA_ "GenSigSendType" SG_ 1234 RmtCtlSns_D_Err 3;
BA_ "U_U55X_MY2022_Tx" SG_ 1234 RmtCtlSns_D_Err 1;
BA_ "U_CDX706_MY2023_Tx" SG_ 1234 RmtCtlSns_D_Err 1;
BA_ "GenSigSendType" SG_ 1234 RmtCtlPathPlan_D_Stat 3;
BA_ "U_U55X_MY2022_Tx" SG_ 1234 RmtCtlPathPlan_D_Stat 1;
BA_ "U_CDX706_MY2023_Tx" SG_ 1234 RmtCtlPathPlan_D_Stat 1;
BA_ "GenSigSendType" SG_ 1234 RmtCtlPathPlan_B_Err 3;
BA_ "U_U55X_MY2022_Tx" SG_ 1234 RmtCtlPathPlan_B_Err 1;
BA_ "U_CDX706_MY2023_Tx" SG_ 1234 RmtCtlPathPlan_B_Err 1;
BA_ "GenSigSendType" SG_ 1234 RmtCtlAdas_D_Stat 3;
BA_ "U_U55X_MY2022_Tx" SG_ 1234 RmtCtlAdas_D_Stat 1;
BA_ "U_CDX706_MY2023_Tx" SG_ 1234 RmtCtlAdas_D_Stat 1;
BA_ "GenSigSendType" SG_ 1234 RmtCtlAdas_B_Err 3;
BA_ "U_U55X_MY2022_Tx" SG_ 1234 RmtCtlAdas_B_Err 1;
BA_ "U_CDX706_MY2023_Tx" SG_ 1234 RmtCtlAdas_B_Err 1;
BA_ "GenSigSendType" SG_ 1233 FreeDrvRear_D_Avail 3;
BA_ "U_U55X_MY2022_Tx" SG_ 1233 FreeDrvRear_D_Avail 1;
BA_ "U_CDX706_MY2023_Tx" SG_ 1233 FreeDrvRear_D_Avail 1;
BA_ "GenSigSendType" SG_ 1233 FreeDrvFwd_D_Avail 3;
BA_ "U_U55X_MY2022_Tx" SG_ 1233 FreeDrvFwd_D_Avail 1;
BA_ "U_CDX706_MY2023_Tx" SG_ 1233 FreeDrvFwd_D_Avail 1;
BA_ "GenSigSendType" SG_ 1233 RmtCtlTrgDist_D_Stat 3;
BA_ "U_U55X_MY2022_Tx" SG_ 1233 RmtCtlTrgDist_D_Stat 1;
BA_ "U_CDX706_MY2023_Tx" SG_ 1233 RmtCtlTrgDist_D_Stat 1;
BA_ "GenSigSendType" SG_ 1233 RmtCtlSnsRrCrnr_D_Stat 3;
BA_ "U_U55X_MY2022_Tx" SG_ 1233 RmtCtlSnsRrCrnr_D_Stat 1;
BA_ "U_CDX706_MY2023_Tx" SG_ 1233 RmtCtlSnsRrCrnr_D_Stat 1;
BA_ "GenSigSendType" SG_ 1233 RmtCtlSnsRlCrnr_D_Stat 3;
BA_ "U_U55X_MY2022_Tx" SG_ 1233 RmtCtlSnsRlCrnr_D_Stat 1;
BA_ "U_CDX706_MY2023_Tx" SG_ 1233 RmtCtlSnsRlCrnr_D_Stat 1;
BA_ "GenSigSendType" SG_ 1233 RmtCtlSnsRear_D_Stat 3;
BA_ "U_U55X_MY2022_Tx" SG_ 1233 RmtCtlSnsRear_D_Stat 1;
BA_ "U_CDX706_MY2023_Tx" SG_ 1233 RmtCtlSnsRear_D_Stat 1;
BA_ "GenSigSendType" SG_ 1233 RmtCtlSnsFront_D_Stat 3;
BA_ "U_U55X_MY2022_Tx" SG_ 1233 RmtCtlSnsFront_D_Stat 1;
BA_ "U_CDX706_MY2023_Tx" SG_ 1233 RmtCtlSnsFront_D_Stat 1;
BA_ "GenSigSendType" SG_ 1233 RmtCtlSnsFrCrnr_D_Stat 3;
BA_ "U_U55X_MY2022_Tx" SG_ 1233 RmtCtlSnsFrCrnr_D_Stat 1;
BA_ "U_CDX706_MY2023_Tx" SG_ 1233 RmtCtlSnsFrCrnr_D_Stat 1;
BA_ "GenSigSendType" SG_ 1233 RmtCtlSnsFlCrnr_D_Stat 3;
BA_ "U_U55X_MY2022_Tx" SG_ 1233 RmtCtlSnsFlCrnr_D_Stat 1;
BA_ "U_CDX706_MY2023_Tx" SG_ 1233 RmtCtlSnsFlCrnr_D_Stat 1;
BA_ "GenSigSendType" SG_ 1233 RmtCtlSideSnsR4_D_Stat 3;
BA_ "U_U55X_MY2022_Tx" SG_ 1233 RmtCtlSideSnsR4_D_Stat 1;
BA_ "U_CDX706_MY2023_Tx" SG_ 1233 RmtCtlSideSnsR4_D_Stat 1;
BA_ "GenSigSendType" SG_ 1233 RmtCtlSideSnsR3_D_Stat 3;
BA_ "U_U55X_MY2022_Tx" SG_ 1233 RmtCtlSideSnsR3_D_Stat 1;
BA_ "U_CDX706_MY2023_Tx" SG_ 1233 RmtCtlSideSnsR3_D_Stat 1;
BA_ "GenSigSendType" SG_ 1233 RmtCtlSideSnsR2_D_Stat 3;
BA_ "U_U55X_MY2022_Tx" SG_ 1233 RmtCtlSideSnsR2_D_Stat 1;
BA_ "U_CDX706_MY2023_Tx" SG_ 1233 RmtCtlSideSnsR2_D_Stat 1;
BA_ "GenSigSendType" SG_ 1233 RmtCtlSideSnsR1_D_Stat 3;
BA_ "U_U55X_MY2022_Tx" SG_ 1233 RmtCtlSideSnsR1_D_Stat 1;
BA_ "U_CDX706_MY2023_Tx" SG_ 1233 RmtCtlSideSnsR1_D_Stat 1;
BA_ "GenSigSendType" SG_ 1233 RmtCtlSideSnsL4_D_Stat 3;
BA_ "U_U55X_MY2022_Tx" SG_ 1233 RmtCtlSideSnsL4_D_Stat 1;
BA_ "U_CDX706_MY2023_Tx" SG_ 1233 RmtCtlSideSnsL4_D_Stat 1;
BA_ "GenSigSendType" SG_ 1233 RmtCtlSideSnsL3_D_Stat 3;
BA_ "U_U55X_MY2022_Tx" SG_ 1233 RmtCtlSideSnsL3_D_Stat 1;
BA_ "U_CDX706_MY2023_Tx" SG_ 1233 RmtCtlSideSnsL3_D_Stat 1;
BA_ "GenSigSendType" SG_ 1233 RmtCtlSideSnsL2_D_Stat 3;
BA_ "U_U55X_MY2022_Tx" SG_ 1233 RmtCtlSideSnsL2_D_Stat 1;
BA_ "U_CDX706_MY2023_Tx" SG_ 1233 RmtCtlSideSnsL2_D_Stat 1;
BA_ "GenSigSendType" SG_ 1233 RmtCtlSideSnsL1_D_Stat 3;
BA_ "U_U55X_MY2022_Tx" SG_ 1233 RmtCtlSideSnsL1_D_Stat 1;
BA_ "U_CDX706_MY2023_Tx" SG_ 1233 RmtCtlSideSnsL1_D_Stat 1;
BA_ "GenSigSendType" SG_ 1233 RmtCtlRightOrnt_D_Avail 3;
BA_ "U_U55X_MY2022_Tx" SG_ 1233 RmtCtlRightOrnt_D_Avail 1;
BA_ "U_CDX706_MY2023_Tx" SG_ 1233 RmtCtlRightOrnt_D_Avail 1;
BA_ "GenSigSendType" SG_ 1233 RmtCtlRight_D_Avail 3;
BA_ "U_U55X_MY2022_Tx" SG_ 1233 RmtCtlRight_D_Avail 1;
BA_ "U_CDX706_MY2023_Tx" SG_ 1233 RmtCtlRight_D_Avail 1;
BA_ "GenSigSendType" SG_ 1233 RmtCtlRear_D_Avail 3;
BA_ "U_U55X_MY2022_Tx" SG_ 1233 RmtCtlRear_D_Avail 1;
BA_ "U_CDX706_MY2023_Tx" SG_ 1233 RmtCtlRear_D_Avail 1;
BA_ "GenSigSendType" SG_ 1233 RmtCtlPrkMde_D_Stat 3;
BA_ "U_U55X_MY2022_Tx" SG_ 1233 RmtCtlPrkMde_D_Stat 1;
BA_ "U_CDX706_MY2023_Tx" SG_ 1233 RmtCtlPrkMde_D_Stat 1;
BA_ "GenSigSendType" SG_ 1233 RmtCtlPrkInSlot_D_Stat 3;
BA_ "U_U55X_MY2022_Tx" SG_ 1233 RmtCtlPrkInSlot_D_Stat 1;
BA_ "U_CDX706_MY2023_Tx" SG_ 1233 RmtCtlPrkInSlot_D_Stat 1;
BA_ "GenSigSendType" SG_ 1233 RmtCtlObstcl_B_Stat 3;
BA_ "U_U55X_MY2022_Tx" SG_ 1233 RmtCtlObstcl_B_Stat 1;
BA_ "U_CDX706_MY2023_Tx" SG_ 1233 RmtCtlObstcl_B_Stat 1;
BA_ "GenSigSendType" SG_ 1233 RmtCtlNxtMoveDir_D_Stat 3;
BA_ "U_U55X_MY2022_Tx" SG_ 1233 RmtCtlNxtMoveDir_D_Stat 1;
BA_ "U_CDX706_MY2023_Tx" SG_ 1233 RmtCtlNxtMoveDir_D_Stat 1;
BA_ "GenSigSendType" SG_ 1233 RmtCtlMoveDir_D_Stat 3;
BA_ "U_U55X_MY2022_Tx" SG_ 1233 RmtCtlMoveDir_D_Stat 1;
BA_ "U_CDX706_MY2023_Tx" SG_ 1233 RmtCtlMoveDir_D_Stat 1;
BA_ "GenSigSendType" SG_ 1233 RmtCtlLeftOrnt_D_Avail 3;
BA_ "U_U55X_MY2022_Tx" SG_ 1233 RmtCtlLeftOrnt_D_Avail 1;
BA_ "U_CDX706_MY2023_Tx" SG_ 1233 RmtCtlLeftOrnt_D_Avail 1;
BA_ "GenSigSendType" SG_ 1233 RmtCtlLeft_D_Avail 3;
BA_ "U_U55X_MY2022_Tx" SG_ 1233 RmtCtlLeft_D_Avail 1;
BA_ "U_CDX706_MY2023_Tx" SG_ 1233 RmtCtlLeft_D_Avail 1;
BA_ "GenSigSendType" SG_ 1233 RmtCtlFront_D_Avail 3;
BA_ "U_U55X_MY2022_Tx" SG_ 1233 RmtCtlFront_D_Avail 1;
BA_ "U_CDX706_MY2023_Tx" SG_ 1233 RmtCtlFront_D_Avail 1;
BA_ "GenSigSendType" SG_ 1237 DasAttentWarn_D_Dsply 3;
BA_ "GenSigSendType" SG_ 1237 ApaSlotRef2Y_L_Actl 3;
BA_ "U_U55X_MY2022_Tx" SG_ 1237 ApaSlotRef2Y_L_Actl 1;
BA_ "U_CDX706_MY2023_Tx" SG_ 1237 ApaSlotRef2Y_L_Actl 1;
BA_ "GenSigSendType" SG_ 1237 ApaSlotRef2X_L_Actl 3;
BA_ "U_U55X_MY2022_Tx" SG_ 1237 ApaSlotRef2X_L_Actl 1;
BA_ "U_CDX706_MY2023_Tx" SG_ 1237 ApaSlotRef2X_L_Actl 1;
BA_ "GenSigSendType" SG_ 1237 ApaSlotRef1Y_L_Actl 3;
BA_ "U_U55X_MY2022_Tx" SG_ 1237 ApaSlotRef1Y_L_Actl 1;
BA_ "U_CDX706_MY2023_Tx" SG_ 1237 ApaSlotRef1Y_L_Actl 1;
BA_ "GenSigSendType" SG_ 1237 ApaSlotRef1X_L_Actl 3;
BA_ "U_U55X_MY2022_Tx" SG_ 1237 ApaSlotRef1X_L_Actl 1;
BA_ "U_CDX706_MY2023_Tx" SG_ 1237 ApaSlotRef1X_L_Actl 1;
BA_ "GenSigStartValue" SG_ 1149 BattTracPerf_Pc_Dsply 254;
BA_ "U_CDX706_MY2023_Rx" SG_ 1149 BattTracPerf_Pc_Dsply 1;
BA_ "GenSigStartValue" SG_ 1149 BattTracPerf_Pc_Actl 254;
BA_ "U_CDX706_MY2023_Rx" SG_ 1149 BattTracPerf_Pc_Actl 1;
BA_ "GenSigStartValueInteger" SG_ 1436 IPMA_GWOnBoardTester 255;
BA_ "ContentDependant" SG_ 1436 IPMA_GWOnBoardTester 1;
BA_ "GenSigStartValue" SG_ 1436 IPMA_GWOnBoardTester 255;
BA_ "U_U55X_MY2022_Tx" SG_ 1436 IPMA_GWOnBoardTester 1;
BA_ "U_CDX706_MY2023_Tx" SG_ 1436 IPMA_GWOnBoardTester 1;
BA_ "GenSigStartValueInteger" SG_ 1436 IPMA_GWNMProxy 255;
BA_ "ContentDependant" SG_ 1436 IPMA_GWNMProxy 1;
BA_ "GenSigStartValue" SG_ 1436 IPMA_GWNMProxy 255;
BA_ "U_U55X_MY2022_Tx" SG_ 1436 IPMA_GWNMProxy 1;
BA_ "U_CDX706_MY2023_Tx" SG_ 1436 IPMA_GWNMProxy 1;
BA_ "GenSigStartValueInteger" SG_ 1436 IPMA_AutoSarNMReserved4 255;
BA_ "ContentDependant" SG_ 1436 IPMA_AutoSarNMReserved4 1;
BA_ "GenSigStartValue" SG_ 1436 IPMA_AutoSarNMReserved4 255;
BA_ "U_U55X_MY2022_Tx" SG_ 1436 IPMA_AutoSarNMReserved4 1;
BA_ "U_CDX706_MY2023_Tx" SG_ 1436 IPMA_AutoSarNMReserved4 1;
BA_ "GenSigStartValueInteger" SG_ 1436 IPMA_AutoSarNMReserved3 255;
BA_ "ContentDependant" SG_ 1436 IPMA_AutoSarNMReserved3 1;
BA_ "GenSigStartValue" SG_ 1436 IPMA_AutoSarNMReserved3 255;
BA_ "U_U55X_MY2022_Tx" SG_ 1436 IPMA_AutoSarNMReserved3 1;
BA_ "U_CDX706_MY2023_Tx" SG_ 1436 IPMA_AutoSarNMReserved3 1;
BA_ "GenSigStartValueInteger" SG_ 1436 IPMA_AutoSarNMReserved2 255;
BA_ "ContentDependant" SG_ 1436 IPMA_AutoSarNMReserved2 1;
BA_ "GenSigStartValue" SG_ 1436 IPMA_AutoSarNMReserved2 255;
BA_ "U_U55X_MY2022_Tx" SG_ 1436 IPMA_AutoSarNMReserved2 1;
BA_ "U_CDX706_MY2023_Tx" SG_ 1436 IPMA_AutoSarNMReserved2 1;
BA_ "GenSigStartValueInteger" SG_ 1436 IPMA_AutoSarNMReserved1 255;
BA_ "ContentDependant" SG_ 1436 IPMA_AutoSarNMReserved1 1;
BA_ "GenSigStartValue" SG_ 1436 IPMA_AutoSarNMReserved1 255;
BA_ "U_U55X_MY2022_Tx" SG_ 1436 IPMA_AutoSarNMReserved1 1;
BA_ "U_CDX706_MY2023_Tx" SG_ 1436 IPMA_AutoSarNMReserved1 1;
BA_ "GenSigStartValueInteger" SG_ 1436 IPMA_AutoSarNMNodeId 145;
BA_ "ContentDependant" SG_ 1436 IPMA_AutoSarNMNodeId 1;
BA_ "GenSigStartValue" SG_ 1436 IPMA_AutoSarNMNodeId 156;
BA_ "U_U55X_MY2022_Tx" SG_ 1436 IPMA_AutoSarNMNodeId 1;
BA_ "U_CDX706_MY2023_Tx" SG_ 1436 IPMA_AutoSarNMNodeId 1;
BA_ "ContentDependant" SG_ 1436 IPMA_AutoSarNMControl 1;
BA_ "U_U55X_MY2022_Tx" SG_ 1436 IPMA_AutoSarNMControl 1;
BA_ "U_CDX706_MY2023_Tx" SG_ 1436 IPMA_AutoSarNMControl 1;
BA_ "GenSigStartValueInteger" SG_ 925 VehElEffTrip_No_Dsply 126;
BA_ "GenSigStartValue" SG_ 925 VehElEffTrip_No_Dsply 126;
BA_ "U_CDX706_MY2023_Tx" SG_ 925 VehElEffTrip_No_Dsply 1;
BA_ "GenSigStartValueInteger" SG_ 925 TripSumDrvE_Pc_Dsply 1022;
BA_ "GenSigStartValue" SG_ 925 TripSumDrvE_Pc_Dsply 1022;
BA_ "ECGUsedRxSignal" SG_ 925 TripSumDrvE_Pc_Dsply 1;
BA_ "U_CD542_MY2021_Rx" SG_ 925 TripSumDrvE_Pc_Dsply 1;
BA_ "U_U55X_MY2022_Rx" SG_ 925 TripSumDrvE_Pc_Dsply 1;
BA_ "U_CDX706_MY2023_Rx" SG_ 925 TripSumDrvE_Pc_Dsply 1;
BA_ "U_CDX706_MY2023_Tx" SG_ 925 TripSumDrvE_Pc_Dsply 1;
BA_ "GenSigStartValueInteger" SG_ 925 TripExtFctrE_Pc_Dsply 1022;
BA_ "GenSigStartValue" SG_ 925 TripExtFctrE_Pc_Dsply 1022;
BA_ "ECGUsedRxSignal" SG_ 925 TripExtFctrE_Pc_Dsply 1;
BA_ "U_CD542_MY2021_Rx" SG_ 925 TripExtFctrE_Pc_Dsply 1;
BA_ "U_U55X_MY2022_Rx" SG_ 925 TripExtFctrE_Pc_Dsply 1;
BA_ "U_CDX706_MY2023_Rx" SG_ 925 TripExtFctrE_Pc_Dsply 1;
BA_ "U_CDX706_MY2023_Tx" SG_ 925 TripExtFctrE_Pc_Dsply 1;
BA_ "GenSigStartValueInteger" SG_ 925 TripClimE_Pc_Dsply 1022;
BA_ "GenSigStartValue" SG_ 925 TripClimE_Pc_Dsply 1022;
BA_ "ECGUsedRxSignal" SG_ 925 TripClimE_Pc_Dsply 1;
BA_ "U_CD542_MY2021_Rx" SG_ 925 TripClimE_Pc_Dsply 1;
BA_ "U_U55X_MY2022_Rx" SG_ 925 TripClimE_Pc_Dsply 1;
BA_ "U_CDX706_MY2023_Rx" SG_ 925 TripClimE_Pc_Dsply 1;
BA_ "U_CDX706_MY2023_Tx" SG_ 925 TripClimE_Pc_Dsply 1;
BA_ "GenSigStartValueInteger" SG_ 925 TripBattULoE_Pc_Dsply 1022;
BA_ "GenSigStartValue" SG_ 925 TripBattULoE_Pc_Dsply 1022;
BA_ "ECGUsedRxSignal" SG_ 925 TripBattULoE_Pc_Dsply 1;
BA_ "U_CD542_MY2021_Rx" SG_ 925 TripBattULoE_Pc_Dsply 1;
BA_ "U_U55X_MY2022_Rx" SG_ 925 TripBattULoE_Pc_Dsply 1;
BA_ "U_CDX706_MY2023_Rx" SG_ 925 TripBattULoE_Pc_Dsply 1;
BA_ "U_CDX706_MY2023_Tx" SG_ 925 TripBattULoE_Pc_Dsply 1;
BA_ "GenSigSendType" SG_ 2611001560 PARSEDPhysGWM_ECGtoCHCM 3;
BA_ "U_T6_MCA_MY2020_Rx" SG_ 2611001560 PARSEDPhysGWM_ECGtoCHCM 1;
BA_ "ECGUsedTxSignal" SG_ 2611001560 PARSEDPhysGWM_ECGtoCHCM 1;
BA_ "U_CD542_MY2021_Tx" SG_ 2611001560 PARSEDPhysGWM_ECGtoCHCM 1;
BA_ "U_U55X_MY2022_Tx" SG_ 2611001560 PARSEDPhysGWM_ECGtoCHCM 1;
BA_ "U_CDX706_MY2023_Tx" SG_ 2611001560 PARSEDPhysGWM_ECGtoCHCM 1;
BA_ "GenSigSendType" SG_ 2611175470 PARSEDPhysCHCMtoGWM_ECG 3;
BA_ "ECGUsedRxSignal" SG_ 2611175470 PARSEDPhysCHCMtoGWM_ECG 1;
BA_ "U_CD542_MY2021_Rx" SG_ 2611175470 PARSEDPhysCHCMtoGWM_ECG 1;
BA_ "U_U55X_MY2022_Rx" SG_ 2611175470 PARSEDPhysCHCMtoGWM_ECG 1;
BA_ "U_CDX706_MY2023_Rx" SG_ 2611175470 PARSEDPhysCHCMtoGWM_ECG 1;
BA_ "U_T6_MCA_MY2020_Tx" SG_ 2611175470 PARSEDPhysCHCMtoGWM_ECG 1;
BA_ "GenSigSendType" SG_ 2612224046 PARSEDPushCHCMtoGWM_ECG 3;
BA_ "ECGUsedRxSignal" SG_ 2612224046 PARSEDPushCHCMtoGWM_ECG 1;
BA_ "U_CD542_MY2021_Rx" SG_ 2612224046 PARSEDPushCHCMtoGWM_ECG 1;
BA_ "U_U55X_MY2022_Rx" SG_ 2612224046 PARSEDPushCHCMtoGWM_ECG 1;
BA_ "U_CDX706_MY2023_Rx" SG_ 2612224046 PARSEDPushCHCMtoGWM_ECG 1;
BA_ "U_T6_MCA_MY2020_Tx" SG_ 2612224046 PARSEDPushCHCMtoGWM_ECG 1;
BA_ "GenSigSendType" SG_ 2609952984 OTAPhysGWM_ECGtoCHCM 3;
BA_ "ECGUsedTxSignal" SG_ 2609952984 OTAPhysGWM_ECGtoCHCM 1;
BA_ "U_CD542_MY2021_Tx" SG_ 2609952984 OTAPhysGWM_ECGtoCHCM 1;
BA_ "U_U55X_MY2022_Tx" SG_ 2609952984 OTAPhysGWM_ECGtoCHCM 1;
BA_ "U_CD764_MY2022_Tx" SG_ 2609952984 OTAPhysGWM_ECGtoCHCM 1;
BA_ "U_CDX706_MY2023_Tx" SG_ 2609952984 OTAPhysGWM_ECGtoCHCM 1;
BA_ "GenSigSendType" SG_ 2610126894 OTAPhysCHCMtoGWM_ECG 3;
BA_ "ECGUsedRxSignal" SG_ 2610126894 OTAPhysCHCMtoGWM_ECG 1;
BA_ "U_CD542_MY2021_Rx" SG_ 2610126894 OTAPhysCHCMtoGWM_ECG 1;
BA_ "U_U55X_MY2022_Rx" SG_ 2610126894 OTAPhysCHCMtoGWM_ECG 1;
BA_ "U_CDX706_MY2023_Rx" SG_ 2610126894 OTAPhysCHCMtoGWM_ECG 1;
BA_ "GenSigSendType" SG_ 2612050136 PARSEDPushGWM_ECGtoCHCM 3;
BA_ "U_T6_MCA_MY2020_Rx" SG_ 2612050136 PARSEDPushGWM_ECGtoCHCM 1;
BA_ "ECGUsedTxSignal" SG_ 2612050136 PARSEDPushGWM_ECGtoCHCM 1;
BA_ "U_CD542_MY2021_Tx" SG_ 2612050136 PARSEDPushGWM_ECGtoCHCM 1;
BA_ "U_U55X_MY2022_Tx" SG_ 2612050136 PARSEDPushGWM_ECGtoCHCM 1;
BA_ "U_CDX706_MY2023_Tx" SG_ 2612050136 PARSEDPushGWM_ECGtoCHCM 1;
BA_ "GenSigStartValueInteger" SG_ 788 EcoCochDecel2_Pc_Dsply 255;
BA_ "GenSigStartValue" SG_ 788 EcoCochDecel2_Pc_Dsply 255;
BA_ "U_T6_MCA_MY2020_Tx" SG_ 788 EcoCochDecel2_Pc_Dsply 1;
BA_ "U_CD764_MY2022_Tx" SG_ 788 EcoCochDecel2_Pc_Dsply 1;
BA_ "U_CDX706_MY2023_Tx" SG_ 788 EcoCochDecel2_Pc_Dsply 1;
BA_ "GenSigStartValueInteger" SG_ 788 EcoCochDecel1_Pc_Dsply 255;
BA_ "GenSigStartValue" SG_ 788 EcoCochDecel1_Pc_Dsply 255;
BA_ "U_T6_MCA_MY2020_Tx" SG_ 788 EcoCochDecel1_Pc_Dsply 1;
BA_ "U_CD764_MY2022_Tx" SG_ 788 EcoCochDecel1_Pc_Dsply 1;
BA_ "U_CDX706_MY2023_Tx" SG_ 788 EcoCochDecel1_Pc_Dsply 1;
BA_ "GenSigStartValueInteger" SG_ 788 EcoCochCrus2_Pc_Dsply 255;
BA_ "GenSigStartValue" SG_ 788 EcoCochCrus2_Pc_Dsply 255;
BA_ "U_T6_MCA_MY2020_Tx" SG_ 788 EcoCochCrus2_Pc_Dsply 1;
BA_ "U_CD764_MY2022_Tx" SG_ 788 EcoCochCrus2_Pc_Dsply 1;
BA_ "U_CDX706_MY2023_Tx" SG_ 788 EcoCochCrus2_Pc_Dsply 1;
BA_ "GenSigStartValueInteger" SG_ 788 EcoCochCrus1_Pc_Dsply 255;
BA_ "GenSigStartValue" SG_ 788 EcoCochCrus1_Pc_Dsply 255;
BA_ "U_T6_MCA_MY2020_Tx" SG_ 788 EcoCochCrus1_Pc_Dsply 1;
BA_ "U_CD764_MY2022_Tx" SG_ 788 EcoCochCrus1_Pc_Dsply 1;
BA_ "U_CDX706_MY2023_Tx" SG_ 788 EcoCochCrus1_Pc_Dsply 1;
BA_ "GenSigStartValueInteger" SG_ 788 EcoCochATrip2_Pc_Dsply 255;
BA_ "GenSigStartValue" SG_ 788 EcoCochATrip2_Pc_Dsply 255;
BA_ "U_T6_MCA_MY2020_Tx" SG_ 788 EcoCochATrip2_Pc_Dsply 1;
BA_ "U_CD764_MY2022_Tx" SG_ 788 EcoCochATrip2_Pc_Dsply 1;
BA_ "U_CDX706_MY2023_Tx" SG_ 788 EcoCochATrip2_Pc_Dsply 1;
BA_ "GenSigStartValueInteger" SG_ 788 EcoCochATrip1_Pc_Dsply 255;
BA_ "GenSigStartValue" SG_ 788 EcoCochATrip1_Pc_Dsply 255;
BA_ "U_T6_MCA_MY2020_Tx" SG_ 788 EcoCochATrip1_Pc_Dsply 1;
BA_ "U_CD764_MY2022_Tx" SG_ 788 EcoCochATrip1_Pc_Dsply 1;
BA_ "U_CDX706_MY2023_Tx" SG_ 788 EcoCochATrip1_Pc_Dsply 1;
BA_ "U_CDX706_MY2023_Rx" SG_ 536 BrkCtlSys_D_Stat 1;
BA_ "U_CDX706_MY2023_Tx" SG_ 536 BrkCtlSys_D_Stat 1;
BA_ "GenSigStartValue" SG_ 536 VehStab_D_Cnfm 14;
BA_ "U_CDX706_MY2023_Rx" SG_ 536 VehStab_D_Cnfm 1;
BA_ "U_CDX706_MY2023_Tx" SG_ 536 VehStab_D_Cnfm 1;
BA_ "MetaData" SG_ 536 BrkWhlFricTq_No_Cs 1;
BA_ "U_CDX706_MY2023_Rx" SG_ 536 BrkWhlFricTq_No_Cs 1;
BA_ "MetaData" SG_ 536 BrkWhlFricTq_No_Cnt 1;
BA_ "U_CDX706_MY2023_Rx" SG_ 536 BrkWhlFricTq_No_Cnt 1;
BA_ "GenSigStartValue" SG_ 536 BrkWhlFricRr_Tq_Actl 254;
BA_ "U_CDX706_MY2023_Rx" SG_ 536 BrkWhlFricRr_Tq_Actl 1;
BA_ "U_CDX706_MY2023_Tx" SG_ 536 BrkWhlFricRr_Tq_Actl 1;
BA_ "GenSigStartValue" SG_ 536 BrkWhlFricRl_Tq_Actl 254;
BA_ "U_CDX706_MY2023_Rx" SG_ 536 BrkWhlFricRl_Tq_Actl 1;
BA_ "U_CDX706_MY2023_Tx" SG_ 536 BrkWhlFricRl_Tq_Actl 1;
BA_ "GenSigStartValue" SG_ 536 BrkWhlFricFr_Tq_Actl 254;
BA_ "U_CDX706_MY2023_Rx" SG_ 536 BrkWhlFricFr_Tq_Actl 1;
BA_ "U_CDX706_MY2023_Tx" SG_ 536 BrkWhlFricFr_Tq_Actl 1;
BA_ "GenSigStartValue" SG_ 536 BrkWhlFricFl_Tq_Actl 254;
BA_ "U_CDX706_MY2023_Rx" SG_ 536 BrkWhlFricFl_Tq_Actl 1;
BA_ "U_CDX706_MY2023_Tx" SG_ 536 BrkWhlFricFl_Tq_Actl 1;
BA_ "GenSigSendType" SG_ 824 DteVeh_V_Actl 3;
BA_ "ECGUsedTxSignal" SG_ 824 DteVeh_V_Actl 1;
BA_ "U_CDX706_MY2023_Tx" SG_ 824 DteVeh_V_Actl 1;
BA_ "GenSigSendType" SG_ 824 DteCldCompltRoute_B_Rq 3;
BA_ "ECGUsedTxSignal" SG_ 824 DteCldCompltRoute_B_Rq 1;
BA_ "U_CD542_MY2021_Tx" SG_ 824 DteCldCompltRoute_B_Rq 1;
BA_ "U_CDX706_MY2023_Tx" SG_ 824 DteCldCompltRoute_B_Rq 1;
BA_ "GenSigSendType" SG_ 824 DteCldTrlrOn_B_Stat 3;
BA_ "ECGUsedTxSignal" SG_ 824 DteCldTrlrOn_B_Stat 1;
BA_ "U_CD542_MY2021_Tx" SG_ 824 DteCldTrlrOn_B_Stat 1;
BA_ "U_U55X_MY2022_Tx" SG_ 824 DteCldTrlrOn_B_Stat 1;
BA_ "U_CDX706_MY2023_Tx" SG_ 824 DteCldTrlrOn_B_Stat 1;
BA_ "GenSigSendType" SG_ 824 DteCldTrlrOff_B_Stat 3;
BA_ "ECGUsedTxSignal" SG_ 824 DteCldTrlrOff_B_Stat 1;
BA_ "U_CD542_MY2021_Tx" SG_ 824 DteCldTrlrOff_B_Stat 1;
BA_ "U_U55X_MY2022_Tx" SG_ 824 DteCldTrlrOff_B_Stat 1;
BA_ "U_CDX706_MY2023_Tx" SG_ 824 DteCldTrlrOff_B_Stat 1;
BA_ "GenSigSendType" SG_ 824 DteCldTraffic_B_Stat 3;
BA_ "ECGUsedTxSignal" SG_ 824 DteCldTraffic_B_Stat 1;
BA_ "U_CD542_MY2021_Tx" SG_ 824 DteCldTraffic_B_Stat 1;
BA_ "U_U55X_MY2022_Tx" SG_ 824 DteCldTraffic_B_Stat 1;
BA_ "U_CDX706_MY2023_Tx" SG_ 824 DteCldTraffic_B_Stat 1;
BA_ "GenSigSendType" SG_ 824 DteCldTerrain_B_Stat 3;
BA_ "ECGUsedTxSignal" SG_ 824 DteCldTerrain_B_Stat 1;
BA_ "U_CD542_MY2021_Tx" SG_ 824 DteCldTerrain_B_Stat 1;
BA_ "U_U55X_MY2022_Tx" SG_ 824 DteCldTerrain_B_Stat 1;
BA_ "U_CDX706_MY2023_Tx" SG_ 824 DteCldTerrain_B_Stat 1;
BA_ "GenSigSendType" SG_ 824 DteCldRoute_B_Stat 3;
BA_ "ECGUsedTxSignal" SG_ 824 DteCldRoute_B_Stat 1;
BA_ "U_CD542_MY2021_Tx" SG_ 824 DteCldRoute_B_Stat 1;
BA_ "U_U55X_MY2022_Tx" SG_ 824 DteCldRoute_B_Stat 1;
BA_ "U_CDX706_MY2023_Tx" SG_ 824 DteCldRoute_B_Stat 1;
BA_ "GenSigSendType" SG_ 824 DteCldPayload_B_Stat 3;
BA_ "ECGUsedTxSignal" SG_ 824 DteCldPayload_B_Stat 1;
BA_ "U_CD542_MY2021_Tx" SG_ 824 DteCldPayload_B_Stat 1;
BA_ "U_U55X_MY2022_Tx" SG_ 824 DteCldPayload_B_Stat 1;
BA_ "U_CDX706_MY2023_Tx" SG_ 824 DteCldPayload_B_Stat 1;
BA_ "GenSigSendType" SG_ 824 DteCldId_No_Actl 3;
BA_ "ECGUsedTxSignal" SG_ 824 DteCldId_No_Actl 1;
BA_ "U_CD542_MY2021_Tx" SG_ 824 DteCldId_No_Actl 1;
BA_ "U_U55X_MY2022_Tx" SG_ 824 DteCldId_No_Actl 1;
BA_ "U_CDX706_MY2023_Tx" SG_ 824 DteCldId_No_Actl 1;
BA_ "GenSigSendType" SG_ 824 DteCldExtTe_B_Stat 3;
BA_ "ECGUsedTxSignal" SG_ 824 DteCldExtTe_B_Stat 1;
BA_ "U_CD542_MY2021_Tx" SG_ 824 DteCldExtTe_B_Stat 1;
BA_ "U_U55X_MY2022_Tx" SG_ 824 DteCldExtTe_B_Stat 1;
BA_ "U_CDX706_MY2023_Tx" SG_ 824 DteCldExtTe_B_Stat 1;
BA_ "GenSigSendType" SG_ 824 DteCldExt_Eff_Actl 3;
BA_ "GenSigStartValue" SG_ 824 DteCldExt_Eff_Actl 100;
BA_ "ECGUsedTxSignal" SG_ 824 DteCldExt_Eff_Actl 1;
BA_ "U_CD542_MY2021_Tx" SG_ 824 DteCldExt_Eff_Actl 1;
BA_ "U_U55X_MY2022_Tx" SG_ 824 DteCldExt_Eff_Actl 1;
BA_ "U_CDX706_MY2023_Tx" SG_ 824 DteCldExt_Eff_Actl 1;
BA_ "GenSigSendType" SG_ 824 DteCldDrv_Eff_Actl 3;
BA_ "GenSigStartValue" SG_ 824 DteCldDrv_Eff_Actl 100;
BA_ "ECGUsedTxSignal" SG_ 824 DteCldDrv_Eff_Actl 1;
BA_ "U_CD542_MY2021_Tx" SG_ 824 DteCldDrv_Eff_Actl 1;
BA_ "U_U55X_MY2022_Tx" SG_ 824 DteCldDrv_Eff_Actl 1;
BA_ "U_CDX706_MY2023_Tx" SG_ 824 DteCldDrv_Eff_Actl 1;
BA_ "GenSigSendType" SG_ 824 DteCldDcac_B_Stat 3;
BA_ "ECGUsedTxSignal" SG_ 824 DteCldDcac_B_Stat 1;
BA_ "U_CD542_MY2021_Tx" SG_ 824 DteCldDcac_B_Stat 1;
BA_ "U_U55X_MY2022_Tx" SG_ 824 DteCldDcac_B_Stat 1;
BA_ "U_CDX706_MY2023_Tx" SG_ 824 DteCldDcac_B_Stat 1;
BA_ "GenSigSendType" SG_ 824 DteCldClimt_Eff_Actl 3;
BA_ "GenSigStartValue" SG_ 824 DteCldClimt_Eff_Actl 100;
BA_ "ECGUsedTxSignal" SG_ 824 DteCldClimt_Eff_Actl 1;
BA_ "U_CD542_MY2021_Tx" SG_ 824 DteCldClimt_Eff_Actl 1;
BA_ "U_U55X_MY2022_Tx" SG_ 824 DteCldClimt_Eff_Actl 1;
BA_ "U_CDX706_MY2023_Tx" SG_ 824 DteCldClimt_Eff_Actl 1;
BA_ "GenSigSendType" SG_ 824 DteCldBattULo_Eff_Actl 3;
BA_ "GenSigStartValue" SG_ 824 DteCldBattULo_Eff_Actl 100;
BA_ "ECGUsedTxSignal" SG_ 824 DteCldBattULo_Eff_Actl 1;
BA_ "U_CD542_MY2021_Tx" SG_ 824 DteCldBattULo_Eff_Actl 1;
BA_ "U_U55X_MY2022_Tx" SG_ 824 DteCldBattULo_Eff_Actl 1;
BA_ "U_CDX706_MY2023_Tx" SG_ 824 DteCldBattULo_Eff_Actl 1;
BA_ "GenSigSendType" SG_ 824 DteCldTrip_L2_Actl 3;
BA_ "GenSigStartValue" SG_ 824 DteCldTrip_L2_Actl 8190;
BA_ "ECGUsedTxSignal" SG_ 824 DteCldTrip_L2_Actl 1;
BA_ "U_CD542_MY2021_Tx" SG_ 824 DteCldTrip_L2_Actl 1;
BA_ "U_U55X_MY2022_Tx" SG_ 824 DteCldTrip_L2_Actl 1;
BA_ "U_CDX706_MY2023_Tx" SG_ 824 DteCldTrip_L2_Actl 1;
BA_ "GenSigSendType" SG_ 823 DteVehPwId_No_Actl 3;
BA_ "ECGUsedRxSignal" SG_ 823 DteVehPwId_No_Actl 1;
BA_ "U_CD542_MY2021_Rx" SG_ 823 DteVehPwId_No_Actl 1;
BA_ "U_U55X_MY2022_Rx" SG_ 823 DteVehPwId_No_Actl 1;
BA_ "U_CDX706_MY2023_Rx" SG_ 823 DteVehPwId_No_Actl 1;
BA_ "ECGUsedRxSignal" SG_ 823 DteVehEId_No_Actl 1;
BA_ "U_CD542_MY2021_Rx" SG_ 823 DteVehEId_No_Actl 1;
BA_ "U_U55X_MY2022_Rx" SG_ 823 DteVehEId_No_Actl 1;
BA_ "U_CDX706_MY2023_Rx" SG_ 823 DteVehEId_No_Actl 1;
BA_ "ECGUsedRxSignal" SG_ 823 DteVehEffId_No_Actl 1;
BA_ "U_CD542_MY2021_Rx" SG_ 823 DteVehEffId_No_Actl 1;
BA_ "U_U55X_MY2022_Rx" SG_ 823 DteVehEffId_No_Actl 1;
BA_ "U_CDX706_MY2023_Rx" SG_ 823 DteVehEffId_No_Actl 1;
BA_ "ECGUsedRxSignal" SG_ 823 DteVeh_Pw_Actl 1;
BA_ "U_CD542_MY2021_Rx" SG_ 823 DteVeh_Pw_Actl 1;
BA_ "U_U55X_MY2022_Rx" SG_ 823 DteVeh_Pw_Actl 1;
BA_ "U_CDX706_MY2023_Rx" SG_ 823 DteVeh_Pw_Actl 1;
BA_ "GenSigStartValue" SG_ 823 DteVeh_Eff_Actl 100;
BA_ "ECGUsedRxSignal" SG_ 823 DteVeh_Eff_Actl 1;
BA_ "U_CD542_MY2021_Rx" SG_ 823 DteVeh_Eff_Actl 1;
BA_ "U_U55X_MY2022_Rx" SG_ 823 DteVeh_Eff_Actl 1;
BA_ "U_CDX706_MY2023_Rx" SG_ 823 DteVeh_Eff_Actl 1;
BA_ "ECGUsedRxSignal" SG_ 823 DteVeh_E_Actl 1;
BA_ "U_CD542_MY2021_Rx" SG_ 823 DteVeh_E_Actl 1;
BA_ "U_U55X_MY2022_Rx" SG_ 823 DteVeh_E_Actl 1;
BA_ "U_CDX706_MY2023_Rx" SG_ 823 DteVeh_E_Actl 1;
BA_ "GenSigSendType" SG_ 823 DteAcceptNew_B_Rq 3;
BA_ "ECGUsedRxSignal" SG_ 823 DteAcceptNew_B_Rq 1;
BA_ "U_CD542_MY2021_Rx" SG_ 823 DteAcceptNew_B_Rq 1;
BA_ "U_U55X_MY2022_Rx" SG_ 823 DteAcceptNew_B_Rq 1;
BA_ "U_CDX706_MY2023_Rx" SG_ 823 DteAcceptNew_B_Rq 1;
BA_ "ECGUsedRxSignal" SG_ 823 DteVehE_T_Actl 1;
BA_ "U_CD542_MY2021_Rx" SG_ 823 DteVehE_T_Actl 1;
BA_ "U_U55X_MY2022_Rx" SG_ 823 DteVehE_T_Actl 1;
BA_ "U_CDX706_MY2023_Rx" SG_ 823 DteVehE_T_Actl 1;
BA_ "GenSigSendType" SG_ 1920 TesterPhysicalReqSGM 3;
BA_ "GenSigStartValue" SG_ 811 ScMnSoc_Pc_RqMnu 126;
BA_ "U_T6_MCA_MY2020_Rx" SG_ 811 OnePdlDrvButtn_B_Falt 1;
BA_ "U_T6_MCA_MY2020_Rx" SG_ 811 OnePdlDrvButtn_B_Stat 1;
BA_ "GenSigStartValue" SG_ 811 DistToStopover_L_Actl 65535;
BA_ "WakeupSignal" SG_ 811 ExtLghtRight_D_RqMnu 1;
BA_ "WakeupSignal" SG_ 811 AutoLghtOvrrd_B_RqDrv 1;
BA_ "WakeupSignal" SG_ 811 ExtLghtRear_D_RqMnu 1;
BA_ "WakeupSignal" SG_ 811 ExtLghtLeft_D_RqMnu 1;
BA_ "WakeupSignal" SG_ 811 ExtLghtFront_D_RqMnu 1;
BA_ "GenSigStartValue" SG_ 811 GoTEditMnte_T_RqMnu 14;
BA_ "GenSigStartValue" SG_ 811 GoTEditHr_T_RqMnu 30;
BA_ "WakeupSignal" SG_ 811 BecRleas_No_RqMnu 1;
BA_ "WakeupSignal" SG_ 811 TrnkFrontRleas_No_RqMnu 1;
VAL_ 1057 FohEng_D_Rq 3 "AutoEnable_ParkEnable" 2 "AutoDisable_ParkEnable" 1 "AutoEnable_ParkDisable" 0 "Disable_Stop" ;
VAL_ 1057 EngIdlShutDwnTxt_D_Rq 3 "NotUsed" 2 "EngineShutdownOnPrevDrive" 1 "FeatureDisabledDueToFault" 0 "NoMessage" ;
VAL_ 1057 EngIdlShutDown_D_Stat 3 "Not_used" 2 "Engine_Shutdown" 1 "Initiated_Countdown" 0 "Normal_Operation" ;
VAL_ 1057 FUEL_ALCOHOL_PERCNT 255 "Invalid" ;
VAL_ 1057 TrnTotTq_Rt_Est 65535 "Fault" 65534 "Unknown" ;
VAL_ 1057 TrnTotLss_Tq_Est 255 "Fault" 254 "Unknown" ;
VAL_ 1057 ECMMILRequest 3 "Not_Used" 2 "Flash" 1 "On" 0 "Off" ;
VAL_ 1057 AirCondFluidHi_P_Actl 255 "Fault" 254 "Unknown" ;
VAL_ 1057 OilPressureWarning 1 "Low_Pressure_Lamp_On" 0 "Normal_Pressure_Lamp_Off" ;
VAL_ 1057 VehVLimStat_D_Actl 7 "Undefined_3" 6 "Undefined_2" 5 "Undefined_1" 4 "ASL_Fault_Condition" 3 "Active_and_Limiting" 2 "Active_but_Not_Limiting" 1 "Standby" 0 "Off" ;
VAL_ 1057 VehVLimActv_B_Actl 1 "Active" 0 "Inactive" ;
VAL_ 1057 CoolantFanStepAct 31 "Unused7" 30 "Unused6" 29 "Unused5" 28 "Unused4" 27 "Unused3" 26 "Unused2" 25 "Unused1" 23 "Step23" 22 "Step22" 21 "Step21" 20 "Step20" 19 "Step19" 18 "Step18" 17 "Step17" 16 "Step16" 15 "Step15" 14 "Step14" 13 "Step13" 12 "Step12" 11 "Step11" 10 "Step10" 9 "Step9" 8 "Step8" 7 "Step7" 6 "Step6" 5 "Step5" 4 "Step4" 3 "Step3" 2 "Step2" 1 "Step1" 24 "Max_Fan_Speed_Req" 0 "Fan_Cmd_Off" ;
VAL_ 1055 EcoCochInstNeg_B_Dsply 1 "True" 0 "False" ;
VAL_ 562 GearNtrl_D_Stat 3 "Faulty" 2 "NoDataExists" 1 "Yes" 0 "No" ;
VAL_ 562 OnePdlDrv_D_Stat 3 "Enabled_BrkLampAndFbrk" 2 "Enabled_BrkLamp" 1 "Enabled_NoAction" 0 "Disabled" ;
VAL_ 523 EngAirFiltMsgTxt_D_Rq 7 "NotUsed_2" 6 "ReducedEngPwCheckAirFilter" 5 "EngineAirFilterMonitorFalt" 4 "ResetComplete" 3 "Clogged" 2 "ReplaceNow" 1 "ReplaceSoon" 0 "NoMessage" ;
VAL_ 523 WaterInFuel_B_Falt 1 "Fault" 0 "No_Fault" ;
VAL_ 523 UreaMnAdd_L2_Actl 255 "Faulty" ;
VAL_ 523 UreaMxAdd_L2_Actl 511 "Faulty" ;
VAL_ 519 RearDiffLck_Tq_Rq 16383 "Faulty" 16382 "NoDataExists" ;
VAL_ 517 FapLc_B_Err 1 "Yes" 0 "No" ;
VAL_ 516 EngAoutNActl_D_QF 3 "OK" 2 "Not_Within_Specifications" 1 "No_Data_Exists" 0 "Faulty" ;
VAL_ 516 EngAout3_N_Actl 65535 "Invalid" ;
VAL_ 516 ApedPosPcActl_D_Qf 3 "OK" 2 "Not_Within_Specifications" 1 "No_Data_Exists" 0 "Faulty" ;
VAL_ 516 ApedPos_PcRate_ActlArb 255 "Fault" 254 "Unknown" ;
VAL_ 514 StrtrMtrDlyStrt_B_Stat 1 "Yes" 0 "No" ;
VAL_ 514 VehVTrlrAid_B_Avail 1 "Yes" 0 "No" ;
VAL_ 514 StrtrMtrCtlMsgTxt_D_Rq 7 "Start_In_Gear_Allowed" 6 "Pending_Start_Cancelled" 5 "Start_Pending_Please_Wait" 4 "Cranking_Limit_Exceeded" 3 "Press_Brk_and_Shift_to_P_N" 2 "Press_Clutch_and_Brake" 1 "Press_Clutch_To_Start" 0 "No_Display" ;
VAL_ 514 VehVActlEng_D_Qf 3 "OK" 2 "Not_Within_Specifications" 1 "No_Data_Exists" 0 "Faulty" ;
VAL_ 514 GearRvrse_D_Actl 7 "Fault" 6 "NotUsed_3" 5 "NotUsed_2" 4 "NotUsed_1" 3 "Active_confirmed" 2 "Active_not_confirmed" 1 "Inactive_confirmed" 0 "Inactive_not_confirmed" ;
VAL_ 514 StrtrMtrCtlMsgTxt_D2_Rq 3 "NoRequestPcmStartingMsgCtl" 2 "ShiftToNeutralToStart" 1 "ShiftToParkToStart" 0 "NoRequestBcmStartingMsgCtl" ;
VAL_ 512 PtDrvMde_D_Stat 15 "Faulty" 14 "NotUsed11" 13 "NotUsed10" 12 "NotUsed9" 11 "NotUsed8" 10 "NotUsed7" 9 "NotUsed6" 8 "Track" 7 "Drag" 6 "Rock" 5 "Baja" 4 "Sand" 3 "TowHaulGradeAssist" 2 "SnowWet" 1 "Sport" 0 "Normal" ;
VAL_ 382 EngIdlShutDown_D2_Type 3 "Fleet" 2 "Keyless" 1 "Keyed" 0 "Null" ;
VAL_ 382 DcacOut2_Pw2_Dsply 8191 "Faulty" 8190 "NoDataExists" ;
VAL_ 382 DcacOut1_Pw2_Dsply 8191 "Faulty" 8190 "NoDataExists" ;
VAL_ 382 EngMnfldChrg_Te_Actl 127 "Faulty" 126 "NoDataExists" ;
VAL_ 382 EngInnrClnt_Te_Actl 127 "Faulty" 126 "NoDataExists" ;
VAL_ 381 EngOilSrvcMsgTxt_D_Rq 7 "NotUsed3" 6 "OilMinderNotConfigured" 5 "ResetFailed" 4 "ResetComplete" 3 "ResetInProgress" 2 "ChangeOilNow" 1 "ChangeOilSoon" 0 "NoText" ;
VAL_ 381 RunDryPrevent_B_Stat 1 "True" 0 "False" ;
VAL_ 381 WaterInFuel 1 "On" 0 "Off" ;
VAL_ 381 GlowIndication 1 "On" 0 "Off" ;
VAL_ 380 FuelMaintMde_D_Rq 3 "Feature_Not_Present" 2 "Fuel_Maint_Req_Now" 1 "Fuel_Maint_Req_Soon" 0 "NoRequest" ;
VAL_ 380 GrdAsstAllw_D_DsplyPt 3 "NotUsed" 2 "On" 1 "Off" 0 "NoModeSelected" ;
VAL_ 380 EngOilLvlWarn_D_Rq1 7 "Undefined_3" 6 "Undefined_2" 5 "Engine_Oil_Monitor_Fault" 3 "Engine_Oil_High" 2 "Engine_Oil_Critical_Low" 1 "Engine_Oil_Low" 0 "No_Message" 4 "Engine_Oil_Critical_High" ;
VAL_ 380 EngExhBrkOnLamp_B_Rq 1 "On" 0 "Off" ;
VAL_ 380 EngExhBrkAutoLamp_B_Rq 1 "On" 0 "Off" ;
VAL_ 380 EngExhBrkMde_D_Actl 6 "ExhBrkDisable_NoError" 5 "ExhBrkActive_AUTO" 4 "ExhBrkActive_ON" 3 "ExhBrkRequest_AUTO" 2 "ExhBrkRequest_ON" 1 "ExhBrkNoRequest_OFF" 0 "ExhBrkUnavailable_Error" ;
VAL_ 380 WhlRearDual_D_Stat 3 "NotUsed" 2 "Dual" 1 "Single" 0 "NoDataExists" ;
VAL_ 380 PwStep_D_DrvInhbt 3 "NotUsed" 2 "DriveInhibitMalfunction" 1 "DriveInhibited" 0 "DriveNotInhibited" ;
VAL_ 377 HvacAirFullOut_B_Rq 1 "Yes" 0 "No" ;
VAL_ 377 TrnManShif_D_IndDrv 7 "Undefined_3" 6 "Undefined_2" 5 "Shift_to_Neutral" 4 "Downshift_Recommendation" 3 "Upshift_Warning" 2 "Upshift_Performance" 1 "Upshift_Fuel_Economy" 0 "No_Indication" ;
VAL_ 377 TrnManShifGear_D_IndDrv 7 "Indicate_Reverse_Gear" 6 "Indicate_Gear6" 5 "Indicate_Gear5" 4 "Indicate_Gear4" 3 "Indicate_Gear3" 2 "Indicate_Gear2" 1 "Indicate_Gear1" 0 "No_Indication" ;
VAL_ 377 EngFuelCutFull_B_Inhbt 1 "Inhibit_DFSO" 0 "Normal" ;
VAL_ 377 EngDecelFuelCut_B_Allw 1 "Yes" 0 "No" ;
VAL_ 377 FuelFillInlet_B_Dsply 1 "Yes" 0 "No" ;
VAL_ 377 EngSrvcRqd_B_Rq 1 "Engine_Service_Required" 0 "No_engine_service_required" ;
VAL_ 377 OdoCount 255 "Invalid" ;
VAL_ 377 TrnKickDown_B_RqDrv 1 "Yes" 0 "No" ;
VAL_ 377 FuelFilterLamp_B_Dsply 1 "On" 0 "Off" ;
VAL_ 377 AirCondRec_B_Rq 1 "Yes" 0 "No" ;
VAL_ 377 AirCondClutch_B_Stats 1 "Yes" 0 "No" ;
VAL_ 377 EngAoutTqActl_D_Qf 3 "OK" 2 "Not_Within_Specifications" 1 "No_Data_Exists" 0 "Faulty" ;
VAL_ 376 GasPrtc_D_RqDsply 7 "NotUsed_5" 6 "NotUsed_4" 5 "NotUsed_3" 4 "NotUsed_2" 3 "NotUsed_1" 2 "GpfOverLimit" 1 "GpfAtLimit" 0 "NormalOperation" ;
VAL_ 376 LnchCtlSys_D_Stat 7 "NotUsed" 6 "On_LC_Unavailable_TC_Off" 5 "On_LC_Available_TC_Off" 4 "On_LC_Unavailable_TC_On" 3 "On_LC_Unavailable" 2 "On_LC_Available" 1 "On_LC_Active" 0 "LC_OFF" ;
VAL_ 376 DynoMde_B_Cmd 1 "DynomometerMode" 0 "NormalOperation" ;
VAL_ 376 AslChime_B_Rq 1 "Yes" 0 "No" ;
VAL_ 376 HvacHtrCore2_Te_Actl 1023 "Faulty" ;
VAL_ 376 PtcHtr_D_Cmd 3 "TurnOn" 2 "AutoMode" 1 "TurnOff" 0 "NoDecision_Initializing" ;
VAL_ 376 EcssLamp_D_RqDsply 3 "Not_Used" 2 "Flash" 1 "On" 0 "Off" ;
VAL_ 376 AirAmbTe_D_Qf 3 "OK" 2 "Not_Within_Specifications" 1 "No_Data_Exists" 0 "Faulty" ;
VAL_ 376 AirAmb_P_Actl 63 "Fault" 62 "NoDataExists" ;
VAL_ 376 AslIconDsply_D_Rq 3 "On_Passive_Overridden" 2 "On_Active" 1 "On_Passive" 0 "Off" ;
VAL_ 373 DieslPrtc2_D_RqDsply 15 "NotUsed4" 14 "NotUsed3" 13 "NotUsed2" 12 "NotUsed1" 11 "OCR_ExhFilterClean_Stopped" 10 "OCR_ExhFilterCleaned" 9 "RgnOff_AtLimit" 8 "RgnOff_Overloaded" 7 "RgnOff_Loaded" 6 "Exhaust_Filter_Full" 5 "DPF_Overlimit" 4 "DPF_AtLimit" 3 "ExhFilter_Drive_Completed" 2 "Cleaning_Exhaust_Filter" 1 "DPF_Overloaded" 0 "DPF_Normal_Operation" ;
VAL_ 373 DieslPrtc_D_RqDsply 7 "Unused_2" 6 "Unused_1" 5 "DPF_SOOT_Level3_Blocked" 4 "DPFSootLvl2_SevereOverload" 3 "DPFRegen_ExhFilterComplete" 2 "DPFRegen_CleanExhFilter" 1 "DPF_Soot_Level1_Overloaded" 0 "DPF_OK_Normal_Operation" ;
VAL_ 373 DieslPrtcRgen_D_Actl 3 "Undefined" 2 "Regen_Level_2" 1 "Regen_Level_1" 0 "No_regen" ;
VAL_ 373 DieslPrtcRgen_D_Rq 7 "Unused_2" 6 "Unused_1" 5 "Full_Regen_2" 4 "Full_Regen_1" 3 "HeatUp_3" 2 "HeatUp_2" 1 "HeatUp_1" 0 "Normal_Mode_NoRegen" ;
VAL_ 373 EngFuelCutFull_B_Allw 1 "Yes" 0 "No" ;
VAL_ 373 EngTurboMde_D_Actl 3 "Fault" 2 "One_Turbo_Active" 1 "Two_Turbos_Active" 0 "Initializing" ;
VAL_ 373 EngTeColdPrtct_D_Stats 3 "Engine_Warm_RdcPwr" 2 "OK_to_Drive" 1 "Engine_Warm_PlsWait" 0 "Normal_Operation" ;
VAL_ 373 EngExhOvrTe_B_RqDsply 1 "Active" 0 "Inactive" ;
VAL_ 373 EngPtoMde_D_Rq 7 "Undefined" 6 "Split_Shaft_Stationary" 5 "Not_Used_2" 4 "PTO_Mobile" 3 "Not_Used_1" 2 "PTO_Stationary" 1 "BCP" 0 "Off" ;
VAL_ 372 TrnAinTqDtrb_B_Actl 1 "Active" 0 "Inactive" ;
VAL_ 359 PrplWhlRgenMn_Tq_Actl 8191 "Faulty" ;
VAL_ 359 ElPw_D_StatStrtStop 15 "NotUsed6" 14 "NotUsed5" 13 "NotUsed4" 12 "NotUsed3" 11 "NotUsed2" 10 "NotUsed1" 9 "Supported_Level_4" 8 "Supported_Level_3" 7 "Supported_Level_2" 6 "Supported_Level_1" 5 "Limited_Support" 4 "Fault_Limited" 3 "LV_Event_in_Progress" 2 "Not_Supported_Imminent" 1 "Supported_All" 0 "Not_Supported" ;
VAL_ 359 PrplWhlTot2_Tq_Actl 65535 "Fault" 65534 "NoDataExists" ;
VAL_ 359 LscmbbDeny_B_ActlPrpl 1 "Denied" 0 "Allowed" ;
VAL_ 359 LscmbbEngTqMn_B_Actl 1 "Engine_Braking_Activated" 0 "Engine_Braking_Off" ;
VAL_ 359 PwPckTq_D_Stat 3 "PwPckOn_TqAvailable" 2 "StartInPrgrss_TqNotAvail" 1 "PwPckOn_TqNotAvailable" 0 "PwPckOff_TqNotAvailable" ;
VAL_ 359 Eng_D_Stat 3 "NotUsed" 2 "EngAutoStopped" 1 "EngOn" 0 "EngOff" ;
VAL_ 359 PlgActvArb_B_Actl 1 "On" 0 "Off" ;
VAL_ 359 ElPw_D_Stat 7 "NotUsed_3" 6 "NotUsed_2" 5 "NotUsed_1" 4 "Fault_Limited" 3 "LV_Event_In_Progress" 2 "Not_Supported_Imminent" 1 "Supported" 0 "Not_Supported" ;
VAL_ 359 TrnAinTq_D_Qf 3 "OK" 2 "Not_Within_Specifications" 1 "No_Data_Exists" 0 "Faulty" ;
VAL_ 358 StrtrMtrCtlMsgTxt_D3_Rq 7 "NotUsed_5" 6 "NotUsed_4" 5 "NotUsed_3" 4 "NotUsed_2" 3 "NotUsed_1" 2 "BrakeToStopOrD_RtoRestart" 1 "ToDrivePressBrkSelectGear" 0 "NoMessage" ;
VAL_ 358 StopStrtStdby_D_Indic 6 "Telltale_On_Grey" 5 "Telltale_Struck_Out" 4 "Telltale_Flashing_Amber" 3 "Telltale_On_Amber" 2 "Telltale_Flashing_Green" 1 "Telltale_On_Green" 0 "Telltale_Off" 7 "NotUsed3" ;
VAL_ 358 StopStrtIODTxt_D_Rq 31 "Message31" 30 "Message30" 29 "Message29" 28 "Message28" 27 "Message27" 26 "Message26" 25 "Message25" 24 "Message24" 23 "Message23" 22 "Message22" 21 "Message21" 20 "Message20" 19 "Message19" 18 "Message18" 17 "Message17" 16 "Message16" 15 "Message15" 14 "Message14" 13 "Message13" 12 "Message12" 11 "Message11" 10 "Message10" 9 "Message9" 8 "Message8" 7 "Message7" 6 "Message6" 5 "Message5" 4 "Message4" 3 "Message3" 2 "Message2" 1 "Message1" 0 "NoMessage" ;
VAL_ 358 StopStrtDrvMde_D_Indic 3 "NotUsed" 2 "StartStop_IndirectDeselect" 1 "StopStart_Deselected" 0 "StopStart_Selected" ;
VAL_ 358 StopStrtMsgTxt_D_Rq 15 "Message_15" 14 "Message_14" 13 "Message_13" 12 "Message_12" 11 "Message_11" 10 "Message_10" 9 "Message_9" 8 "Message_8" 7 "Message_7" 6 "Message_6" 5 "Message_5" 4 "Message_4" 3 "Message_3" 2 "Message_2" 1 "Message_1" 0 "NoMessage" ;
VAL_ 358 OdoTripVerify_L_Actl 16777215 "Fault" ;
VAL_ 358 HiElPwInhbt_B_Stat 1 "Inhibit" 0 "No_Inibit" ;
VAL_ 358 AutoStopPtDelta_I_Est 255 "Fault" ;
VAL_ 357 BPedDrvAppl_D_QF 3 "OK" 2 "Not_Within_Specifications" 1 "No_Data_Exists" 0 "Faulty" ;
VAL_ 357 CmbbDeny_B_ActlPrpl 1 "Yes" 0 "No" ;
VAL_ 357 PrplTqMnSat_B_Actl 1 "Yes" 0 "No" ;
VAL_ 357 VehStrtStop_D_Rq 3 "NotUsed" 2 "Vehicle_Start_Request" 1 "Vehicle_Stop_Request" 0 "NoRequest" ;
VAL_ 357 BpedDrvAppl_D_Actl 3 "_Not_Allowed" 2 "Driver_Braking" 1 "Driver_Not_Braking" 0 "Not_Allowed" ;
VAL_ 357 CmbbEngTqMn_B_Actl 1 "Yes" 0 "No" ;
VAL_ 357 Veh_V_DsplyCcSet 255 "Fault" 254 "Unknown" ;
VAL_ 357 AccEngStat_D_Actl 7 "Undefined_2" 6 "Undefined_1" 5 "ACCSoonCancel_due_Low_Spd" 4 "Shift_Down_Recommendation" 3 "Shift_Up_Recommendation" 2 "ACCNotAllowedToBeActivated" 1 "ACCStandby_due_Auto_Cancel" 0 "Normal_Operation" ;
VAL_ 357 CcMde_D_Actl 7 "TapDownWaiting" 6 "TapUpWaiting" 5 "Resuming_Low" 4 "Resuming_High" 3 "Decelerating" 2 "Accelerating" 1 "Keeping_Speed" 0 "Not_Active" ;
VAL_ 357 CcStat_D_Actl 7 "Undefined_2" 6 "Undefined_1" 5 "Active" 4 "Active_Que_Assist" 3 "Standby" 2 "Standby_Denied" 1 "Denied" 0 "Off" ;
VAL_ 357 CcOvrrdActv_B_Actl 1 "Cruise_Overridden" 0 "Cruise_Req_Not_Overridden" ;
VAL_ 357 AccStopMde_D_Rq 3 "Stop_Mode_Active" 2 "EPBApplyOrBrakeReleaseWarn" 1 "Limit_Rolling_Speed" 0 "Stop_Mode_Not_Active" ;
VAL_ 355 AutoRgenTxt_B_RqDsply 1 "AutExhFilterCleanOFF" 0 "AutExhFilterCleanON" ;
VAL_ 355 AccFllwMdeActv_B_Actl 1 "Active" 0 "Inactive" ;
VAL_ 355 EngPtoMde_D_Actl 7 "Undefined" 6 "Split_Shaft_Stationary" 5 "Not_Used_2" 4 "PTO_Mobile" 3 "Not_Used_1" 2 "PTO_Stationary" 1 "BCP" 0 "Off" ;
VAL_ 355 ManRgenVeh_V_MinAllw 127 "Fault" ;
VAL_ 355 ManRgenTxt_D_RqDsply 7 "NotUsed3" 6 "NotUsed2" 5 "NotUsed1" 4 "Cleaning_Aborted_Stopped" 3 "Cleaning_Completed" 2 "Cleaning_In_Progress" 1 "Cleaning_Allowed" 0 "Cleaning_Not_Allowed" ;
VAL_ 355 ManRgenSoot_Pc_RqDsply 127 "Fault" ;
VAL_ 355 ManRgenInhbt_T_RqDsply 65535 "Fault" ;
VAL_ 355 ManRgenInhbt_Pc_Soot 127 "Fault" ;
VAL_ 355 ManRgenInhbt_L_RqDsply 65535 "Fault" ;
VAL_ 355 DieslMsgTxt_D_Rq 3 "NotUsed2" 2 "NotUsed1" 1 "ReducedEnginePower" 0 "NoMessage" ;
VAL_ 342 HtrLoop_B_Stat 1 "Fault" 0 "No_Fault" ;
VAL_ 342 TqmTerrMdeChng_D_Rdy 7 "Fault" 6 "Undefined_2" 5 "Undefined_1" 4 "ModeUnavailDrInputRqd" 3 "SpOpModes_NotSupported" 2 "ModeUnavailDynamicCond" 1 "Module_In_Initialization" 0 "Mode_Change_Available" ;
VAL_ 342 TqmTerrMde_D_Actl 7 "Fail_Safe_Default" 6 "Dynamic_Mode" 5 "Rock_Crawl_Mode" 4 "Mud_Ruts_Mode" 3 "Sand_Mode" 2 "Undefined" 1 "Low_Mu_Mode" 0 "Special_Operating_Mode_Off" ;
VAL_ 342 EngOvrhtMitgActv_D_Ind 3 "Undefined" 2 "Mode2" 1 "Mode1" 0 "Normal_Mode" ;
VAL_ 342 EngClntTe_D_Qf 3 "OK" 2 "Not_Within_Specifications" 1 "No_Data_Exists" 0 "Faulty" ;
VAL_ 342 EngAcsyArcPmp_Tq_Actl 255 "Fault" 254 "Unknown" ;
VAL_ 342 EngOilLvlDsply_D_Rq 15 "EngOil_LevelSys_CheckFault" 14 "Reserved_2" 13 "Reserved_1" 12 "Conditions_Unsuitable" 11 "Dipstick_Below_Minimum" 10 "Dipstick_Above_Maximum" 9 "Dipstick_Minimum" 8 "Dipstick_12_5_MinMaxRange" 7 "Dipstick_25_MinMaxRange" 6 "Dipstick_37_5_MinMaxRange" 5 "Dipstick_50_MinMaxRange" 4 "Dipstick_62_5_MinMaxRange" 3 "Dipstick_75_MinMaxRange" 2 "Dipstick_87_5_MinMaxRange" 1 "Dipstick_Maximum_Displayed" 0 "No_Message" ;
VAL_ 342 EngOil_Te_Actl 255 "Fault" 254 "Unknown" ;
VAL_ 342 EngTeColdPrtct_B_Rq 1 "On" 0 "Off" ;
VAL_ 894 RmtCtlTrgt_D_Rq 3 "NotUsed" 2 "Null" 1 "RemoteParkAssist" 0 "ManeuverId" ;
VAL_ 894 RmtCtlRngSet_D_Stat 3 "NotUsed" 2 "RangeSetB" 1 "RangeSetA" 0 "None" ;
VAL_ 894 RmtCtlKeySrch_D_Stat 3 "NotUsed" 2 "Valid" 1 "Invalid" 0 "Null" ;
VAL_ 894 RmtCtlBody_D_Stat 15 "NotUsed_6" 14 "NotUsed_5" 13 "NotUsed_4" 12 "NotUsed_3" 11 "NotUsed_2" 10 "NotUsed_1" 9 "Shutdown" 8 "ManeuverFinished" 7 "ReadyForResume" 6 "Pause" 5 "Maneuvering" 4 "ReadyForManeuvering" 3 "Activation" 2 "Initialize" 1 "Preparation" 0 "Disabled" ;
VAL_ 894 RmtCtl_D_RqBody 7 "NotUsed_2" 6 "NotUsed_1" 5 "Error" 4 "Abort" 3 "PauseKeypad" 2 "PauseHazard" 1 "PauseDoorHandle" 0 "Null" ;
VAL_ 1166 DrOpenPrvntRr_D_Stat 3 "NotUsed" 2 "Overruled" 1 "On" 0 "Off" ;
VAL_ 1166 DrHandleInnrRr_B_Stat 1 "Pulled" 0 "AtRest" ;
VAL_ 1166 DrLatchRrMsgTxt_D_Rq 7 "Message7" 6 "Message6" 5 "Message5" 4 "Message4" 3 "Message3" 2 "Message2" 1 "Message1" 0 "NoMessage" ;
VAL_ 1166 DrLatchRr_B_Falt 1 "Yes" 0 "No" ;
VAL_ 1166 DrLatchLckRr_B_Stat 1 "Locked" 0 "Unlock" ;
VAL_ 1166 ChildLckFdbckRr_B_Stat 1 "Locked" 0 "Unlock" ;
VAL_ 1165 DrOpenPrvntRl_D_Stat 3 "NotUsed" 2 "Overruled" 1 "On" 0 "Off" ;
VAL_ 1165 DrHandleInnrRl_B_Stat 1 "Pulled" 0 "AtRest" ;
VAL_ 1165 DrLatchRlMsgTxt_D_Rq 7 "Message7" 6 "Message6" 5 "Message5" 4 "Message4" 3 "Message3" 2 "Message2" 1 "Message1" 0 "NoMessage" ;
VAL_ 1165 DrLatchRl_B_Falt 1 "Yes" 0 "No" ;
VAL_ 1165 DrLatchLckRl_B_Stat 1 "Locked" 0 "Unlock" ;
VAL_ 1165 ChildLckFdbckRl_B_Stat 1 "Locked" 0 "Unlock" ;
VAL_ 1164 DrOpenPrvntFr_D_Stat 3 "NotUsed" 2 "Overruled" 1 "On" 0 "Off" ;
VAL_ 1164 DrHandleInnrFr_B_Stat 1 "Pulled" 0 "AtRest" ;
VAL_ 1164 DrLatchLckFr_B_Stat 1 "Locked" 0 "Unlock" ;
VAL_ 1164 DrLatchFrMsgTxt_D_Rq 7 "Message7" 6 "Message6" 5 "Message5" 4 "Message4" 3 "Message3" 2 "Message2" 1 "Message1" 0 "NoMessage" ;
VAL_ 1164 DrLatchFr_B_Falt 1 "Yes" 0 "No" ;
VAL_ 1163 DrOpenPrvntFl_D_Stat 3 "NotUsed" 2 "Overruled" 1 "On" 0 "Off" ;
VAL_ 1163 DrHandleInnrFl_B_Stat 1 "Pulled" 0 "AtRest" ;
VAL_ 1163 DrLatchLckFl_B_Stat 1 "Locked" 0 "Unlock" ;
VAL_ 1163 DrLatchFlMsgTxt_D_Rq 7 "Message7" 6 "Message6" 5 "Message5" 4 "Message4" 3 "Message3" 2 "Message2" 1 "Message1" 0 "NoMessage" ;
VAL_ 1163 DrLatchFl_B_Falt 1 "Yes" 0 "No" ;
VAL_ 71 immoTarget1Status 7 "Unused4" 6 "Unused3" 5 "Unused2" 4 "ENABLED_LIMITEDMOTIVE_STAR" 3 "DISABLED_RESET   " 2 "ENABLED_NONMOTIVE_START" 1 "ENABLED_MOTIVE_START" 0 "DISABLED" ;
VAL_ 71 immoTarget1Cmd 7 "Unused4" 6 "Unused3" 5 "Unused2" 4 "Unused1" 3 "TARGET1_IDBLOCK2" 2 "TARGET1_IDBLOCK1" 1 "CHALLENGE" 0 "IDLE" ;
VAL_ 1229 DrOpenPrvntRight_B_Rq 1 "True" 0 "False" ;
VAL_ 1229 IsaOnOff_D_Rq 3 "NotUsed" 2 "On" 1 "Off" 0 "Null" ;
VAL_ 1229 DrOpenPrvntLeft_B_Rq 1 "True" 0 "False" ;
VAL_ 1229 ExitNotClrRight_B_Stat 1 "True" 0 "False" ;
VAL_ 1229 ExitNotClrLeft_B_Stat 1 "True" 0 "False" ;
VAL_ 1238 TjaCanclMsgTxt_D_Dsply 15 "NotUsed_9" 14 "NotUsed_8" 13 "NotUsed_7" 12 "NotUsed_6" 11 "NotUsed_5" 10 "NotUsed_4" 9 "NotUsed_3" 8 "NotUsed_2" 7 "NotUsed_1" 6 "DriverNotSeen2" 5 "DriverNotSeen1" 4 "HandsFreeUnavailInThisArea" 3 "HandsFreeUnavailForMaxSpd" 2 "CancelledForLaneConditions" 1 "CancelledForRoadCurvature" 0 "NoMessage" ;
VAL_ 1238 TsrAslButtnPress_D_Rq 7 "NotUsed_3" 6 "NotUsed_2" 5 "NotUsed_1" 4 "Partial_Deactivation_SCF" 3 "Partial_Deactivation_SLWF" 2 "Hold_for_Activation" 1 "Hold_for_Deactivation" 0 "Null" ;
VAL_ 1238 Fba_D_Stat 3 "NotUsed" 2 "Disabled" 1 "On" 0 "Off" ;
VAL_ 1238 FbaAlrt_D_Dsply 3 "Both" 2 "Text" 1 "Graphic" 0 "Off" ;
VAL_ 1238 FbaMnu_D_Rq 3 "NotUsed" 2 "Active" 1 "Inactive" 0 "None" ;
VAL_ 1238 TjaLaneBiasEnbl_D_Stat 3 "NotUsed" 0 "Inactive" 2 "Enable" 1 "Disable" ;
VAL_ 1238 TjaLcWarn_D_Rq 7 "NotUsed_2" 6 "NotUsed_1" 5 "CancelSpeedTooLow" 4 "CancelLaneBusy" 3 "CancelNoLane" 2 "SystemCancel" 1 "DriverCancel" 0 "NoWarning" ;
VAL_ 1238 TjaLcMsgTxt_D_Rq 7 "NotUsed_2" 6 "NotUsed_1" 5 "TurnOffIndicator" 4 "AlcOff" 3 "AlcOn" 2 "LcSuggestionRight" 1 "LcSuggestionLeft" 0 "NoMessage" ;
VAL_ 1238 TjaLc_D_Stat 15 "NotUsed_7" 14 "NotUsed_6" 13 "NotUsed_5" 12 "NotUsed_4" 11 "NotUsed_3" 10 "NotUsed_2" 9 "NotUsed_1" 8 "LcActiveRight" 7 "LcActiveLeft" 6 "PreparingRight" 5 "PreparingLeft" 4 "AvailableLeftRight" 3 "AvailableRight" 2 "AvailableLeft" 1 "Standby" 0 "Off" ;
VAL_ 1238 TjaLcEnbl_D_Stat 0 "Inactive" 1 "Off" 2 "On" 3 "NotUsed" ;
VAL_ 1238 AhbcMnu_D_Rq 3 "NotUsed" 2 "Enable" 1 "Disable" 0 "Null" ;
VAL_ 1238 GfhbMnu_D_Rq 3 "EnableADB" 2 "EnableGFHB" 1 "Disable" 0 "Null" ;
VAL_ 1238 TjaLaneBias_D_Stat 7 "NotUsed" 6 "ElBiasRight" 5 "ElBiasLeft" 4 "SystemBiasRight" 3 "SystemBiasLeft" 2 "ManualBiasRight" 1 "ManualBiasLeft" 0 "NoBias" ;
VAL_ 1238 IaccVAdjReas_D_Dsply 15 "NotUsed_21" 11 "NotUsed_1" 10 "SpeedSign" 9 "LeftRamp" 8 "RightRamp" 7 "Roundabout_CCW" 6 "Roundabout_CW" 5 "LeftCurve" 4 "RightCurve" 3 "LeftTurnIntersection" 2 "RightTurnIntersection" 1 "RoadGeometryUnavailable" 0 "NoDisplay" ;
VAL_ 1238 FbaMsg_D_Rq 3 "Faulty" 2 "Unavailable" 1 "Off" 0 "Null" ;
VAL_ 895 TurnLght_D_RqRmtCtl 3 "NotUsed" 2 "Right" 1 "Left" 0 "Null" ;
VAL_ 895 RmtCtlRngSet_D_Rq 3 "NotUsed" 2 "RangeSetB" 1 "RangeSetA" 0 "None" ;
VAL_ 895 RmtCtlKeyPoll_D_Rq 3 "NotUsed" 2 "Polling" 1 "NoPolling" 0 "Null" ;
VAL_ 895 RmtCtlCntnsIn_B_Stat 1 "Available" 0 "NotAvailable" ;
VAL_ 895 RmtCtl_D_Stat 15 "Faulty" 14 "NotUsed_5" 13 "NotUsed_4" 12 "NotUsed_3" 11 "NotUsed_2" 10 "NotUsed_1" 9 "Shutdown" 8 "ManeuverFinished" 7 "ReadyForResume" 6 "Pause" 5 "Maneuvering" 4 "ReadyForManeuvering" 3 "Activation" 2 "Initialize" 1 "Preparation" 0 "Disabled" ;
VAL_ 1092 BattChrgOvrCurnt_B_Falt 1 "Yes" 0 "No" ;
VAL_ 1092 BattTracCell_U_Mx 16383 "Faulty" ;
VAL_ 1092 BattTracMnCell_Te_Actl 255 "Faulty" 254 "NoDataExists" ;
VAL_ 1092 BattTracInsAlrm_B_Stat 1 "Active" 0 "Inactive" ;
VAL_ 1092 BattTracUMx_B_Stat 1 "Active" 0 "Inactive" ;
VAL_ 1092 BattTracTeMx_B_Stat 1 "Exceeded" 0 "NotExceeded" ;
VAL_ 1092 BattTracMxCell_Te_Actl 255 "Faulty" 254 "NoDataExists" ;
VAL_ 1092 BattTracEq_B_Actl 1 "Active" 0 "Inactive" ;
VAL_ 1092 BattTracCell_U_Mn 16383 "Faulty" ;
VAL_ 1092 BattTracUMn_B_Stat 1 "Active" 0 "Inactive" ;
VAL_ 1092 BattTracUAlrm_B_Stat 1 "Active" 0 "Inactive" ;
VAL_ 1092 BattTracTeMn_B_Stat 1 "Exceeded" 0 "NotExceeded" ;
VAL_ 1092 BattTracInsltn_R_Actl 255 "Faulty" ;
VAL_ 1236 ApaSlotRight3_D_Stat 7 "NotUsed_3" 6 "NotUsed_2" 5 "NotUsed_1" 4 "IPeReady" 3 "IPeFound" 2 "IPaReady" 1 "IPaFound" 0 "None" ;
VAL_ 1236 ApaSlotRight3_B_Altr 1 "Available" 0 "NotAvailable" ;
VAL_ 1236 ApaSlotRight2_D_Stat 7 "NotUsed_3" 6 "NotUsed_2" 5 "NotUsed_1" 4 "IPeReady" 3 "IPeFound" 2 "IPaReady" 1 "IPaFound" 0 "None" ;
VAL_ 1236 ApaSlotRight2_B_Altr 1 "Available" 0 "NotAvailable" ;
VAL_ 1236 ApaSlotRight1_D_Stat 7 "NotUsed_3" 6 "NotUsed_2" 5 "NotUsed_1" 4 "IPeReady" 3 "IPeFound" 2 "IPaReady" 1 "IPaFound" 0 "None" ;
VAL_ 1236 ApaSlotRight1_B_Altr 1 "Available" 0 "NotAvailable" ;
VAL_ 1236 ApaSlotRear_D_Stat 1 "True" 0 "False" ;
VAL_ 1235 ApaSlotFront_D_Stat 1 "True" 0 "False" ;
VAL_ 1235 ApaSlotLeft3_D_Stat 7 "NotUsed_3" 6 "NotUsed_2" 5 "NotUsed_1" 4 "IPeReady" 3 "IPeFound" 2 "IPaReady" 1 "IPaFound" 0 "None" ;
VAL_ 1235 ApaSlotLeft3_B_Altr 1 "Available" 0 "NotAvailable" ;
VAL_ 1235 ApaSlotLeft2_D_Stat 7 "NotUsed_3" 6 "NotUsed_2" 5 "NotUsed_1" 4 "IPeReady" 3 "IPeFound" 2 "IPaReady" 1 "IPaFound" 0 "None" ;
VAL_ 1235 ApaSlotLeft2_B_Altr 1 "Unavailable" 0 "Available" ;
VAL_ 1235 ApaSlotLeft1_D_Stat 7 "NotUsed_3" 6 "NotUsed_2" 5 "NotUsed_1" 4 "IPeReady" 3 "IPeFound" 2 "IPaReady" 1 "IPaFound" 0 "None" ;
VAL_ 1235 ApaSlotLeft1_B_Altr 1 "Unavailable" 0 "Available" ;
VAL_ 1234 RmtCtlSnsBlckg_B_Stat 1 "Yes" 0 "No" ;
VAL_ 1234 RmtCtlConfgSrc_D_Stat 7 "NotUsed_2" 6 "NotUsed_1" 5 "BPO" 4 "ApaHmi" 3 "FAP_Handover" 2 "User" 1 "None" 0 "NotDetermined" ;
VAL_ 1234 RmtCtlTrjctry_D_Avail 3 "NotUsed" 2 "Available" 1 "NotAvailable" 0 "Null" ;
VAL_ 1234 RmtCtlSns_D_Err 1 "Yes" 0 "No" ;
VAL_ 1234 RmtCtlPathPlan_D_Stat 7 "NotUsed_3" 6 "NotUsed_2" 5 "NotUsed_1" 4 "FinishedMovesExceeded" 3 "FinishedDistanceExceeded" 2 "Finished" 1 "Ongoing" 0 "None" ;
VAL_ 1234 RmtCtlPathPlan_B_Err 1 "Yes" 0 "No" ;
VAL_ 1234 RmtCtlAdas_D_Stat 7 "Paused" 6 "Abort" 5 "ManeuverFinished" 4 "EndPositionReached" 3 "Backward" 2 "Forward" 1 "ManeuverBegin" 0 "Inactive" ;
VAL_ 1234 RmtCtlAdas_B_Err 1 "Yes" 0 "No" ;
VAL_ 1233 FreeDrvRear_D_Avail 3 "NotUsed" 2 "Available" 1 "NotAvailable" 0 "Null" ;
VAL_ 1233 FreeDrvFwd_D_Avail 3 "NotUsed" 2 "Available" 1 "NotAvailable" 0 "Null" ;
VAL_ 1233 RmtCtlSnsRrCrnr_D_Stat 3 "Zone3" 2 "Zone2" 1 "Zone1" 0 "Off" ;
VAL_ 1233 RmtCtlSnsRlCrnr_D_Stat 3 "Zone3" 2 "Zone2" 1 "Zone1" 0 "Off" ;
VAL_ 1233 RmtCtlSnsRear_D_Stat 3 "Zone3" 2 "Zone2" 1 "Zone1" 0 "Off" ;
VAL_ 1233 RmtCtlSnsFront_D_Stat 3 "Zone3" 2 "Zone2" 1 "Zone1" 0 "Off" ;
VAL_ 1233 RmtCtlSnsFrCrnr_D_Stat 3 "Zone3" 2 "Zone2" 1 "Zone1" 0 "Off" ;
VAL_ 1233 RmtCtlSnsFlCrnr_D_Stat 3 "Zone3" 2 "Zone2" 1 "Zone1" 0 "Off" ;
VAL_ 1233 RmtCtlSideSnsR4_D_Stat 3 "Zone3" 2 "Zone2" 1 "Zone1" 0 "Off" ;
VAL_ 1233 RmtCtlSideSnsR3_D_Stat 3 "Zone3" 2 "Zone2" 1 "Zone1" 0 "Off" ;
VAL_ 1233 RmtCtlSideSnsR2_D_Stat 3 "Zone3" 2 "Zone2" 1 "Zone1" 0 "Off" ;
VAL_ 1233 RmtCtlSideSnsR1_D_Stat 3 "Zone3" 2 "Zone2" 1 "Zone1" 0 "Off" ;
VAL_ 1233 RmtCtlSideSnsL4_D_Stat 3 "Zone3" 2 "Zone2" 1 "Zone1" 0 "Off" ;
VAL_ 1233 RmtCtlSideSnsL3_D_Stat 3 "Zone3" 2 "Zone2" 1 "Zone1" 0 "Off" ;
VAL_ 1233 RmtCtlSideSnsL2_D_Stat 3 "Zone3" 2 "Zone2" 1 "Zone1" 0 "Off" ;
VAL_ 1233 RmtCtlSideSnsL1_D_Stat 3 "Zone3" 2 "Zone2" 1 "Zone1" 0 "Off" ;
VAL_ 1233 RmtCtlRightOrnt_D_Avail 7 "NotUsed_3" 6 "NotUsed_2" 5 "NotUsed_1" 4 "Both" 3 "Backward" 2 "Forward" 1 "None" 0 "NotDetermined" ;
VAL_ 1233 RmtCtlRight_D_Avail 3 "NotUsed" 2 "Available" 1 "NotAvailable" 0 "Null" ;
VAL_ 1233 RmtCtlRear_D_Avail 3 "NotUsed" 2 "Available" 1 "NotAvailable" 0 "Null" ;
VAL_ 1233 RmtCtlPrkMde_D_Stat 3 "NotUsed" 2 "FreeDrive" 1 "ParkIn" 0 "None" ;
VAL_ 1233 RmtCtlPrkInSlot_D_Stat 7 "NotUsed_3" 6 "NotUsed_2" 5 "NotUsed_1" 4 "Right" 3 "Left" 2 "Rear" 1 "Front" 0 "None" ;
VAL_ 1233 RmtCtlObstcl_B_Stat 1 "Yes" 0 "No" ;
VAL_ 1233 RmtCtlNxtMoveDir_D_Stat 3 "NotUsed" 2 "Backward" 1 "Forward" 0 "Null" ;
VAL_ 1233 RmtCtlMoveDir_D_Stat 3 "NotUsed" 2 "Backward" 1 "Forward" 0 "None" ;
VAL_ 1233 RmtCtlLeftOrnt_D_Avail 7 "NotUsed_3" 6 "NotUsed_2" 5 "NotUsed_1" 4 "Both" 3 "Backward" 2 "Forward" 1 "None" 0 "NotDetermined" ;
VAL_ 1233 RmtCtlLeft_D_Avail 3 "NotUsed" 2 "Available" 1 "NotAvailable" 0 "Null" ;
VAL_ 1233 RmtCtlFront_D_Avail 3 "NotUsed" 2 "Available" 1 "NotAvailable" 0 "Null" ;
VAL_ 1237 DasAttentWarn_D_Dsply 7 "NotUsed_4" 6 "NotUsed_3" 5 "NotUsed_2" 4 "NotUsed_1" 3 "EyesOffWarning_3" 2 "EyesOffWarning_2" 1 "EyesOffWarning_1" 0 "No_Warning" ;
VAL_ 1149 BattTracPerf_Pc_Dsply 255 "Faulty" 254 "NoDataExists" ;
VAL_ 1149 BattTracPerf_Pc_Actl 255 "Faulty" 254 "NoDataExists" ;
VAL_ 925 VehElEffTrip_No_Dsply 127 "Faulty" 126 "NoDataExists" ;
VAL_ 925 TripSumDrvE_Pc_Dsply 1023 "Faulty" 1022 "NoDataExists" ;
VAL_ 925 TripExtFctrE_Pc_Dsply 1023 "Faulty" 1022 "NoDataExists" ;
VAL_ 925 TripClimE_Pc_Dsply 1023 "Faulty" 1022 "NoDataExists" ;
VAL_ 925 TripBattULoE_Pc_Dsply 1023 "Faulty" 1022 "NoDataExists" ;
VAL_ 536 BrkCtlSys_D_Stat 15 "ESCDis_TCSDis" 14 "ESCDis_TCSRed" 13 "ESCDis_TCSFull" 12 "ESCDis_TCSNde" 11 "ESCRed_TCSDis" 10 "ESCRed_TCSRed" 9 "ESCRed_TCSFull" 8 "ESCRed_TCSNde" 7 "ESCFull_TCSDis" 6 "ESCFull_TCSRed" 5 "ESCFull_TCSFull" 4 "ESCFull_TCSNde" 3 "ESCNde_TCSDis" 2 "ESCNde_TCSRed" 1 "ESCNde_TCSFull" 0 "ESCNde_TCSNde" ;
VAL_ 536 BrkWhlFricRr_Tq_Actl 255 "Faulty" 254 "NoDataExists" ;
VAL_ 536 BrkWhlFricRl_Tq_Actl 255 "Faulty" 254 "NoDataExists" ;
VAL_ 536 BrkWhlFricFr_Tq_Actl 255 "Faulty" 254 "NoDataExists" ;
VAL_ 536 BrkWhlFricFl_Tq_Actl 255 "Faulty" 254 "NoDataExists" ;
VAL_ 824 DteCldCompltRoute_B_Rq 1 "Yes" 0 "No" ;
VAL_ 824 DteCldTrlrOn_B_Stat 1 "Yes" 0 "No" ;
VAL_ 824 DteCldTrlrOff_B_Stat 1 "Yes" 0 "No" ;
VAL_ 824 DteCldTraffic_B_Stat 1 "Yes" 0 "No" ;
VAL_ 824 DteCldTerrain_B_Stat 1 "Yes" 0 "No" ;
VAL_ 824 DteCldRoute_B_Stat 1 "Yes" 0 "No" ;
VAL_ 824 DteCldPayload_B_Stat 1 "Yes" 0 "No" ;
VAL_ 824 DteCldExtTe_B_Stat 1 "Yes" 0 "No" ;
VAL_ 824 DteCldDcac_B_Stat 1 "Yes" 0 "No" ;
VAL_ 824 DteCldTrip_L2_Actl 8191 "Faulty" 8190 "NoDataExists" ;
VAL_ 823 DteAcceptNew_B_Rq 1 "Yes" 0 "No" ;
VAL_ 811 SpeedoMajorUnit_D_Confg 3 "NotUsed" 2 "Kph" 1 "Mph" 0 "Null" ;
VAL_ 811 ScMnSoc_Pc_RqMnu 127 "Faulty" 126 "NoDataExists" ;
VAL_ 811 ScEnbl_D_RqMnu 3 "NotUsed" 2 "On" 1 "Off" 0 "Null" ;
VAL_ 811 OnePdlDrvButtn_B_Falt 1 "Faulted" 0 "NotFaulted" ;
VAL_ 811 OnePdlDrvButtn_B_Stat 1 "Pressed" 0 "Not_Pressed" ;
VAL_ 811 DistToStopover_L_Actl 65535 "Faulty" ;
VAL_ 811 StopoverType_D_Stat 7 "Faulty" 6 "NotUsed_1" 5 "Other" 4 "Work" 3 "Home" 2 "ChargeStation" 1 "FinalDestination" 0 "Null" ;
VAL_ 811 ExtLghtDsply_D_Stat 7 "NotUsed" 6 "PressToOn3" 5 "PressToOff3" 4 "PressToOn2" 3 "PressToOff2" 2 "PressToOn1" 1 "PressToOff1" 0 "Reset" ;
VAL_ 811 ExtLghtRight_D_RqMnu 7 "NotUsed" 6 "PressToOn3" 5 "PressToOff3" 4 "PressToOn2" 3 "PressToOff2" 2 "PressToOn1" 1 "PressToOff1" 0 "Reset" ;
VAL_ 811 AutoLghtOvrrd_B_RqDrv 1 "Allowed" 0 "NotAllowed" ;
VAL_ 811 ExtLghtRear_D_RqMnu 7 "NotUsed" 6 "PressToOn3" 5 "PressToOff3" 4 "PressToOn2" 3 "PressToOff2" 2 "PressToOn1" 1 "PressToOff1" 0 "Reset" ;
VAL_ 811 LongTermReset_B_RqMnu 1 "On" 0 "Off" ;
VAL_ 811 ExtLghtLeft_D_RqMnu 7 "NotUsed" 6 "PressToOn3" 5 "PressToOff3" 4 "PressToOn2" 3 "PressToOff2" 2 "PressToOn1" 1 "PressToOff1" 0 "Reset" ;
VAL_ 811 ExtLghtFront_D_RqMnu 7 "NotUsed" 6 "PressToOn3" 5 "PressToOff3" 4 "PressToOn2" 3 "PressToOff2" 2 "PressToOn1" 1 "PressToOff1" 0 "Reset" ;
VAL_ 811 GoTEditMnte_T_RqMnu 15 "Faulty" 14 "NoDataExists" 13 "NotUsed_2" 12 "NotUsed_1" 11 "Minute_55" 10 "Minute_50" 9 "Minute_45" 8 "Minute_40" 7 "Minute_35" 6 "Minute_30" 5 "Minute_25" 4 "Minute_20" 3 "Minute_15" 2 "Minute_10" 1 "Minute_5" 0 "Minute_0" ;
VAL_ 811 GoTEditHr_T_RqMnu 31 "Faulty" 30 "NoDataExists" ;
SIG_GROUP_ 824 DTE_SigGroup_FD1 1 : DteCldTrip_L2_Actl DteCldTraffic_B_Stat DteCldTerrain_B_Stat DteCldRoute_B_Stat DteCldCompltRoute_B_Rq DteCldTrlrOn_B_Stat DteCldTrlrOff_B_Stat DteCldExt_Eff_Actl DteCldDrv_Eff_Actl DteCldPayload_B_Stat DteCldId_No_Actl DteCldExtTe_B_Stat DteCldDcac_B_Stat DteCldClimt_Eff_Actl DteCldBattULo_Eff_Actl;
